VERSION ""

NS_ :

BS_:

BU_: HCM IPMA_ADAS PSCM GWM _delete SCCM PDM DDM GENERIC TSTR

BO_ 394 ACCDATA_3: 16 IPMA_ADAS
 SG_ AccTrgDist2_D_Dsply : 27|4@0+ (1,0) [0|15] "SED"  GWM
 SG_ AccStopRes_B_Dsply : 54|1@0+ (1,0) [0|1] "SED"  GWM
 SG_ TjaWarn_D_Rq : 50|3@0+ (1,0) [0|7] "SED"  GWM
 SG_ Tja_D_Stat : 44|3@0+ (1,0) [0|7] "SED"  GWM
 SG_ TjaMsgTxt_D_Dsply : 53|3@0+ (1,0) [0|7] "SED"  GWM
 SG_ IaccLamp_D_Rq : 46|2@0+ (1,0) [0|3] "SED"  GWM
 SG_ AccMsgTxt_D2_Rq : 31|4@0+ (1,0) [0|15] "SED"  GWM
 SG_ FcwDeny_B_Dsply : 10|1@0+ (1,0) [0|1] "SED"  GWM
 SG_ FcwMemStat_B_Actl : 13|1@0+ (1,0) [0|1] "SED"  GWM
 SG_ AccTGap_B_Dsply : 35|1@0+ (1,0) [0|1] "SED"  GWM
 SG_ CadsAlignIncplt_B_Actl : 11|1@0+ (1,0) [0|1] "SED"  GWM
 SG_ AccFllwMde_B_Dsply : 17|1@0+ (1,0) [0|1] "SED"  GWM
 SG_ CadsRadrBlck_B_Actl : 22|1@0+ (1,0) [0|1] "SED"  GWM
 SG_ CmbbPostEvnt_B_Dsply : 15|1@0+ (1,0) [0|1] "SED"  GWM
 SG_ AccStopMde_B_Dsply : 0|1@0+ (1,0) [0|1] "SED"  GWM
 SG_ FcwMemSens_D_Actl : 20|2@0+ (1,0) [0|3] "SED"  GWM
 SG_ FcwMsgTxt_D_Rq : 7|3@0+ (1,0) [0|7] "SED"  GWM
 SG_ AccWarn_D_Dsply : 39|2@0+ (1,0) [0|3] "SED"  GWM
 SG_ FcwVisblWarn_B_Rq : 47|1@0+ (1,0) [0|1] "SED"  GWM
 SG_ FcwAudioWarn_B_Rq : 8|1@0+ (1,0) [0|1] "SED"  GWM
 SG_ AccTGap_D_Dsply : 34|3@0+ (1,0) [0|7] "SED"  GWM
 SG_ AccMemEnbl_B_RqDrv : 36|1@0+ (1,0) [0|1] "SED"  GWM
 SG_ AccStopStat_D_Dsply : 41|2@0+ (1,0) [0|3] "SED"  GWM
 SG_ HaDsply_No_Cs : 63|8@0+ (1,0) [0|255] "unitless"  GWM
 SG_ HaDsply_No_Cnt : 4|4@0+ (1,0) [0|15] "unitless"  GWM

BO_ 391 ACCDATA_2: 16 IPMA_ADAS
 SG_ CmbbBrkDecel_No_Cnt : 47|4@0+ (1,0) [0|15] "unitless"  GWM
 SG_ HudDsplyIntns_No_Actl : 31|8@0+ (0.5,0) [0|100] "%"  GWM
 SG_ HudBlk3_B_Rq : 37|1@0+ (1,0) [0|1] "SED"  GWM
 SG_ HudBlk2_B_Rq : 51|1@0+ (1,0) [0|1] "SED"  GWM
 SG_ HudBlk1_B_Rq : 50|1@0+ (1,0) [0|1] "SED"  GWM
 SG_ HudFlashRate_D_Actl : 53|2@0+ (1,0) [0|3] "SED"  GWM
 SG_ CmbbBrkDecel_No_Cs : 7|8@0+ (1,0) [0|255] "unitless"  GWM
 SG_ CmbbBrkDecel_A_Rq : 12|13@0+ (0.0039,-20) [-20|11.9449] "m/s^2"  GWM
 SG_ CmbbBrkPrchg_D_Rq : 55|2@0+ (1,0) [0|3] "SED"  GWM
 SG_ CmbbBrkDecel_B_Rq : 15|1@0+ (1,0) [0|1] "SED"  GWM
 SG_ CmbbBaSens_D_Rq : 14|2@0+ (1,0) [0|3] "SED"  GWM

BO_ 390 ACCDATA: 16 IPMA_ADAS
 SG_ AccBrkTot_A_Rq : 4|13@0+ (0.0039,-20) [-20|11.9449] "m/s^2"  GWM
 SG_ AccPrpl_A_Pred : 17|10@0+ (0.01,-5) [-5|5.23] "m/s^2"  GWM
 SG_ AccVeh_V_Trg : 32|9@0+ (0.5,0) [0|255.5] "kph"  GWM
 SG_ AccBrkPrkEl_B_Rq : 38|1@0+ (1,0) [0|1] "SED"  GWM
 SG_ Cmbb_B_Enbl : 50|1@0+ (1,0) [0|1] "SED"  GWM
 SG_ CmbbOvrrd_B_RqDrv : 51|1@0+ (1,0) [0|1] "SED"  GWM
 SG_ CmbbDeny_B_Actl : 37|1@0+ (1,0) [0|1] "SED"  GWM
 SG_ CmbbEngTqMn_B_Rq : 52|1@0+ (1,0) [0|1] "SED"  GWM
 SG_ AccPrpl_A_Rq : 49|10@0+ (0.01,-5) [-5|5.23] "m/s^2"  GWM
 SG_ AccDeny_B_Rq : 53|1@0+ (1,0) [0|1] "SED"  GWM
 SG_ AccResumEnbl_B_Rq : 33|1@0+ (1,0) [0|1] "SED"  GWM
 SG_ AccCancl_B_Rq : 39|1@0+ (1,0) [0|1] "SED"  GWM
 SG_ AccBrkPrchg_B_Rq : 54|1@0+ (1,0) [0|1] "SED"  GWM
 SG_ AccBrkDecel_B_Rq : 55|1@0+ (1,0) [0|1] "SED"  GWM
 SG_ AccStopStat_B_Rq : 34|1@0+ (1,0) [0|1] "SED"  GWM
 SG_ AccAutoResum_D_Rq : 7|2@0+ (1,0) [0|3] "SED"  GWM
 SG_ AccBrkPulse_B_Rq : 36|1@0+ (1,0) [0|1] "SED"  GWM

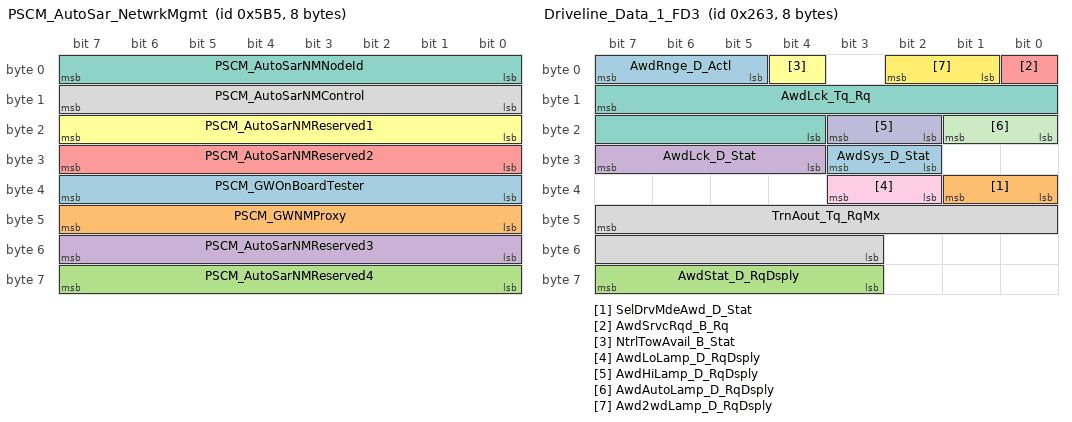
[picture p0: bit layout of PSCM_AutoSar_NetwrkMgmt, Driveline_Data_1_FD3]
BO_ 1461 PSCM_AutoSar_NetwrkMgmt: 8 PSCM
 SG_ PSCM_GWOnBoardTester : 39|8@0+ (1,0) [0|255] "unitless"  GENERIC,GWM
 SG_ PSCM_GWNMProxy : 47|8@0+ (1,0) [0|255] "unitless"  GENERIC,GWM
 SG_ PSCM_AutoSarNMReserved4 : 63|8@0+ (1,0) [0|255] "unitless"  GWM,GENERIC
 SG_ PSCM_AutoSarNMReserved3 : 55|8@0+ (1,0) [0|255] "unitless"  GENERIC,GWM
 SG_ PSCM_AutoSarNMReserved2 : 31|8@0+ (1,0) [0|255] "unitless"  GENERIC,GWM
 SG_ PSCM_AutoSarNMReserved1 : 23|8@0+ (1,0) [0|255] "unitless"  GENERIC,GWM
 SG_ PSCM_AutoSarNMNodeId : 7|8@0+ (1,0) [0|255] "unitless"  GENERIC,GWM
 SG_ PSCM_AutoSarNMControl : 15|8@0+ (1,0) [0|255] "unitless"  GWM,GENERIC

BO_ 130 EPAS_INFO: 16 PSCM
 SG_ TrlrHitchLamp_D_Rqst : 24|1@0+ (1,0) [0|1] "SED"  IPMA_ADAS,GWM
 SG_ VehVTrlrAid_B_Rq : 25|1@0+ (1,0) [0|1] "SED"  GWM
 SG_ SteEffort_D_Stat : 52|3@0+ (1,0) [0|7] "SED"  GWM
 SG_ Veh_V_RqMxTrlrAid : 63|8@0+ (0.1,0) [0|25.5] "km/h"  GWM
 SG_ SteMdule_D_Stat : 55|3@0+ (1,0) [0|7] "SED"  GWM
 SG_ SteMdule_U_Meas : 39|8@0+ (0.05,6) [6|18.7] "Volts"  GWM
 SG_ SteMdule_I_Est : 21|12@0+ (0.05,-64) [-64|140.7] "Amps"  GWM
 SG_ EPAS_Failure : 9|2@0+ (1,0) [0|3] "SED"  GWM,IPMA_ADAS
 SG_ SteeringColumnTorque : 7|8@0+ (0.0625,-8) [-8|7.8125] "Nm"  GWM,IPMA_ADAS
 SG_ SAPPAngleControlStat6 : 15|1@0+ (1,0) [0|1] "SED"  GWM,IPMA_ADAS
 SG_ SAPPAngleControlStat5 : 14|1@0+ (1,0) [0|1] "SED"  GWM,IPMA_ADAS
 SG_ SAPPAngleControlStat4 : 13|1@0+ (1,0) [0|1] "SED"  GWM,IPMA_ADAS
 SG_ SAPPAngleControlStat3 : 12|1@0+ (1,0) [0|1] "SED"  GWM,IPMA_ADAS
 SG_ SAPPAngleControlStat2 : 11|1@0+ (1,0) [0|1] "SED"  GWM,IPMA_ADAS
 SG_ SAPPAngleControlStat1 : 23|2@0+ (1,0) [0|3] "SED"  GWM,IPMA_ADAS

BO_ 1034 GGCC_Config_Mgmt_ID_1_FD3: 16 GWM
 SG_ VehicleGGCCData : 7|64@0+ (1,0) [0|1.84467E+019] "mixed"  SCCM,DDM,PDM,HCM,PSCM,IPMA_ADAS

BO_ 894 RemoteParkAssistStat_FD3: 16 GWM
 SG_ RmtCtlTrgtBody_D_Stat : 23|40@0+ (1,0) [0|1099511627775] "unitless" Vector__XXX
 SG_ RmtCtlTrgt_D_Rq : 11|2@0+ (1,0) [0|3] "SED" Vector__XXX
 SG_ RmtCtlRngSet_D_Stat : 13|2@0+ (1,0) [0|3] "SED" Vector__XXX
 SG_ RmtCtlKeySrch_D_Stat : 15|2@0+ (1,0) [0|3] "SED"  IPMA_ADAS
 SG_ RmtCtlBody_D_Stat : 4|4@0+ (1,0) [0|15] "SED"  IPMA_ADAS
 SG_ RmtCtl_D_RqBody : 7|3@0+ (1,0) [0|7] "SED" Vector__XXX

BO_ 611 Driveline_Data_1_FD3: 8 GWM
 SG_ AwdSys_D_Stat : 27|2@0+ (1,0) [0|3] "SED" Vector__XXX
 SG_ SelDrvMdeAwd_D_Stat : 33|2@0+ (1,0) [0|3] "SED" Vector__XXX
 SG_ AwdStat_D_RqDsply : 63|5@0+ (1,0) [0|31] "SED" Vector__XXX
 SG_ AwdLck_D_Stat : 31|4@0+ (1,0) [0|15] "SED" Vector__XXX
 SG_ AwdSrvcRqd_B_Rq : 0|1@0+ (1,0) [0|1] "SED" Vector__XXX
 SG_ NtrlTowAvail_B_Stat : 4|1@0+ (1,0) [0|1] "SED" Vector__XXX
 SG_ AwdLck_Tq_Rq : 15|12@0+ (1,0) [0|4093] "Nm" Vector__XXX
 SG_ TrnAout_Tq_RqMx : 47|13@0+ (1,-1250) [-1250|6941] "Nm" Vector__XXX
 SG_ AwdLoLamp_D_RqDsply : 35|2@0+ (1,0) [0|3] "SED" Vector__XXX
 SG_ AwdHiLamp_D_RqDsply : 19|2@0+ (1,0) [0|3] "SED" Vector__XXX
 SG_ AwdAutoLamp_D_RqDsply : 17|2@0+ (1,0) [0|3] "SED" Vector__XXX
 SG_ Awd2wdLamp_D_RqDsply : 2|2@0+ (1,0) [0|3] "SED" Vector__XXX
 SG_ AwdRnge_D_Actl : 7|3@0+ (1,0) [0|7] "SED"  IPMA_ADAS

BO_ 534 WheelData_FD3: 16 GWM
 SG_ WhlRotatRr_No_Cnt : 23|8@0+ (1,0) [0|255] "unitless"  IPMA_ADAS,PSCM
 SG_ WhlDirRr_D_Actl : 33|2@0+ (1,0) [0|3] "SED"  IPMA_ADAS,PSCM
 SG_ WhlDirRl_D_Actl : 39|2@0+ (1,0) [0|3] "SED"  IPMA_ADAS,PSCM
 SG_ WhlDirFr_D_Actl : 37|2@0+ (1,0) [0|3] "SED"  IPMA_ADAS,PSCM
 SG_ WhlDirFl_D_Actl : 35|2@0+ (1,0) [0|3] "SED"  IPMA_ADAS,PSCM
 SG_ WhlRotatRl_No_Cnt : 31|8@0+ (1,0) [0|255] "unitless"  IPMA_ADAS,PSCM
 SG_ WhlRotatFr_No_Cnt : 7|8@0+ (1,0) [0|255] "unitless"  IPMA_ADAS,PSCM
 SG_ WhlRotatFl_No_Cnt : 15|8@0+ (1,0) [0|255] "unitless"  IPMA_ADAS,PSCM

BO_ 533 APIM_Send_Signals_2_FD3: 8 GWM
 SG_ ExtLghtRvrseOn_B_Rq : 58|1@0+ (1,0) [0|1] "SED" Vector__XXX
 SG_ ClrExitAsstEnbl_D_RqMnu : 60|2@0+ (1,0) [0|3] "SED"  IPMA_ADAS
 SG_ TrlrAidMde_D_Rq : 5|2@0+ (1,0) [0|3] "SED"  PSCM
 SG_ TCU_Init_Actvtn_St : 1|2@0+ (1,0) [0|3] "SED" Vector__XXX
 SG_ TCU_Final_Actvtn_St : 3|2@0+ (1,0) [0|3] "SED" Vector__XXX
 SG_ OtaTrg_D_Stat : 41|2@0+ (1,0) [0|3] "SED" Vector__XXX
 SG_ OnbChrgGoTTouch_D_Rq : 43|2@0+ (1,0) [0|3] "SED" Vector__XXX
 SG_ OnbChrgGoTPrcond_D_Rq : 34|2@0+ (1,0) [0|3] "SED" Vector__XXX
 SG_ OnbChrgGoTOn_D_Rq : 25|2@0+ (1,0) [0|3] "SED" Vector__XXX
 SG_ OnbChrgGoTMnte_D_Rq : 47|4@0+ (1,0) [0|15] "minute" Vector__XXX
 SG_ OnbChrgGoTHr_T_Rq : 39|5@0+ (1,0) [0|29] "hour" Vector__XXX
 SG_ OnbChrgGoTExtHtr_D_Rq : 27|2@0+ (1,0) [0|3] "SED" Vector__XXX
 SG_ OnbChrgGoTElement_D_Rq : 31|4@0+ (1,0) [0|15] "unitless" Vector__XXX
 SG_ OnbChrgGoTDelete_B_Rq : 17|1@0+ (1,0) [0|1] "SED" Vector__XXX
 SG_ OnbChrgClearAll_B_Rq : 18|1@0+ (1,0) [0|1] "SED" Vector__XXX
 SG_ PaakMyKey_D_Rq : 7|2@0+ (1,0) [0|3] "SED" Vector__XXX
 SG_ DcacPw_D_Rq : 62|2@0+ (1,0) [0|3] "SED" Vector__XXX
 SG_ DcacPwReset_B_Rq : 63|1@0+ (1,0) [0|1] "SED" Vector__XXX
 SG_ AutoEpbZoomView_B_Stat : 32|1@0+ (1,0) [0|1] "SED" Vector__XXX
 SG_ AutoEpbButtn_B_Stat : 19|1@0+ (1,0) [0|1] "SED" Vector__XXX
 SG_ TrlrAlarmButtn_B_Stat : 50|1@0+ (1,0) [0|1] "SED" Vector__XXX
 SG_ LghtAmbDrvMde_D_Rq : 49|2@0+ (1,0) [0|3] "SED" Vector__XXX
 SG_ DcacPwLoButtn_B_Stat : 13|1@0+ (1,0) [0|1] "SED" Vector__XXX
 SG_ DcacPwOffButtn_B_Stat : 12|1@0+ (1,0) [0|1] "SED" Vector__XXX
 SG_ DcacPwHiButtn_B_Stat : 14|1@0+ (1,0) [0|1] "SED" Vector__XXX
 SG_ DcacPwResetButtn_B_Stat : 11|1@0+ (1,0) [0|1] "SED" Vector__XXX
 SG_ DcacPwButtn_B_Falt : 15|1@0+ (1,0) [0|1] "SED" Vector__XXX
 SG_ DcacMdeButtn_B_Stat : 8|1@0+ (1,0) [0|1] "SED" Vector__XXX
 SG_ DcacGfciTestBttn_B_Stat : 9|1@0+ (1,0) [0|1] "SED" Vector__XXX
 SG_ OnbChrgGoTUpdate_B_Rq : 16|1@0+ (1,0) [0|1] "SED" Vector__XXX
 SG_ DcacPwButtn_B_Stat : 10|1@0+ (1,0) [0|1] "SED" Vector__XXX
 SG_ TrlrHitch_D_RqMnu : 23|4@0+ (1,0) [0|15] "SED"  IPMA_ADAS
 SG_ TrlrBrkGain_No_Rq : 55|5@0+ (0.5,0) [0|15.5] "unitless" Vector__XXX

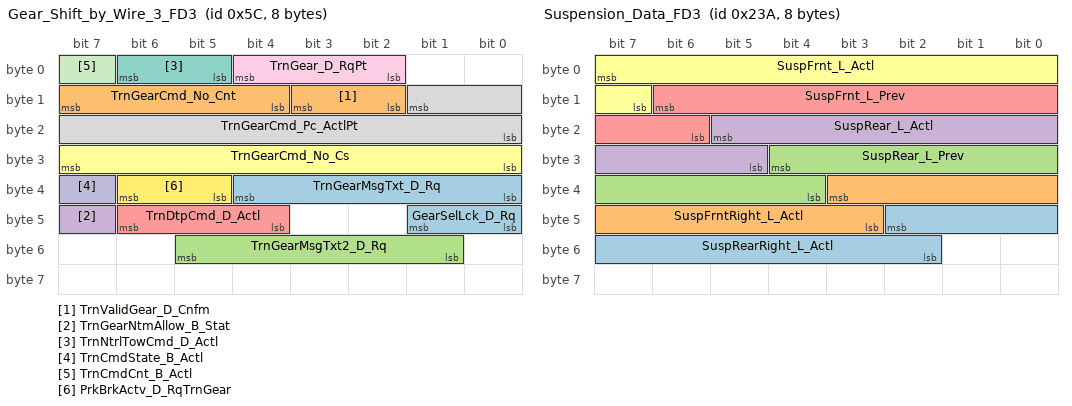
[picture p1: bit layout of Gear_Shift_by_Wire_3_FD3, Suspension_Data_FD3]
BO_ 92 Gear_Shift_by_Wire_3_FD3: 8 GWM
 SG_ GearSelLck_D_Rq : 41|2@0+ (1,0) [0|3] "SED"  _delete
 SG_ TrnValidGear_D_Cnfm : 11|2@0+ (1,0) [0|3] "SED"  _delete
 SG_ TrnGearMsgTxt2_D_Rq : 53|5@0+ (1,0) [0|31] "SED" Vector__XXX
 SG_ TrnGearNtmAllow_B_Stat : 47|1@0+ (1,0) [0|1] "SED" Vector__XXX
 SG_ TrnDtpCmd_D_Actl : 46|3@0+ (1,0) [0|7] "SED" Vector__XXX
 SG_ TrnGearCmd_No_Cs : 31|8@0+ (1,0) [0|255] "unitless" Vector__XXX
 SG_ TrnNtrlTowCmd_D_Actl : 6|2@0+ (1,0) [0|3] "SED"  IPMA_ADAS
 SG_ TrnGearCmd_Pc_ActlPt : 9|10@0+ (0.1,0) [0|102.2] "percent duty cycle" Vector__XXX
 SG_ TrnGear_D_RqPt : 4|3@0+ (1,0) [0|7] "SED" Vector__XXX
 SG_ TrnCmdState_B_Actl : 39|1@0+ (1,0) [0|1] "SED" Vector__XXX
 SG_ TrnCmdCnt_B_Actl : 7|1@0+ (1,0) [0|1] "unitless" Vector__XXX
 SG_ PrkBrkActv_D_RqTrnGear : 38|2@0+ (1,0) [0|3] "SED" Vector__XXX
 SG_ TrnGearMsgTxt_D_Rq : 36|5@0+ (1,0) [0|31] "SED" Vector__XXX
 SG_ TrnGearCmd_No_Cnt : 15|4@0+ (1,0) [0|15] "unitless" Vector__XXX

BO_ 1848 TesterPhysicalResPSCM: 64 PSCM
 SG_ TesterPhysicalResPSCM : 7|64@0+ (1,0) [0|1.84467E+019] "unitless"  TSTR

BO_ 1840 TesterPhysicalReqPSCM: 64 TSTR
 SG_ TesterPhysicalReqPSCM : 7|64@0+ (1,0) [0|1.84467E+019] "unitless"  PSCM

BO_ 570 Suspension_Data_FD3: 8 GWM
 SG_ SuspRearRight_L_Actl : 42|9@0+ (0.782779,-200) [-200|199.21729] "millimeter" Vector__XXX
 SG_ SuspFrntRight_L_Actl : 35|9@0+ (0.782779,-200) [-200|199.21729] "millimeter" Vector__XXX
 SG_ SuspRear_L_Prev : 28|9@0+ (0.782779,-200) [-200|199.21729] "millimeter"  HCM
 SG_ SuspRear_L_Actl : 21|9@0+ (0.782779,-200) [-200|199.21729] "millimeter"  HCM
 SG_ SuspFrnt_L_Prev : 14|9@0+ (0.782779,-200) [-200|199.21729] "millimeter"  HCM
 SG_ SuspFrnt_L_Actl : 7|9@0+ (0.782779,-200) [-200|199.21729] "millimeter"  HCM

BO_ 131 Steering_Data: 8 SCCM
 SG_ HeadLghtHiCtrl_D_RqAhb : 43|3@0+ (1,0) [0|7] "SED"  GWM,HCM,GENERIC
 SG_ AhbStat_B_Dsply : 33|1@0+ (1,0) [0|1] "SED"  GWM
 SG_ WiprFrontSwtch_D_Stat : 47|4@0+ (1,0) [0|15] "SED"  GWM
 SG_ HeadLghtHiOn_B_StatAhb : 34|1@0+ (1,0) [0|1] "SED"  GWM,IPMA_ADAS
 SG_ HeadLghtHiFlash_D_Actl : 36|2@0+ (1,0) [0|3] "SED"  GWM,IPMA_ADAS,HCM,GENERIC
 SG_ TjaButtnOnOffPress : 40|1@0+ (1,0) [0|1] "SED"  IPMA_ADAS,GWM
 SG_ AccButtnGapTogglePress : 32|1@0+ (1,0) [0|1] "SED"  GWM,IPMA_ADAS
 SG_ WiprFront_D_Stat : 3|4@0+ (1,0) [0|15] "SED"  HCM,GWM,IPMA_ADAS
 SG_ TurnLghtSwtch_D_Stat : 5|2@0+ (1,0) [0|3] "SED"  IPMA_ADAS,HCM,GWM,PSCM
 SG_ LghtAmb_D_Sns : 15|3@0+ (1,0) [0|7] "SED"  IPMA_ADAS,HCM,GWM
 SG_ AccButtnGapIncPress : 11|1@0+ (1,0) [0|1] "SED"  GWM,IPMA_ADAS
 SG_ AccButtnGapDecPress : 12|1@0+ (1,0) [0|1] "SED"  GWM,IPMA_ADAS
 SG_ AslButtnOnOffPress : 9|1@0+ (1,0) [0|1] "SED"  GWM
 SG_ AslButtnOnOffCnclPress : 10|1@0+ (1,0) [0|1] "SED"  GWM
 SG_ CcButtnOnPress : 37|1@0+ (1,0) [0|1] "SED"  GWM,IPMA_ADAS
 SG_ CcButtnOnOffPress : 38|1@0+ (1,0) [0|1] "SED"  GWM,IPMA_ADAS
 SG_ CcButtnOnOffCnclPress : 39|1@0+ (1,0) [0|1] "SED"  GWM,IPMA_ADAS
 SG_ CcButtnOffPress : 24|1@0+ (1,0) [0|1] "SED"  GWM,IPMA_ADAS
 SG_ CcAsllButtnResPress : 25|1@0+ (1,0) [0|1] "SED"  GWM,IPMA_ADAS
 SG_ CcAslButtnSetPress : 26|1@0+ (1,0) [0|1] "SED"  GWM
 SG_ CcAslButtnSetIncPress : 27|1@0+ (1,0) [0|1] "SED"  GWM,IPMA_ADAS
 SG_ CcAslButtnSetDecPress : 28|1@0+ (1,0) [0|1] "SED"  GWM,IPMA_ADAS
 SG_ CcAslButtnResIncPress : 29|1@0+ (1,0) [0|1] "SED"  GWM,IPMA_ADAS
 SG_ CcAslButtnResDecPress : 30|1@0+ (1,0) [0|1] "SED"  GWM
 SG_ CcAslButtnOnPress : 31|1@0+ (1,0) [0|1] "SED"  GWM,IPMA_ADAS
 SG_ CcAslButtnOnOffCncl : 16|1@0+ (1,0) [0|1] "SED"  GWM
 SG_ CcAslButtnOffCnclPress : 17|1@0+ (1,0) [0|1] "SED"  GWM
 SG_ CcAslButtnIndxIncPress : 18|1@0+ (1,0) [0|1] "SED"  GWM
 SG_ CcAslButtnIndxDecPress : 19|1@0+ (1,0) [0|1] "SED"  GWM
 SG_ CcAslButtnDeny_B_Actl : 20|1@0+ (1,0) [0|1] "SED"  GWM,IPMA_ADAS
 SG_ CcAslButtnCnclResPress : 21|1@0+ (1,0) [0|1] "SED"  GWM,IPMA_ADAS
 SG_ CcAslButtnCnclPress : 8|1@0+ (1,0) [0|1] "SED"  GWM,IPMA_ADAS
 SG_ LaSwtchPos_D_Stat : 23|2@0+ (1,0) [0|3] "SED"  GWM,IPMA_ADAS,GENERIC

BO_ 125 BrakeSnData_4_FD3: 16 GWM
 SG_ VehRolComp_W_Actl : 51|12@0+ (0.03663,-75) [-75|74.92659] "degrees/sec"  PSCM
 SG_ VehVertComp_A_Actl : 45|10@0+ (0.035,-17.9) [-17.9|17.835] "m/s^2"  PSCM
 SG_ BrkTotTqRqArb_No_Cs : 23|8@0+ (1,0) [0|255] "unitless" Vector__XXX
 SG_ BrkTotTqRqArb_No_Cnt : 31|4@0+ (1,0) [0|15] "unitless" Vector__XXX
 SG_ BrkTot_Tq_RqArb : 4|13@0+ (4,0) [0|32756] "Nm"  HCM,PSCM,IPMA_ADAS
 SG_ BrkTot_Tq_Actl : 27|13@0+ (4,0) [0|32756] "Nm"  PSCM
 SG_ HsaStat_D_Actl : 7|3@0+ (1,0) [0|7] "SED" Vector__XXX

BO_ 119 BrakeSnData_3_FD3: 16 GWM
 SG_ VehTrvlDir_D_Stat : 23|3@0+ (1,0) [0|7] "SED" Vector__XXX
 SG_ VehOverGnd_V_Est : 7|16@0+ (0.01,0) [0|655.33] "kph"  IPMA_ADAS,PSCM
 SG_ VehLongComp_A_Actl : 49|10@0+ (0.035,-17.9) [-17.9|17.835] "m/s^2"  HCM,PSCM
 SG_ VehLatComp_A_Actl : 43|10@0+ (0.035,-17.9) [-17.9|17.835] "m/s^2"  HCM,PSCM
 SG_ VehYawComp_W_Actl : 19|12@0+ (0.03663,-75) [-75|74.92659] "deg/s"  IPMA_ADAS,PSCM

BO_ 118 BrakeSnData_5_FD3: 16 GWM
 SG_ BrkCtrFnd_B_Stat : 39|1@0+ (1,0) [0|1] "SED"  GENERIC
 SG_ BrkTerrMdeChng_D_Rdy : 54|3@0+ (1,0) [0|7] "SED"  GENERIC
 SG_ BrkTerrMde_D_Actl : 38|3@0+ (1,0) [0|7] "SED"  GENERIC
 SG_ EmgcyBrkLamp_D_Rq : 21|2@0+ (1,0) [0|3] "SED"  GENERIC
 SG_ StopLamp_B_RqBrk : 7|1@0+ (1,0) [0|1] "SED"  GENERIC
 SG_ SteWhlCompAnEst_D_Qf : 23|2@0+ (1,0) [0|3] "SED" Vector__XXX
 SG_ SteWhlComp_An_Est : 6|15@0+ (0.1,-1600) [-1600|1676.7] "degrees" Vector__XXX

BO_ 1071 Engine_Clutch_Data_FD3: 16 GWM
 SG_ EngAout_N_Dsply : 52|13@0+ (2,0) [0|16382] "rpm"  _delete
 SG_ EngMnfld3_P_Actl : 47|8@0+ (10,0) [0|2530] "milibar"  _delete
 SG_ EngAoutIdl_N_Ntrl : 31|11@0+ (2,0) [0|4094] "rpm"  _delete
 SG_ CluPdl_PcRate_Actl : 7|8@0+ (0.04,-5) [-5|5.2] "%/ms" Vector__XXX
 SG_ CluPdlPosPcMeas_D_Qf : 11|2@0+ (1,0) [0|3] "SED"  HCM
 SG_ CluPdlPos_Pc_Meas : 9|10@0+ (0.1,0) [0|102.3] "%"  HCM

BO_ 942 ParkAid_Data2: 16 IPMA_ADAS
 SG_ ApaOffOptnSel_B_Avail : 51|1@0+ (1,0) [0|1] "SED"  GWM
 SG_ ApaSlotOption_B_Avail : 43|1@0+ (1,0) [0|1] "SED"  GWM
 SG_ ApaSlotAlrtSet_B_Stat : 44|1@0+ (1,0) [0|1] "SED"  GWM
 SG_ ApaSlotAlrt_B_Rq : 45|1@0+ (1,0) [0|1] "SED"  GWM
 SG_ ApaRmtFeatSel_B_Avail : 46|1@0+ (1,0) [0|1] "SED"  GWM
 SG_ ApaParkOutSel_B_Avail : 47|1@0+ (1,0) [0|1] "SED"  GWM
 SG_ ApaSys_D2_Stat : 35|4@0+ (1,0) [0|15] "SED"  GWM
 SG_ ApaSlotTrgt_D_Stat : 39|4@0+ (1,0) [0|15] "SED"  GWM
 SG_ ApaParkInSel_B_Avail : 24|1@0+ (1,0) [0|1] "SED"  GWM
 SG_ ApaMsgTxt_D2_Stat : 28|4@0+ (1,0) [0|15] "SED"  GWM
 SG_ ApaDynmcSlot_B_Stat : 29|1@0+ (1,0) [0|1] "SED"  GWM
 SG_ ApaDisplayMode_D_Stat : 31|2@0+ (1,0) [0|3] "SED"  GWM
 SG_ ApaControlMode_D_Stat : 16|1@0+ (1,0) [0|1] "SED"  GWM
 SG_ PrkBrkElRleas_B_RqApa : 50|1@0+ (1,0) [0|1] "SED"  GWM
 SG_ PrkAidAcsyRear_D_Stat : 18|2@0+ (1,0) [0|3] "SED"  GWM
 SG_ PrkAidAcsyFront_D_Stat : 20|2@0+ (1,0) [0|3] "SED"  GWM
 SG_ PrkAidRdiusRight_L_Dsply : 15|8@0+ (1,0) [0|255] "unitless"  GWM
 SG_ PrkAidRdiusLeft_L_Dsply : 7|8@0+ (1,0) [0|255] "unitless"  GWM
 SG_ PrkAidDrvDir_D_Stat : 23|3@0+ (1,0) [0|7] "SED"  GWM
 SG_ ApaDrvRq2MsgTxt_D_Rq : 55|4@0+ (1,0) [0|15] "SED"  GWM
 SG_ ApaDrvRq1MsgTxt_D_Rq : 42|3@0+ (1,0) [0|7] "SED"  GWM

BO_ 939 ParkAid_Aud_Warn_Stat2: 16 IPMA_ADAS
 SG_ DrTgateMde_D_Stat : 49|2@0+ (1,0) [0|3] "SED"  GWM
 SG_ SidePrkSnsR4_D_Stat : 55|4@0+ (1,0) [0|15] "SED"  GWM
 SG_ SidePrkSnsR3_D_Stat : 47|4@0+ (1,0) [0|15] "SED"  GWM
 SG_ SidePrkSnsL4_D_Stat : 43|4@0+ (1,0) [0|15] "SED"  GWM
 SG_ SidePrkSnsL3_D_Stat : 37|4@0+ (1,0) [0|15] "SED"  GWM
 SG_ PrkAidChime_D_Stat : 4|2@0+ (1,0) [0|3] "SED"  GWM
 SG_ PrkAidSnsRlCntr_D_Stat : 15|4@0+ (1,0) [0|15] "SED"  GWM
 SG_ PrkAidSnsRrCrnr_D_Stat : 31|4@0+ (1,0) [0|15] "SED"  GWM
 SG_ PrkAidSnsRrCntr_D_Stat : 19|4@0+ (1,0) [0|15] "SED"  GWM
 SG_ PrkAidSnsRlCrnr_D_Stat : 11|4@0+ (1,0) [0|15] "SED"  GWM
 SG_ PrkAidRear_D_Stat : 39|2@0+ (1,0) [0|3] "SED"  GWM
 SG_ PrkAidFront_D_Stat : 2|2@0+ (1,0) [0|3] "SED"  GWM
 SG_ PrkAid_D_Falt : 7|3@0+ (1,0) [0|7] "SED"  GWM
 SG_ ApaLongCtrlEnbl_D_Rq : 0|1@0+ (1,0) [0|1] "SED"  GWM
 SG_ ApaBrk_A_Rq : 63|8@0+ (0.05,-12.75) [-12.75|0] "m/sec^2"  GWM
 SG_ PrkAidLamp_D_Rq : 33|2@0+ (1,0) [0|3] "SED"  GWM
 SG_ ApaBrk_D_Rq : 51|2@0+ (1,0) [0|3] "SED"  GWM
 SG_ ResPrkAidSnsRrSide_D_Stat : 27|4@0+ (1,0) [0|15] "SED"  GWM
 SG_ ResPrkAidSnsRlSide_D_Stat : 23|4@0+ (1,0) [0|15] "SED"  GWM

BO_ 938 ParkAid_Aud_Warn_Stat: 16 IPMA_ADAS
 SG_ SidePrkSnsR2_D_Stat : 59|4@0+ (1,0) [0|15] "SED"  GWM
 SG_ SidePrkSnsR1_D_Stat : 63|4@0+ (1,0) [0|15] "SED"  GWM
 SG_ SidePrkSnsL2_D_Stat : 51|4@0+ (1,0) [0|15] "SED"  GWM
 SG_ ApaMde_D_Stat : 23|3@0+ (1,0) [0|7] "SED"  GWM
 SG_ ApaActvSd_D_Actl : 14|2@0+ (1,0) [0|3] "SED"  GWM
 SG_ PrkAidSwtch_B_Stat : 8|1@0+ (1,0) [0|1] "SED"  GWM
 SG_ ApaMde_D_Avail : 12|4@0+ (1,0) [0|15] "SED"  GWM
 SG_ PrkAidSnsFrCrnr_D_Stat : 47|4@0+ (1,0) [0|15] "SED"  GWM
 SG_ PrkAidSnsFrCntr_D_Stat : 35|4@0+ (1,0) [0|15] "SED"  GWM
 SG_ PrkAidSnsFlCrnr_D_Stat : 27|4@0+ (1,0) [0|15] "SED"  GWM
 SG_ PrkAidSnsFlCntr_D_Stat : 31|4@0+ (1,0) [0|15] "SED"  GWM
 SG_ PrkBrkEl_B_RqFap : 20|1@0+ (1,0) [0|1] "SED"  GWM
 SG_ RpaChime_D_Rq : 7|4@0+ (1,0) [0|15] "SED"  GWM
 SG_ FpaChime_D_Rq : 3|4@0+ (1,0) [0|15] "SED"  GWM
 SG_ PrkAidMsgTxt_D_Rq : 19|4@0+ (1,0) [0|15] "SED"  PSCM,GWM
 SG_ SidePrkSnsL1_D_Stat : 55|4@0+ (1,0) [0|15] "SED"  GWM
 SG_ PrkAidAudioMute_B_Rq : 15|1@0+ (1,0) [0|1] "SED"  GWM

BO_ 937 ParkAid_Data_2: 16 IPMA_ADAS
 SG_ Veh_V_RqFap : 31|8@0+ (0.1,0) [0|25.5] "km/h"  GWM
 SG_ TrnRngDRqFap_No_Cs : 23|8@0+ (1,0) [0|255] "unitless"  GWM
 SG_ TrnRngDRqFap_No_Cnt : 15|4@0+ (1,0) [0|15] "unitless"  GWM
 SG_ TrnRng_D_RqFap : 11|3@0+ (1,0) [0|7] "SED"  GWM
 SG_ FapLcDistToObj_L_Actl : 7|8@0+ (0.01,0) [0|2.53] "meter"  GWM

BO_ 936 ParkAid_Data: 16 IPMA_ADAS
 SG_ ApaSys_D_Stat : 61|3@0+ (1,0) [0|7] "SED"  PSCM,GWM
 SG_ ApaSteWhl_D_RqDrv : 63|2@0+ (1,0) [0|3] "SED"  GWM
 SG_ ApaSteScanMde_D_Stat : 49|2@0+ (1,0) [0|3] "SED"  GWM
 SG_ ApaSelSapp_D_Stat : 51|2@0+ (1,0) [0|3] "SED"  GWM
 SG_ ApaSelPpa_D_Stat : 53|2@0+ (1,0) [0|3] "SED"  GWM
 SG_ ApaSelPoa_D_Stat : 55|2@0+ (1,0) [0|3] "SED"  GWM
 SG_ ApaScan_D_Stat : 41|2@0+ (1,0) [0|3] "SED"  GWM
 SG_ ApaLongCtl_D_RqDrv : 44|3@0+ (1,0) [0|7] "SED"  GWM
 SG_ ApaGearShif_D_RqDrv : 47|3@0+ (1,0) [0|7] "SED"  GWM
 SG_ ApaActvSide2_D_Stat : 33|2@0+ (1,0) [0|3] "SED"  GWM
 SG_ ApaAcsy_D_RqDrv : 36|3@0+ (1,0) [0|7] "SED"  GWM
 SG_ ApaTrgtDist_D_Stat : 11|4@0+ (1,0) [0|15] "SED"  GWM
 SG_ ApaMsgTxt_D_Rq : 15|4@0+ (1,0) [0|15] "SED"  GWM
 SG_ ApaChime_D_Rq : 39|3@0+ (1,0) [0|7] "SED"  GWM
 SG_ SAPPStatusCoding : 7|8@0+ (1,0) [0|255] "unitless"  PSCM,GWM
 SG_ EPASExtAngleStatReq : 23|1@0+ (1,0) [0|1] "SED"  PSCM,GWM
 SG_ ExtSteeringAngleReq2 : 22|15@0+ (0.1,-1000) [-1000|2276.5] "degrees"  PSCM,GWM
 SG_ ApaButtnPrssd_B_Stat : 58|1@0+ (1,0) [0|1] "SED"  PSCM,GWM

BO_ 154 TripResetSyncMessage_FD3: 12 GWM
 SG_ TronTripCnt_No_Actl : 7|23@0+ (1,0) [0|8388605] "unitless"  DDM,PDM,HCM,IPMA_ADAS,PSCM
 SG_ TronResetCnt_No_Actl : 16|22@0+ (1,0) [0|4194301] "unitless"  DDM,PDM,HCM,IPMA_ADAS,PSCM

BO_ 2614099160 SymKeyFuncGWM_ECG_FD3: 64 GWM
 SG_ SymKeyFuncGWM_ECG : 7|29@0+ (1,0) [0|536870911] "unitless"  HCM,DDM,PDM,IPMA_ADAS,PSCM,SCCM

BO_ 2613272609 SymKeyPhysIPMAtoGWM_ECG: 64 IPMA_ADAS
 SG_ SymKeyPhysIPMAtoGWM_ECG : 7|29@0+ (1,0) [0|536870911] "unitless"  GWM

BO_ 2613085400 SymKeyPhysGWM_ECGtoIPMA: 64 GWM
 SG_ SymKeyPhysGWM_ECGtoIPMA : 7|29@0+ (1,0) [0|536870911] "unitless"  IPMA_ADAS

BO_ 2613272624 SymKeyPhysPSCMtoGWM_ECG: 64 PSCM
 SG_ SymKeyPhysPSCMtoGWM_ECG : 7|29@0+ (1,0) [0|536870911] "unitless"  GWM

BO_ 2613100760 SymKeyPhysGWM_ECGtoPSCM: 64 GWM
 SG_ SymKeyPhysGWM_ECGtoPSCM : 7|29@0+ (1,0) [0|536870911] "unitless"  PSCM

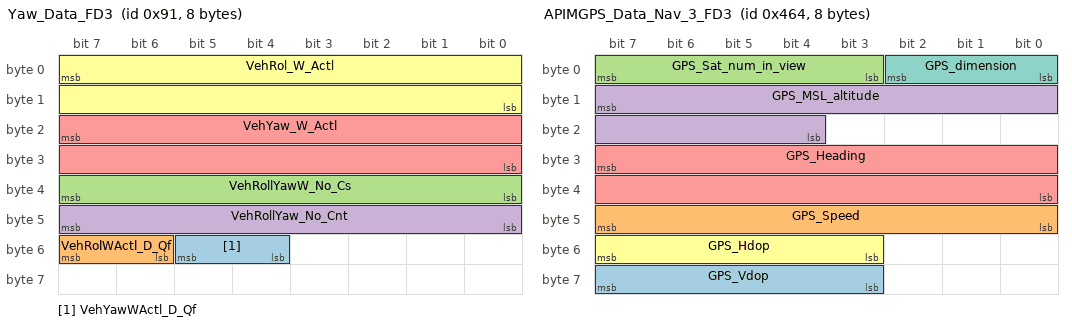
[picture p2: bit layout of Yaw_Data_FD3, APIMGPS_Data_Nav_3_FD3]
BO_ 145 Yaw_Data_FD3: 8 GWM
 SG_ VehYawWActl_D_Qf : 53|2@0+ (1,0) [0|3] "SED"  HCM,IPMA_ADAS
 SG_ VehRolWActl_D_Qf : 55|2@0+ (1,0) [0|3] "SED"  IPMA_ADAS
 SG_ VehRollYawW_No_Cs : 39|8@0+ (1,0) [0|255] "unitless"  IPMA_ADAS
 SG_ VehRollYaw_No_Cnt : 47|8@0+ (1,0) [0|255] "unitless"  IPMA_ADAS
 SG_ VehYaw_W_Actl : 23|16@0+ (0.0002,-6.5) [-6.5|6.6066] "rad/s"  HCM,IPMA_ADAS,PSCM
 SG_ VehRol_W_Actl : 7|16@0+ (0.0002,-6.5) [-6.5|6.6066] "rad/s"  IPMA_ADAS,PSCM

BO_ 2612224099 PARSEDPushSODRtoGWM_ECG: 8 IPMA_ADAS
 SG_ PARSEDPushSODRtoGWM_ECG : 7|29@0+ (1,0) [0|536870911] "unitless"  GWM

BO_ 2612224098 PARSEDPushSODLtoGWM_ECG: 8 IPMA_ADAS
 SG_ PARSEDPushSODLtoGWM_ECG : 7|29@0+ (1,0) [0|536870911] "unitless"  GWM

BO_ 2612224070 PARSEDPushSODCMDtoECG: 8 IPMA_ADAS
 SG_ PARSEDPushSODCMDtoECG : 7|29@0+ (1,0) [0|536870911] "unitless"  GWM

BO_ 535 WheelSpeed_FD3: 16 GWM
 SG_ WhlRr_W_Meas : 54|15@0+ (0.01,0) [0|327.65] "rad/s"  IPMA_ADAS,PSCM
 SG_ WhlRl_W_Meas : 38|15@0+ (0.01,0) [0|327.65] "rad/s"  IPMA_ADAS,PSCM
 SG_ WhlFr_W_Meas : 22|15@0+ (0.01,0) [0|327.65] "rad/s"  IPMA_ADAS,PSCM
 SG_ WhlFl_W_Meas : 6|15@0+ (0.01,0) [0|327.65] "rad/s"  IPMA_ADAS,PSCM

BO_ 2612224069 PARSEDPushSODCMCtoECG: 8 IPMA_ADAS
 SG_ PARSEDPushSODCMCtoECG : 7|29@0+ (1,0) [0|536870911] "unitless"  GWM

BO_ 2612224048 PARSEDPushPSCMtoGWM_ECG: 8 PSCM
 SG_ PARSEDPushPSCMtoGWM_ECG : 7|29@0+ (1,0) [0|536870911] "unitless"  GWM

BO_ 2612224033 PARSEDPushIPMAtoGWM_ECG: 8 IPMA_ADAS
 SG_ PARSEDPushIPMAtoGWM_ECG : 7|29@0+ (1,0) [0|536870911] "unitless"  GWM

BO_ 2612224113 PARSEDPushHCMtoGWM_ECG: 8 HCM
 SG_ PARSEDPushHCMtoGWM_ECG : 7|29@0+ (1,0) [0|536870911] "unitless"  GWM

BO_ 2612104408 PARSEDPushFcGWM_ECGtoSODR: 8 GWM
 SG_ PARSEDPushFcGWM_ECGtoSODR : 7|29@0+ (1,0) [0|536870911] "unitless"  IPMA_ADAS

BO_ 2612103384 PARSEDPushFcGWM_ECGtoSODL: 8 GWM
 SG_ PARSEDPushFcGWM_ECGtoSODL : 7|29@0+ (1,0) [0|536870911] "unitless"  IPMA_ADAS

BO_ 2612074712 PARSEDPushFcGWMtoSODCMD: 8 GWM
 SG_ PARSEDPushFcECGtoSODCMD : 7|29@0+ (1,0) [0|536870911] "unitless"  IPMA_ADAS

BO_ 2612118744 PARSEDPushFcGWM_ECGtoHCM: 8 GWM
 SG_ PARSEDPushFcGWM_ECGtoHCM : 7|29@0+ (1,0) [0|536870911] "unitless"  HCM

BO_ 2610982104 PARSEDPhysGWM_ECGtoGSM: 64 GWM
 SG_ PARSEDPhysGWM_ECGtoGSM : 7|29@0+ (1,0) [0|536870911] "unitless" Vector__XXX

BO_ 2612052184 PARSEDPushFcGWM_ECGtoPSCM: 8 GWM
 SG_ PARSEDPushFcGWM_ECGtoPSCM : 7|29@0+ (1,0) [0|536870911] "unitless"  PSCM

BO_ 2612036824 PARSEDPushFcGWM_ECGtoIPMA: 8 GWM
 SG_ PARSEDPushFcGWM_ECGtoIPMA : 7|29@0+ (1,0) [0|536870911] "unitless"  IPMA_ADAS

BO_ 1124 APIMGPS_Data_Nav_3_FD3: 8 GWM
 SG_ GPS_Vdop : 63|5@0+ (0.2,0) [0|5.8] "unitless" Vector__XXX
 SG_ GPS_Speed : 47|8@0+ (1,0) [0|253] "MPH" Vector__XXX
 SG_ GPS_Sat_num_in_view : 7|5@0+ (1,0) [0|29] "unitless" Vector__XXX
 SG_ GPS_MSL_altitude : 15|12@0+ (10,-20460) [-20460|20470] "feet" Vector__XXX
 SG_ GPS_Heading : 31|16@0+ (0.01,0) [0|655.33] "degrees" Vector__XXX
 SG_ GPS_Hdop : 55|5@0+ (0.2,0) [0|5.8] "unitless" Vector__XXX
 SG_ GPS_dimension : 2|3@0+ (1,0) [0|7] "SED" Vector__XXX

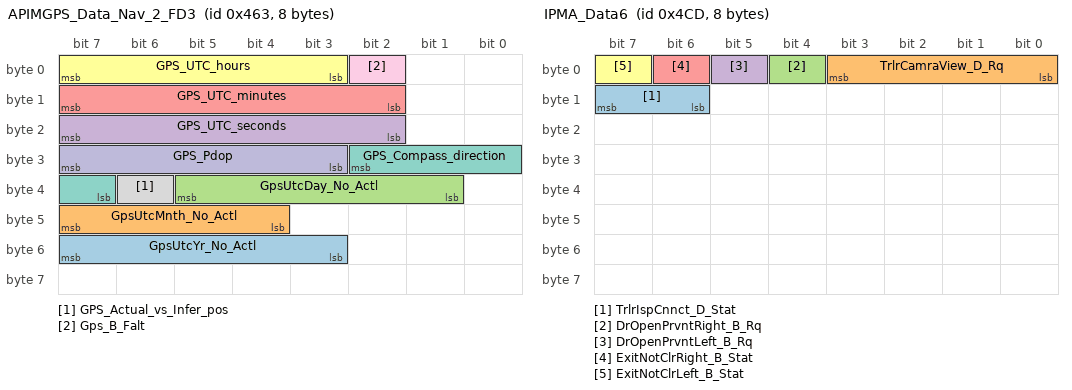
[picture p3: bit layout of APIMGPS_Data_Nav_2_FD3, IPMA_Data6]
BO_ 1123 APIMGPS_Data_Nav_2_FD3: 8 GWM
 SG_ GpsUtcYr_No_Actl : 55|5@0+ (1,2010) [2010|2040] "Year" Vector__XXX
 SG_ GpsUtcMnth_No_Actl : 47|4@0+ (1,1) [1|15] "Month" Vector__XXX
 SG_ GpsUtcDay_No_Actl : 37|5@0+ (1,1) [1|32] "day" Vector__XXX
 SG_ GPS_UTC_seconds : 23|6@0+ (1,0) [0|59] "seconds" Vector__XXX
 SG_ GPS_UTC_minutes : 15|6@0+ (1,0) [0|59] "minute" Vector__XXX
 SG_ GPS_UTC_hours : 7|5@0+ (1,0) [0|23] "Hours" Vector__XXX
 SG_ GPS_Compass_direction : 26|4@0+ (1,0) [0|15] "SED" Vector__XXX
 SG_ GPS_Actual_vs_Infer_pos : 38|1@0+ (1,0) [0|1] "SED" Vector__XXX
 SG_ Gps_B_Falt : 2|1@0+ (1,0) [0|1] "SED" Vector__XXX
 SG_ GPS_Pdop : 31|5@0+ (0.2,0) [0|5.8] "unitless" Vector__XXX

BO_ 2612030680 PARSEDPushFcGWM_ECGtoGSM: 8 GWM
 SG_ PARSEDPushFcGWM_ECGtoGSM : 7|29@0+ (1,0) [0|536870911] "unitless" Vector__XXX

BO_ 531 DesiredTorqBrk_FD3: 16 GWM
 SG_ VehStop_D_Stat : 28|2@0+ (1,0) [0|3] "SED"  IPMA_ADAS
 SG_ TracCtlPtActv_B_Actl : 31|1@0+ (1,0) [0|1] "SED"  IPMA_ADAS
 SG_ PrkBrkYwLamp_D_Rq : 38|2@0+ (1,0) [0|3] "SED" Vector__XXX
 SG_ PrkBrkRedLamp_D_Rq : 30|2@0+ (1,0) [0|3] "SED" Vector__XXX
 SG_ VehicleStationary : 39|1@0+ (1,0) [0|1] "SED" Vector__XXX
 SG_ AbsActv_B_Actl : 45|1@0+ (1,0) [0|1] "SED"  IPMA_ADAS,PSCM
 SG_ StabCtlBrkActv_B_Actl : 23|1@0+ (1,0) [0|1] "SED"  IPMA_ADAS,PSCM
 SG_ CmbbBrkPrchg_B_Actl : 59|1@0+ (1,0) [0|1] "SED"  IPMA_ADAS
 SG_ CmbbBrkDecel_B_Actl : 58|1@0+ (1,0) [0|1] "SED"  IPMA_ADAS
 SG_ CmbbBaSensInc_B_Actl : 57|1@0+ (1,0) [0|1] "SED"  IPMA_ADAS
 SG_ AccBrkWarm_B_Actl : 63|1@0+ (1,0) [0|1] "SED"  IPMA_ADAS
 SG_ AccBrkTotTqMn_B_Actl : 62|1@0+ (1,0) [0|1] "SED"  IPMA_ADAS
 SG_ AccBrkPrchgActv_B_Actl : 61|1@0+ (1,0) [0|1] "SED"  IPMA_ADAS
 SG_ AccBrkDis_B_Actl : 44|1@0+ (1,0) [0|1] "SED"  IPMA_ADAS
 SG_ AccBrkDeny_B_Actl : 42|1@0+ (1,0) [0|1] "SED"  IPMA_ADAS
 SG_ AccBrkActv_B_Actl : 43|1@0+ (1,0) [0|1] "SED"  IPMA_ADAS
 SG_ PrplDrgCtlActv_B_Actl : 46|1@0+ (1,0) [0|1] "SED" Vector__XXX
 SG_ PrplWhlTot_Tq_RqMx : 7|16@0+ (4,-131072) [-131072|131068] "Nm" Vector__XXX
 SG_ CmbbBrkDis_B_Actl : 56|1@0+ (1,0) [0|1] "SED"  PSCM,IPMA_ADAS
 SG_ CmbbDeny_B_ActlBrk : 60|1@0+ (1,0) [0|1] "SED"  PSCM,IPMA_ADAS
 SG_ CcDis_B_Cmd : 47|1@0+ (1,0) [0|1] "SED" Vector__XXX
 SG_ VehLongOvrGnd_A_Est : 41|10@0+ (0.035,-17.9) [-17.9|17.835] "m/s^2"  IPMA_ADAS
 SG_ AccStopActv_B_ActlBrk : 22|1@0+ (1,0) [0|1] "SED"  IPMA_ADAS
 SG_ AccDis_B_ActlEpb : 32|1@0+ (1,0) [0|1] "SED"  IPMA_ADAS
 SG_ PrkBrkMsgTxt_D_Rq : 36|4@0+ (1,0) [0|15] "SED" Vector__XXX
 SG_ PrkBrkStatus : 26|3@0+ (1,0) [0|7] "SED"  IPMA_ADAS

BO_ 517 PowertrainData_6_FD3: 16 GWM
 SG_ TrnAin_Pc_RqDrv : 9|10@0+ (0.1,0) [0|102.3] "percent"  _delete
 SG_ FapLc_B_Err : 10|1@0+ (1,0) [0|1] "SED"  IPMA_ADAS
 SG_ BrkTot_Tq_RqFapLc : 7|13@0+ (4,0) [0|32764] "Nm" Vector__XXX

BO_ 516 EngVehicleSpThrottle_FD3: 16 GWM
 SG_ ApedPosPcActl_No_Cs : 47|8@0+ (1,0) [0|255] "unitless"  _delete
 SG_ EngAoutNActl_D_QF : 31|2@0+ (1,0) [0|3] "SED"  _delete
 SG_ ApedPos_PcRate_ActlArb : 23|8@0+ (0.04,-5) [-5|5.12] "%/ms"  _delete
 SG_ ApedPosPcActl_No_Cnt : 5|4@0+ (1,0) [0|15] "unitless"  _delete
 SG_ ApedPos_Pc_ActlArb : 1|10@0+ (0.1,0) [0|102.3] "%"  HCM,IPMA_ADAS,PSCM
 SG_ ApedPosPcActl_D_Qf : 7|2@0+ (1,0) [0|3] "SED"  HCM,PSCM,IPMA_ADAS
 SG_ EngAout_N_Actl : 28|13@0+ (2,0) [0|16382] "rpm"  HCM,PSCM

BO_ 514 EngVehicleSpThrottle2_FD3: 16 GWM
 SG_ StrtrMtrDlyStrt_B_Stat : 39|1@0+ (1,0) [0|1] "SED"  _delete
 SG_ VehVActlEng_No_Cnt : 22|4@0+ (1,0) [0|15] "unitless"  _delete
 SG_ VehVActlEng_No_Cs : 15|8@0+ (1,0) [0|255] "unitless"  _delete
 SG_ StrtrMtrCtlMsgTxt_D2_Rq : 1|2@0+ (1,0) [0|3] "SED"  _delete
 SG_ StrtrMtrCtlMsgTxt_D_Rq : 7|3@0+ (1,0) [0|7] "SED"  _delete
 SG_ VehVTrlrAid_B_Avail : 23|1@0+ (1,0) [0|1] "SED"  PSCM
 SG_ Veh_V_RqCcSet : 32|9@0+ (0.5,0) [0|255.5] "kph"  IPMA_ADAS
 SG_ VehVActlEng_D_Qf : 38|2@0+ (1,0) [0|3] "SED"  SCCM,DDM,PDM,HCM,IPMA_ADAS
 SG_ Veh_V_ActlEng : 55|16@0+ (0.01,0) [0|655.35] "kph"  SCCM,DDM,PDM,HCM,IPMA_ADAS
 SG_ GearRvrse_D_Actl : 4|3@0+ (1,0) [0|7] "SED"  SCCM,PDM,DDM,HCM,IPMA_ADAS,PSCM

BO_ 512 TorqueDataEngFlags_FD3: 16 GWM
 SG_ PrplWhlTot_Tq_Rq : 39|16@0+ (4,-131072) [-131072|131068] "Nm"  _delete
 SG_ PrplWhlTot_Tq_LimMn : 23|16@0+ (4,-131072) [-131072|131068] "Nm"  _delete
 SG_ PtDrvMde_D_Stat : 55|4@0+ (1,0) [0|15] "SED"  IPMA_ADAS

BO_ 376 EngineClimateData_FD3: 16 GWM
 SG_ AirAmb_P_Actl : 55|6@0+ (10,500) [500|1110] "mbar"  _delete
 SG_ AslChime_B_Rq : 39|1@0+ (1,0) [0|1] "SED"  _delete
 SG_ EngAout_Aa_Actl : 17|10@0+ (0.05,-25.6) [-25.6|25.55] "rpm/ms"  _delete
 SG_ EcssLamp_D_RqDsply : 19|2@0+ (1,0) [0|3] "SED"  _delete
 SG_ AslIconDsply_D_Rq : 3|2@0+ (1,0) [0|3] "SED"  _delete
 SG_ DynoMde_B_Cmd : 4|1@0+ (1,0) [0|1] "SED"  _delete
 SG_ GasPrtc_D_RqDsply : 22|3@0+ (1,0) [0|7] "SED" Vector__XXX
 SG_ AirAmbTe_D_Qf : 35|2@0+ (1,0) [0|3] "SED"  SCCM,IPMA_ADAS
 SG_ AirAmb_Te_ActlFilt : 49|10@0+ (0.25,-128) [-128|127.75] "degC"  IPMA_ADAS
 SG_ AirAmb_Te_Actl : 33|10@0+ (0.25,-128) [-128|127.75] "degC"  SCCM

BO_ 1229 IPMA_Data6: 8 IPMA_ADAS
 SG_ TrlrIspCnnct_D_Stat : 15|2@0+ (1,0) [0|3] "SED" Vector__XXX
 SG_ TrlrCamraView_D_Rq : 3|4@0+ (1,0) [0|15] "SED" Vector__XXX
 SG_ DrOpenPrvntRight_B_Rq : 4|1@0+ (1,0) [0|1] "SED"  GWM
 SG_ DrOpenPrvntLeft_B_Rq : 5|1@0+ (1,0) [0|1] "SED"  GWM
 SG_ ExitNotClrRight_B_Stat : 6|1@0+ (1,0) [0|1] "SED"  GWM
 SG_ ExitNotClrLeft_B_Stat : 7|1@0+ (1,0) [0|1] "SED"  GWM

CM_ SG_ 394 HaDsply_No_Cs "Signal not transmitted on gas variants.";
CM_ SG_ 394 HaDsply_No_Cnt "Signal not transmitted on gas variants.";
CM_ SG_ 391 CmbbBrkDecel_A_Rq "ABSGenSigTimeoutTime=1000";
CM_ SG_ 391 CmbbBrkPrchg_D_Rq "ABSGenSigTimeoutTime=1000";
CM_ SG_ 391 CmbbBrkDecel_B_Rq "ABSGenSigTimeoutTime=1000";
CM_ SG_ 391 CmbbBaSens_D_Rq "ABSGenSigTimeoutTime=1000";
CM_ SG_ 390 AccBrkTot_A_Rq "ABSGenSigTimeoutTime=1000";
CM_ SG_ 390 AccBrkPrkEl_B_Rq "ABSGenSigTimeoutTime=1000";
CM_ SG_ 390 AccPrpl_A_Rq "PCMGenSigTimeoutTime=1000";
CM_ SG_ 390 AccBrkPrchg_B_Rq "ABSGenSigTimeoutTime=1000";
CM_ SG_ 390 AccBrkDecel_B_Rq "ABSGenSigTimeoutTime=1000";
CM_ SG_ 390 AccStopStat_B_Rq "ABSGenSigTimeoutTime=1000";
CM_ BO_ 130 "drecker 10/23/09 Need SAPP in sync w/Strg Torque for proper PAM interpretation, else fault msg's displayed FP@20ms IPC needs EPAS_Failure for msg to driver.  Not map w/Lane Assist FP@30s FP), save bandwidth if feature not on vehicle ";
CM_ SG_ 130 VehVTrlrAid_B_Rq "VR session start- req. limit blower speed no more than X volts.  CC restriction on time msg. will be honored.Double Event msg1st event to request limit, 2nd event to release limit, No msg. CC Grammar v7.xls";
CM_ SG_ 130 SteMdule_U_Meas "DCR 1745  to update Tx from GWM to EP100ms. SteMdule_I_Est & SteMdule_U_Meas are used by BMS system & filtered. The filter uses standard periodic rate & changing to EP would adversely affect the filter.(jweinfur)";
CM_ SG_ 130 SteMdule_I_Est "DCR 1745  to update Tx from GWM to EP100ms. SteMdule_I_Est & SteMdule_U_Meas are used by BMS system & filtered. The filter uses standard periodic rate & changing to EP would adversely affect the filter.(jweinfur)";
CM_ SG_ 1034 VehicleGGCCData "RCMGenSigTimeout=6000";
CM_ BO_ 611 "Used on Applications with 4x4 supplied by Motorola.";
CM_ SG_ 611 AwdStat_D_RqDsply "Signal not transmitted on programs that do not have AWD.";
CM_ SG_ 611 AwdSrvcRqd_B_Rq "Signal not transmitted on programs that do not have AWD.";
CM_ SG_ 611 AwdLck_Tq_Rq "Signal not transmitted on programs that do not have AWD.";
CM_ SG_ 534 WhlRotatRr_No_Cnt "DCR 1833 to update Tx from GWM to EP100ms. Wheel Count signals are used by complex algorithm to determine Tire Pressure by Location & can't change from 20msec. (jweinfur)";
CM_ SG_ 534 WhlRotatRl_No_Cnt "DCR 1833 to update Tx from GWM to EP100ms. Wheel Count signals are used by complex algorithm to determine Tire Pressure by Location & can't change from 20msec. (jweinfur)";
CM_ SG_ 534 WhlRotatFr_No_Cnt "DCR 1833 to update Tx from GWM to EP100ms. Wheel Count signals are used by complex algorithm to determine Tire Pressure by Location & can't change from 20msec. (jweinfur)";
CM_ SG_ 534 WhlRotatFl_No_Cnt "DCR 1833 to update Tx from GWM to EP100ms. Wheel Count signals are used by complex algorithm to determine Tire Pressure by Location & can't change from 20msec. (jweinfur)";
CM_ SG_ 92 TrnValidGear_D_Cnfm "Signal not transmitted on vehicles that do not have shift by wire.";
CM_ SG_ 92 TrnGearMsgTxt2_D_Rq "Signal not transmitted on vehicles that do not have shift by wire.";
CM_ SG_ 92 TrnGearNtmAllow_B_Stat "Signal not transmitted on vehicles that do not have shift by wire.";
CM_ SG_ 92 TrnDtpCmd_D_Actl "Signal not transmitted on vehicles that do not have shift by wire.";
CM_ SG_ 92 TrnGearCmd_No_Cs "Signal not transmitted on vehicles that do not have shift by wire.";
CM_ SG_ 92 TrnNtrlTowCmd_D_Actl "Signal not transmitted on vehicles that do not have shift by wire.";
CM_ SG_ 92 TrnGearCmd_Pc_ActlPt "Signal not transmitted on vehicles that do not have shift by wire.";
CM_ SG_ 92 TrnGear_D_RqPt "Signal not transmitted on vehicles that do not have shift by wire.";
CM_ SG_ 92 TrnCmdState_B_Actl "Signal not transmitted on vehicles that do not have shift by wire.";
CM_ SG_ 92 TrnCmdCnt_B_Actl "Signal not transmitted on vehicles that do not have shift by wire.";
CM_ SG_ 92 PrkBrkActv_D_RqTrnGear "Signal not transmitted on vehicles that do not have shift by wire.";
CM_ SG_ 92 TrnGearMsgTxt_D_Rq "Signal not transmitted on vehicles that do not have shift by wire.";
CM_ SG_ 92 TrnGearCmd_No_Cnt "Signal not transmitted on vehicles that do not have shift by wire.";
CM_ SG_ 118 SteWhlCompAnEst_D_Qf "Legacy signal not supported, reserving bit locations for commodity BCM, PAM, RCM, APIM dbc files.  GWM to Tx Init value, no valid data. ";
CM_ SG_ 118 SteWhlComp_An_Est "Legacy signal not supported, reserving bit locations for commodity BCM, PAM, RCM, APIM dbc files.  GWM to Tx Init value, no valid data. ";
CM_ SG_ 1071 EngAoutIdl_N_Ntrl "Signal not transmitted on HEV variants and diesel.";
CM_ SG_ 1071 CluPdl_PcRate_Actl "Signal not transmitted on HEV variants.";
CM_ SG_ 1071 CluPdlPosPcMeas_D_Qf "Signal not transmitted on HEV variants.";
CM_ SG_ 1071 CluPdlPos_Pc_Meas "Signal not transmitted on HEV variants.";
CM_ SG_ 942 PrkAidRdiusRight_L_Dsply "MSGDCR 679, set all signals to OnChange";
CM_ SG_ 942 PrkAidRdiusLeft_L_Dsply "MSGDCR 679, set all signals to OnChange";
CM_ SG_ 942 PrkAidDrvDir_D_Stat "MSGDCR 679, set all signals to OnChange";
CM_ SG_ 145 VehYaw_W_Actl "CCMGenSigTimeoutTime=1000";
CM_ BO_ 1124 "HS3 APIM Sync Gen3 Tx 0x464.  FrameGateway to 0x467 on HS1, HS2, HS3 and MS1.";
CM_ BO_ 1123 "HS3 APIM Sync Gen3 Tx 0x463.  FrameGateway to 0x466 on HS1, HS2, HS3 and MS1.";
CM_ BO_ 531 "When PBM is present use 0x41B for PrkMsgTxt_D_Rq, PrkBrkRedLamp_D_Rq, PrkBrkYwLamp_D_Rq source signals otherwise ABS will source from 0x213.";
CM_ SG_ 531 VehLongOvrGnd_A_Est "CCMGenSigTimeoutTime=1000";
CM_ SG_ 516 ApedPosPcActl_No_Cs "Signal not transmitted on gas and diesel variants.";
CM_ SG_ 516 ApedPosPcActl_No_Cnt "Signal not transmitted on gas and diesel variants.";
CM_ SG_ 516 ApedPos_Pc_ActlArb "ABSGenSigTimeoutTime=1000";
CM_ SG_ 514 GearRvrse_D_Actl "Do not implement GearRvrse_D_Actl  until eTracker 8804151 is approved, 11/24/09";
CM_ SG_ 376 EngAout_Aa_Actl "Signal not transmitted on HEV variants.";
BA_DEF_ BO_  "VFrameFormat" ENUM  "StandardCAN","ExtendedCAN","reserved","reserved","reserved","reserved","reserved","reserved","reserved","reserved","reserved","reserved","reserved","reserved","StandardCAN_FD","ExtendedCAN_FD";
BA_DEF_ BO_  "FrameRouting" STRING ;
BA_DEF_ BO_  "NetworkInitialization" ENUM  "No","Yes";
BA_DEF_ BO_  "GenMsgStartDelayTime" INT 0 10000;
BA_DEF_ BO_  "GenMsgNrOfRepetition" INT 0 100;
BA_DEF_ BO_  "GenMsgDelayTime" INT 0 1000;
BA_DEF_ BO_  "GenMsgCycleTime" INT 0 100000;
BA_DEF_ BO_  "GenMsgSendType" ENUM  "FixedPeriodic","Event","EnabledPeriodic","NotUsed","NotUsed","EventPeriodic","NotUsed","NotUsed","NoMsgSendType";
BA_DEF_ SG_  "U_P702_MY2024_Tx" ENUM  "No","Yes";
BA_DEF_ SG_  "U_V710_MY2023_Tx" ENUM  "No","Yes";
BA_DEF_ SG_  "U_CDX74X_MY2024_Tx" ENUM  "No","Yes";
BA_DEF_ SG_  "U_P708_MY2023_Tx" ENUM  "No","Yes";
BA_DEF_ SG_  "U_V713AV_MY2022_Tx" ENUM  "No","Yes";
BA_DEF_ SG_  "U_V713N_MY2022_Tx" ENUM  "No","Yes";
BA_DEF_ SG_  "ECGUsedTxSignal" ENUM  "No","Yes";
BA_DEF_ SG_  "U_P702_MY2024_Rx" ENUM  "No","Yes";
BA_DEF_ SG_  "U_V710_MY2023_Rx" ENUM  "No","Yes";
BA_DEF_ SG_  "U_CDX74X_MY2024_Rx" ENUM  "No","Yes";
BA_DEF_ SG_  "U_CDX707_MY2023_Rx" ENUM  "No","Yes";
BA_DEF_ SG_  "U_P708_MY2023_Rx" ENUM  "No","Yes";
BA_DEF_ SG_  "U_V713N_MY2022_Rx" ENUM  "No","Yes";
BA_DEF_ SG_  "ECGUsedRxSignal" ENUM  "No","Yes";
BA_DEF_ SG_  "UsedOnPgmDBC" ENUM  "No","Yes";
BA_DEF_ SG_  "ContentDependant" ENUM  "No","Yes";
BA_DEF_ SG_  "GenSigStartValue" HEX 0 268435455;
BA_DEF_ SG_  "MetaData" ENUM  "No","Yes";
BA_DEF_ SG_  "WakeupSignal" ENUM  "No","Yes";
BA_DEF_ SG_  "GenSigInactiveValue" INT 0 100000;
BA_DEF_ SG_  "GenSigSendType" ENUM  "Cyclic","OnWrite","vector_leerstring","OnChange","vector_leerstring","IfActive","vector_leerstring","NoSigSendType";
BA_DEF_ BO_  "TpTxIndex" INT 0 536870911;
BA_DEF_ BO_  "OvtpPushApplication" ENUM  "FALSE","TRUE";
BA_DEF_ BO_  "SCP_FreshnessValueLength" INT 0 512;
BA_DEF_ BO_  "SCP_DataId" INT 0 17663;
BA_DEF_ BO_  "SCP_FreshnessValueTxLength" INT 0 512;
BA_DEF_ BO_  "SCP_AuthInfoTxLength" INT 0 512;
BA_DEF_ BO_  "SC_Message" ENUM  "No","Yes";
BA_DEF_ BO_  "GenMsgRoutingTimeoutTime" INT 0 5000;
BA_DEF_ BO_  "MessageGateway" ENUM  "No","Yes";
BA_DEF_ BO_  "NmAsrMessage" ENUM  "No","Yes";
BA_DEF_ BO_  "DiagState" ENUM  "No","Yes";
BA_DEF_ BO_  "DiagRequest" ENUM  "No","Yes";
BA_DEF_ BO_  "DiagResponse" ENUM  "No","Yes";
BA_DEF_ BO_  "GenMsgILSupport" ENUM  "No","Yes";
BA_DEF_REL_ BU_SG_REL_  "SC_Verification" ENUM  "No","Yes";
BA_DEF_DEF_  "VFrameFormat" "ExtendedCAN_FD";
BA_DEF_DEF_  "FrameRouting" "";
BA_DEF_DEF_  "NetworkInitialization" "Yes";
BA_DEF_DEF_  "GenMsgStartDelayTime" 0;
BA_DEF_DEF_  "GenMsgNrOfRepetition" 1;
BA_DEF_DEF_  "GenMsgDelayTime" 20;
BA_DEF_DEF_  "GenMsgCycleTime" 0;
BA_DEF_DEF_  "GenMsgSendType" "NoMsgSendType";
BA_DEF_DEF_  "U_P702_MY2024_Tx" "No";
BA_DEF_DEF_  "U_V710_MY2023_Tx" "No";
BA_DEF_DEF_  "U_CDX74X_MY2024_Tx" "No";
BA_DEF_DEF_  "U_P708_MY2023_Tx" "No";
BA_DEF_DEF_  "U_V713AV_MY2022_Tx" "No";
BA_DEF_DEF_  "U_V713N_MY2022_Tx" "No";
BA_DEF_DEF_  "ECGUsedTxSignal" "No";
BA_DEF_DEF_  "U_P702_MY2024_Rx" "No";
BA_DEF_DEF_  "U_V710_MY2023_Rx" "No";
BA_DEF_DEF_  "U_CDX74X_MY2024_Rx" "No";
BA_DEF_DEF_  "U_CDX707_MY2023_Rx" "No";
BA_DEF_DEF_  "U_P708_MY2023_Rx" "No";
BA_DEF_DEF_  "U_V713N_MY2022_Rx" "No";
BA_DEF_DEF_  "ECGUsedRxSignal" "No";
BA_DEF_DEF_  "UsedOnPgmDBC" "Yes";
BA_DEF_DEF_  "ContentDependant" "No";
BA_DEF_DEF_  "GenSigStartValue" 0;
BA_DEF_DEF_  "MetaData" "No";
BA_DEF_DEF_  "WakeupSignal" "No";
BA_DEF_DEF_  "GenSigInactiveValue" 0;
BA_DEF_DEF_  "GenSigSendType" "NoSigSendType";
BA_DEF_DEF_  "TpTxIndex" 0;
BA_DEF_DEF_  "OvtpPushApplication" "FALSE";
BA_DEF_DEF_  "SCP_FreshnessValueLength" 64;
BA_DEF_DEF_  "SCP_DataId" 0;
BA_DEF_DEF_  "SCP_FreshnessValueTxLength" 11;
BA_DEF_DEF_  "SCP_AuthInfoTxLength" 53;
BA_DEF_DEF_  "SC_Message" "No";
BA_DEF_DEF_  "GenMsgRoutingTimeoutTime" 0;
BA_DEF_DEF_  "MessageGateway" "No";
BA_DEF_DEF_  "NmAsrMessage" "No";
BA_DEF_DEF_  "DiagState" "No";
BA_DEF_DEF_  "DiagRequest" "No";
BA_DEF_DEF_  "DiagResponse" "No";
BA_DEF_DEF_  "GenMsgILSupport" "Yes";
BA_DEF_DEF_REL_ "SC_Verification" "No";
BA_ "GenMsgSendType" BO_ 394 5;
BA_ "GenMsgCycleTime" BO_ 394 200;
BA_ "SCP_DataId" BO_ 394 4490;
BA_ "SC_Message" BO_ 394 1;
BA_ "VFrameFormat" BO_ 394 14;
BA_ "GenMsgSendType" BO_ 391 0;
BA_ "GenMsgCycleTime" BO_ 391 20;
BA_ "GenMsgDelayTime" BO_ 391 10;
BA_ "SCP_DataId" BO_ 391 4487;
BA_ "SC_Message" BO_ 391 1;
BA_ "VFrameFormat" BO_ 391 14;
BA_ "GenMsgSendType" BO_ 390 0;
BA_ "GenMsgCycleTime" BO_ 390 20;
BA_ "GenMsgDelayTime" BO_ 390 10;
BA_ "SCP_DataId" BO_ 390 4486;
BA_ "SC_Message" BO_ 390 1;
BA_ "VFrameFormat" BO_ 390 14;
BA_ "GenMsgILSupport" BO_ 1461 0;
BA_ "NmAsrMessage" BO_ 1461 1;
BA_ "GenMsgSendType" BO_ 1461 0;
BA_ "GenMsgCycleTime" BO_ 1461 1000;
BA_ "NetworkInitialization" BO_ 1461 0;
BA_ "VFrameFormat" BO_ 1461 14;
BA_ "GenMsgSendType" BO_ 130 0;
BA_ "GenMsgCycleTime" BO_ 130 20;
BA_ "GenMsgDelayTime" BO_ 130 10;
BA_ "SCP_DataId" BO_ 130 4226;
BA_ "SC_Message" BO_ 130 1;
BA_ "VFrameFormat" BO_ 130 14;
BA_ "FrameRouting" BO_ 1034 "FD1_CAN,0x40A;";
BA_ "SCP_DataId" BO_ 1034 5130;
BA_ "SC_Message" BO_ 1034 1;
BA_ "VFrameFormat" BO_ 1034 14;
BA_ "FrameRouting" BO_ 894 "FD1_CAN,0x37E;";
BA_ "SCP_DataId" BO_ 894 9086;
BA_ "SC_Message" BO_ 894 1;
BA_ "VFrameFormat" BO_ 894 14;
BA_ "FrameRouting" BO_ 611 "FD1_CAN,0x263;";
BA_ "VFrameFormat" BO_ 611 14;
BA_ "FrameRouting" BO_ 534 "FD1_CAN,0x216;";
BA_ "SCP_DataId" BO_ 534 4630;
BA_ "SC_Message" BO_ 534 1;
BA_ "VFrameFormat" BO_ 534 14;
BA_ "FrameRouting" BO_ 533 "HS3_CAN,0x215;";
BA_ "VFrameFormat" BO_ 533 14;
BA_ "FrameRouting" BO_ 92 "FD1_CAN,0x5C;";
BA_ "VFrameFormat" BO_ 92 14;
BA_ "GenMsgILSupport" BO_ 1848 0;
BA_ "DiagResponse" BO_ 1848 1;
BA_ "GenMsgSendType" BO_ 1848 1;
BA_ "GenMsgDelayTime" BO_ 1848 0;
BA_ "NetworkInitialization" BO_ 1848 0;
BA_ "VFrameFormat" BO_ 1848 14;
BA_ "GenMsgILSupport" BO_ 1840 0;
BA_ "DiagRequest" BO_ 1840 1;
BA_ "GenMsgSendType" BO_ 1840 1;
BA_ "GenMsgDelayTime" BO_ 1840 0;
BA_ "NetworkInitialization" BO_ 1840 0;
BA_ "VFrameFormat" BO_ 1840 14;
BA_ "FrameRouting" BO_ 570 "FD1_CAN,0x23A;";
BA_ "VFrameFormat" BO_ 570 14;
BA_ "GenMsgSendType" BO_ 131 5;
BA_ "GenMsgCycleTime" BO_ 131 100;
BA_ "VFrameFormat" BO_ 131 14;
BA_ "FrameRouting" BO_ 125 "FD1_CAN,0x7D;";
BA_ "SCP_DataId" BO_ 125 4221;
BA_ "SC_Message" BO_ 125 1;
BA_ "VFrameFormat" BO_ 125 14;
BA_ "FrameRouting" BO_ 119 "FD1_CAN,0x77;";
BA_ "SCP_DataId" BO_ 119 4215;
BA_ "SC_Message" BO_ 119 1;
BA_ "VFrameFormat" BO_ 119 14;
BA_ "FrameRouting" BO_ 118 "FD1_CAN,0x76;";
BA_ "SCP_DataId" BO_ 118 4214;
BA_ "SC_Message" BO_ 118 1;
BA_ "VFrameFormat" BO_ 118 14;
BA_ "FrameRouting" BO_ 1071 "FD1_CAN,0x42F;";
BA_ "SCP_DataId" BO_ 1071 5167;
BA_ "SC_Message" BO_ 1071 1;
BA_ "VFrameFormat" BO_ 1071 14;
BA_ "GenMsgSendType" BO_ 942 5;
BA_ "GenMsgCycleTime" BO_ 942 200;
BA_ "SCP_DataId" BO_ 942 5038;
BA_ "SC_Message" BO_ 942 1;
BA_ "VFrameFormat" BO_ 942 14;
BA_ "GenMsgSendType" BO_ 939 5;
BA_ "GenMsgCycleTime" BO_ 939 200;
BA_ "SCP_DataId" BO_ 939 5035;
BA_ "SC_Message" BO_ 939 1;
BA_ "VFrameFormat" BO_ 939 14;
BA_ "GenMsgSendType" BO_ 938 5;
BA_ "GenMsgCycleTime" BO_ 938 200;
BA_ "SCP_DataId" BO_ 938 5034;
BA_ "SC_Message" BO_ 938 1;
BA_ "VFrameFormat" BO_ 938 14;
BA_ "GenMsgSendType" BO_ 937 0;
BA_ "GenMsgCycleTime" BO_ 937 20;
BA_ "GenMsgDelayTime" BO_ 937 10;
BA_ "SCP_DataId" BO_ 937 5033;
BA_ "SC_Message" BO_ 937 1;
BA_ "VFrameFormat" BO_ 937 14;
BA_ "GenMsgSendType" BO_ 936 0;
BA_ "GenMsgCycleTime" BO_ 936 20;
BA_ "GenMsgDelayTime" BO_ 936 10;
BA_ "SCP_DataId" BO_ 936 5032;
BA_ "SC_Message" BO_ 936 1;
BA_ "VFrameFormat" BO_ 936 14;
BA_ "SC_Message" BO_ 154 1;
BA_ "SCP_AuthInfoTxLength" BO_ 154 51;
BA_ "SCP_FreshnessValueTxLength" BO_ 154 45;
BA_ "SCP_DataId" BO_ 154 16538;
BA_ "SCP_FreshnessValueLength" BO_ 154 48;
BA_ "GenMsgSendType" BO_ 154 0;
BA_ "GenMsgCycleTime" BO_ 154 50;
BA_ "VFrameFormat" BO_ 154 14;
BA_ "TpTxIndex" BO_ 2614099160 466615512;
BA_ "GenMsgSendType" BO_ 2614099160 1;
BA_ "GenMsgDelayTime" BO_ 2614099160 0;
BA_ "NetworkInitialization" BO_ 2614099160 0;
BA_ "TpTxIndex" BO_ 2613272609 465601752;
BA_ "GenMsgSendType" BO_ 2613272609 1;
BA_ "GenMsgDelayTime" BO_ 2613272609 0;
BA_ "NetworkInitialization" BO_ 2613272609 0;
BA_ "TpTxIndex" BO_ 2613085400 465601752;
BA_ "GenMsgSendType" BO_ 2613085400 1;
BA_ "GenMsgDelayTime" BO_ 2613085400 0;
BA_ "NetworkInitialization" BO_ 2613085400 0;
BA_ "TpTxIndex" BO_ 2613272624 465617112;
BA_ "GenMsgSendType" BO_ 2613272624 1;
BA_ "GenMsgDelayTime" BO_ 2613272624 0;
BA_ "NetworkInitialization" BO_ 2613272624 0;
BA_ "TpTxIndex" BO_ 2613100760 465617112;
BA_ "GenMsgSendType" BO_ 2613100760 1;
BA_ "GenMsgDelayTime" BO_ 2613100760 0;
BA_ "NetworkInitialization" BO_ 2613100760 0;
BA_ "FrameRouting" BO_ 145 "HS2_CAN,0x91;FD1_CAN,0x91";
BA_ "VFrameFormat" BO_ 145 14;
BA_ "OvtpPushApplication" BO_ 2612224099 1;
BA_ "TpTxIndex" BO_ 2612224099 464620760;
BA_ "GenMsgSendType" BO_ 2612224099 1;
BA_ "GenMsgDelayTime" BO_ 2612224099 0;
BA_ "NetworkInitialization" BO_ 2612224099 0;
BA_ "OvtpPushApplication" BO_ 2612224098 1;
BA_ "TpTxIndex" BO_ 2612224098 464619736;
BA_ "GenMsgSendType" BO_ 2612224098 1;
BA_ "GenMsgDelayTime" BO_ 2612224098 0;
BA_ "NetworkInitialization" BO_ 2612224098 0;
BA_ "OvtpPushApplication" BO_ 2612224070 1;
BA_ "TpTxIndex" BO_ 2612224070 464591064;
BA_ "GenMsgSendType" BO_ 2612224070 1;
BA_ "GenMsgDelayTime" BO_ 2612224070 0;
BA_ "NetworkInitialization" BO_ 2612224070 0;
BA_ "FrameRouting" BO_ 535 "FD1_CAN,0x217;";
BA_ "SCP_DataId" BO_ 535 4631;
BA_ "SC_Message" BO_ 535 1;
BA_ "VFrameFormat" BO_ 535 14;
BA_ "OvtpPushApplication" BO_ 2612224069 1;
BA_ "TpTxIndex" BO_ 2612224069 464590040;
BA_ "GenMsgSendType" BO_ 2612224069 1;
BA_ "GenMsgDelayTime" BO_ 2612224069 0;
BA_ "NetworkInitialization" BO_ 2612224069 0;
BA_ "OvtpPushApplication" BO_ 2612224048 1;
BA_ "TpTxIndex" BO_ 2612224048 464568536;
BA_ "GenMsgSendType" BO_ 2612224048 1;
BA_ "GenMsgDelayTime" BO_ 2612224048 0;
BA_ "NetworkInitialization" BO_ 2612224048 0;
BA_ "OvtpPushApplication" BO_ 2612224033 1;
BA_ "TpTxIndex" BO_ 2612224033 464553176;
BA_ "GenMsgSendType" BO_ 2612224033 1;
BA_ "GenMsgDelayTime" BO_ 2612224033 0;
BA_ "NetworkInitialization" BO_ 2612224033 0;
BA_ "OvtpPushApplication" BO_ 2612224113 1;
BA_ "TpTxIndex" BO_ 2612224113 464635096;
BA_ "GenMsgSendType" BO_ 2612224113 1;
BA_ "GenMsgDelayTime" BO_ 2612224113 0;
BA_ "NetworkInitialization" BO_ 2612224113 0;
BA_ "OvtpPushApplication" BO_ 2612104408 1;
BA_ "TpTxIndex" BO_ 2612104408 464620760;
BA_ "GenMsgSendType" BO_ 2612104408 1;
BA_ "GenMsgDelayTime" BO_ 2612104408 0;
BA_ "NetworkInitialization" BO_ 2612104408 0;
BA_ "OvtpPushApplication" BO_ 2612103384 1;
BA_ "TpTxIndex" BO_ 2612103384 464619736;
BA_ "GenMsgSendType" BO_ 2612103384 1;
BA_ "GenMsgDelayTime" BO_ 2612103384 0;
BA_ "NetworkInitialization" BO_ 2612103384 0;
BA_ "OvtpPushApplication" BO_ 2612074712 1;
BA_ "TpTxIndex" BO_ 2612074712 464591064;
BA_ "GenMsgSendType" BO_ 2612074712 1;
BA_ "GenMsgDelayTime" BO_ 2612074712 0;
BA_ "NetworkInitialization" BO_ 2612074712 0;
BA_ "OvtpPushApplication" BO_ 2612118744 1;
BA_ "TpTxIndex" BO_ 2612118744 464635096;
BA_ "GenMsgSendType" BO_ 2612118744 1;
BA_ "GenMsgDelayTime" BO_ 2612118744 0;
BA_ "NetworkInitialization" BO_ 2612118744 0;
BA_ "TpTxIndex" BO_ 2610982104 463498456;
BA_ "GenMsgSendType" BO_ 2610982104 1;
BA_ "GenMsgDelayTime" BO_ 2610982104 0;
BA_ "NetworkInitialization" BO_ 2610982104 0;
BA_ "OvtpPushApplication" BO_ 2612052184 1;
BA_ "TpTxIndex" BO_ 2612052184 464568536;
BA_ "GenMsgSendType" BO_ 2612052184 1;
BA_ "GenMsgDelayTime" BO_ 2612052184 0;
BA_ "NetworkInitialization" BO_ 2612052184 0;
BA_ "OvtpPushApplication" BO_ 2612036824 1;
BA_ "TpTxIndex" BO_ 2612036824 464553176;
BA_ "GenMsgSendType" BO_ 2612036824 1;
BA_ "GenMsgDelayTime" BO_ 2612036824 0;
BA_ "NetworkInitialization" BO_ 2612036824 0;
BA_ "FrameRouting" BO_ 1124 "HS3_CAN,0x464;";
BA_ "VFrameFormat" BO_ 1124 14;
BA_ "FrameRouting" BO_ 1123 "HS3_CAN,0x463;";
BA_ "VFrameFormat" BO_ 1123 14;
BA_ "OvtpPushApplication" BO_ 2612030680 1;
BA_ "TpTxIndex" BO_ 2612030680 464547032;
BA_ "GenMsgSendType" BO_ 2612030680 1;
BA_ "GenMsgDelayTime" BO_ 2612030680 0;
BA_ "NetworkInitialization" BO_ 2612030680 0;
BA_ "FrameRouting" BO_ 531 "FD1_CAN,0x213;";
BA_ "SCP_DataId" BO_ 531 4627;
BA_ "SC_Message" BO_ 531 1;
BA_ "VFrameFormat" BO_ 531 14;
BA_ "FrameRouting" BO_ 517 "FD1_CAN,0x205;";
BA_ "SCP_DataId" BO_ 517 4613;
BA_ "SC_Message" BO_ 517 1;
BA_ "VFrameFormat" BO_ 517 14;
BA_ "FrameRouting" BO_ 516 "FD1_CAN,0x204;";
BA_ "SCP_DataId" BO_ 516 4612;
BA_ "SC_Message" BO_ 516 1;
BA_ "VFrameFormat" BO_ 516 14;
BA_ "FrameRouting" BO_ 514 "FD1_CAN,0x202;";
BA_ "SCP_DataId" BO_ 514 4610;
BA_ "SC_Message" BO_ 514 1;
BA_ "VFrameFormat" BO_ 514 14;
BA_ "FrameRouting" BO_ 512 "FD1_CAN,0x200;";
BA_ "SCP_DataId" BO_ 512 4608;
BA_ "SC_Message" BO_ 512 1;
BA_ "VFrameFormat" BO_ 512 14;
BA_ "FrameRouting" BO_ 376 "FD1_CAN,0x178;";
BA_ "SCP_DataId" BO_ 376 4472;
BA_ "SC_Message" BO_ 376 1;
BA_ "VFrameFormat" BO_ 376 14;
BA_ "GenMsgSendType" BO_ 1229 5;
BA_ "GenMsgCycleTime" BO_ 1229 1000;
BA_ "VFrameFormat" BO_ 1229 14;
BA_ "GenSigSendType" SG_ 394 AccTrgDist2_D_Dsply 3;
BA_ "U_P708_MY2023_Tx" SG_ 394 AccTrgDist2_D_Dsply 1;
BA_ "U_V710_MY2023_Tx" SG_ 394 AccTrgDist2_D_Dsply 1;
BA_ "U_P702_MY2024_Tx" SG_ 394 AccTrgDist2_D_Dsply 1;
BA_ "GenSigSendType" SG_ 394 AccStopRes_B_Dsply 3;
BA_ "U_P708_MY2023_Tx" SG_ 394 AccStopRes_B_Dsply 1;
BA_ "U_V710_MY2023_Tx" SG_ 394 AccStopRes_B_Dsply 1;
BA_ "U_P702_MY2024_Tx" SG_ 394 AccStopRes_B_Dsply 1;
BA_ "GenSigSendType" SG_ 394 TjaWarn_D_Rq 3;
BA_ "U_P708_MY2023_Tx" SG_ 394 TjaWarn_D_Rq 1;
BA_ "U_V710_MY2023_Tx" SG_ 394 TjaWarn_D_Rq 1;
BA_ "U_P702_MY2024_Tx" SG_ 394 TjaWarn_D_Rq 1;
BA_ "GenSigSendType" SG_ 394 Tja_D_Stat 3;
BA_ "U_P708_MY2023_Tx" SG_ 394 Tja_D_Stat 1;
BA_ "U_V710_MY2023_Tx" SG_ 394 Tja_D_Stat 1;
BA_ "U_P702_MY2024_Tx" SG_ 394 Tja_D_Stat 1;
BA_ "GenSigSendType" SG_ 394 TjaMsgTxt_D_Dsply 3;
BA_ "U_P708_MY2023_Tx" SG_ 394 TjaMsgTxt_D_Dsply 1;
BA_ "U_V710_MY2023_Tx" SG_ 394 TjaMsgTxt_D_Dsply 1;
BA_ "U_P702_MY2024_Tx" SG_ 394 TjaMsgTxt_D_Dsply 1;
BA_ "GenSigSendType" SG_ 394 IaccLamp_D_Rq 3;
BA_ "U_P708_MY2023_Tx" SG_ 394 IaccLamp_D_Rq 1;
BA_ "U_V710_MY2023_Tx" SG_ 394 IaccLamp_D_Rq 1;
BA_ "U_P702_MY2024_Tx" SG_ 394 IaccLamp_D_Rq 1;
BA_ "GenSigSendType" SG_ 394 AccMsgTxt_D2_Rq 3;
BA_ "U_P708_MY2023_Tx" SG_ 394 AccMsgTxt_D2_Rq 1;
BA_ "U_V710_MY2023_Tx" SG_ 394 AccMsgTxt_D2_Rq 1;
BA_ "U_P702_MY2024_Tx" SG_ 394 AccMsgTxt_D2_Rq 1;
BA_ "GenSigSendType" SG_ 394 FcwDeny_B_Dsply 3;
BA_ "U_P708_MY2023_Tx" SG_ 394 FcwDeny_B_Dsply 1;
BA_ "U_V710_MY2023_Tx" SG_ 394 FcwDeny_B_Dsply 1;
BA_ "U_P702_MY2024_Tx" SG_ 394 FcwDeny_B_Dsply 1;
BA_ "GenSigSendType" SG_ 394 FcwMemStat_B_Actl 3;
BA_ "ECGUsedRxSignal" SG_ 394 FcwMemStat_B_Actl 1;
BA_ "U_P708_MY2023_Rx" SG_ 394 FcwMemStat_B_Actl 1;
BA_ "U_CDX74X_MY2024_Rx" SG_ 394 FcwMemStat_B_Actl 1;
BA_ "U_P702_MY2024_Rx" SG_ 394 FcwMemStat_B_Actl 1;
BA_ "U_P708_MY2023_Tx" SG_ 394 FcwMemStat_B_Actl 1;
BA_ "U_V710_MY2023_Tx" SG_ 394 FcwMemStat_B_Actl 1;
BA_ "U_P702_MY2024_Tx" SG_ 394 FcwMemStat_B_Actl 1;
BA_ "GenSigSendType" SG_ 394 AccTGap_B_Dsply 3;
BA_ "U_P708_MY2023_Tx" SG_ 394 AccTGap_B_Dsply 1;
BA_ "U_V710_MY2023_Tx" SG_ 394 AccTGap_B_Dsply 1;
BA_ "U_P702_MY2024_Tx" SG_ 394 AccTGap_B_Dsply 1;
BA_ "GenSigSendType" SG_ 394 CadsAlignIncplt_B_Actl 3;
BA_ "U_P708_MY2023_Tx" SG_ 394 CadsAlignIncplt_B_Actl 1;
BA_ "U_V710_MY2023_Tx" SG_ 394 CadsAlignIncplt_B_Actl 1;
BA_ "U_P702_MY2024_Tx" SG_ 394 CadsAlignIncplt_B_Actl 1;
BA_ "GenSigSendType" SG_ 394 AccFllwMde_B_Dsply 3;
BA_ "U_P708_MY2023_Tx" SG_ 394 AccFllwMde_B_Dsply 1;
BA_ "U_V710_MY2023_Tx" SG_ 394 AccFllwMde_B_Dsply 1;
BA_ "U_P702_MY2024_Tx" SG_ 394 AccFllwMde_B_Dsply 1;
BA_ "GenSigSendType" SG_ 394 CadsRadrBlck_B_Actl 3;
BA_ "U_P708_MY2023_Tx" SG_ 394 CadsRadrBlck_B_Actl 1;
BA_ "U_V710_MY2023_Tx" SG_ 394 CadsRadrBlck_B_Actl 1;
BA_ "U_P702_MY2024_Tx" SG_ 394 CadsRadrBlck_B_Actl 1;
BA_ "GenSigSendType" SG_ 394 CmbbPostEvnt_B_Dsply 3;
BA_ "U_P708_MY2023_Tx" SG_ 394 CmbbPostEvnt_B_Dsply 1;
BA_ "U_V710_MY2023_Tx" SG_ 394 CmbbPostEvnt_B_Dsply 1;
BA_ "U_P702_MY2024_Tx" SG_ 394 CmbbPostEvnt_B_Dsply 1;
BA_ "GenSigSendType" SG_ 394 AccStopMde_B_Dsply 3;
BA_ "U_P708_MY2023_Tx" SG_ 394 AccStopMde_B_Dsply 1;
BA_ "U_V710_MY2023_Tx" SG_ 394 AccStopMde_B_Dsply 1;
BA_ "U_P702_MY2024_Tx" SG_ 394 AccStopMde_B_Dsply 1;
BA_ "GenSigSendType" SG_ 394 FcwMemSens_D_Actl 3;
BA_ "ECGUsedRxSignal" SG_ 394 FcwMemSens_D_Actl 1;
BA_ "U_P708_MY2023_Rx" SG_ 394 FcwMemSens_D_Actl 1;
BA_ "U_CDX74X_MY2024_Rx" SG_ 394 FcwMemSens_D_Actl 1;
BA_ "U_P702_MY2024_Rx" SG_ 394 FcwMemSens_D_Actl 1;
BA_ "U_P708_MY2023_Tx" SG_ 394 FcwMemSens_D_Actl 1;
BA_ "U_V710_MY2023_Tx" SG_ 394 FcwMemSens_D_Actl 1;
BA_ "U_P702_MY2024_Tx" SG_ 394 FcwMemSens_D_Actl 1;
BA_ "GenSigSendType" SG_ 394 FcwMsgTxt_D_Rq 3;
BA_ "U_P708_MY2023_Tx" SG_ 394 FcwMsgTxt_D_Rq 1;
BA_ "U_V710_MY2023_Tx" SG_ 394 FcwMsgTxt_D_Rq 1;
BA_ "U_P702_MY2024_Tx" SG_ 394 FcwMsgTxt_D_Rq 1;
BA_ "GenSigSendType" SG_ 394 AccWarn_D_Dsply 3;
BA_ "U_P708_MY2023_Tx" SG_ 394 AccWarn_D_Dsply 1;
BA_ "U_V710_MY2023_Tx" SG_ 394 AccWarn_D_Dsply 1;
BA_ "U_P702_MY2024_Tx" SG_ 394 AccWarn_D_Dsply 1;
BA_ "GenSigSendType" SG_ 394 FcwVisblWarn_B_Rq 3;
BA_ "U_P708_MY2023_Tx" SG_ 394 FcwVisblWarn_B_Rq 1;
BA_ "U_V710_MY2023_Tx" SG_ 394 FcwVisblWarn_B_Rq 1;
BA_ "U_P702_MY2024_Tx" SG_ 394 FcwVisblWarn_B_Rq 1;
BA_ "GenSigSendType" SG_ 394 FcwAudioWarn_B_Rq 3;
BA_ "ECGUsedRxSignal" SG_ 394 FcwAudioWarn_B_Rq 1;
BA_ "U_P708_MY2023_Rx" SG_ 394 FcwAudioWarn_B_Rq 1;
BA_ "U_CDX74X_MY2024_Rx" SG_ 394 FcwAudioWarn_B_Rq 1;
BA_ "U_P702_MY2024_Rx" SG_ 394 FcwAudioWarn_B_Rq 1;
BA_ "U_P708_MY2023_Tx" SG_ 394 FcwAudioWarn_B_Rq 1;
BA_ "U_V710_MY2023_Tx" SG_ 394 FcwAudioWarn_B_Rq 1;
BA_ "U_P702_MY2024_Tx" SG_ 394 FcwAudioWarn_B_Rq 1;
BA_ "GenSigStartValue" SG_ 394 AccTGap_D_Dsply 3;
BA_ "GenSigSendType" SG_ 394 AccTGap_D_Dsply 3;
BA_ "U_P708_MY2023_Tx" SG_ 394 AccTGap_D_Dsply 1;
BA_ "U_V710_MY2023_Tx" SG_ 394 AccTGap_D_Dsply 1;
BA_ "U_P702_MY2024_Tx" SG_ 394 AccTGap_D_Dsply 1;
BA_ "GenSigStartValue" SG_ 394 AccMemEnbl_B_RqDrv 1;
BA_ "GenSigSendType" SG_ 394 AccMemEnbl_B_RqDrv 3;
BA_ "U_P708_MY2023_Tx" SG_ 394 AccMemEnbl_B_RqDrv 1;
BA_ "U_V710_MY2023_Tx" SG_ 394 AccMemEnbl_B_RqDrv 1;
BA_ "U_P702_MY2024_Tx" SG_ 394 AccMemEnbl_B_RqDrv 1;
BA_ "GenSigSendType" SG_ 394 AccStopStat_D_Dsply 3;
BA_ "U_P708_MY2023_Tx" SG_ 394 AccStopStat_D_Dsply 1;
BA_ "U_V710_MY2023_Tx" SG_ 394 AccStopStat_D_Dsply 1;
BA_ "U_P702_MY2024_Tx" SG_ 394 AccStopStat_D_Dsply 1;
BA_ "MetaData" SG_ 394 HaDsply_No_Cs 1;
BA_ "GenSigSendType" SG_ 394 HaDsply_No_Cs 3;
BA_ "U_P708_MY2023_Tx" SG_ 394 HaDsply_No_Cs 1;
BA_ "U_V710_MY2023_Tx" SG_ 394 HaDsply_No_Cs 1;
BA_ "U_P702_MY2024_Tx" SG_ 394 HaDsply_No_Cs 1;
BA_ "MetaData" SG_ 394 HaDsply_No_Cnt 1;
BA_ "GenSigSendType" SG_ 394 HaDsply_No_Cnt 3;
BA_ "U_P708_MY2023_Tx" SG_ 394 HaDsply_No_Cnt 1;
BA_ "U_V710_MY2023_Tx" SG_ 394 HaDsply_No_Cnt 1;
BA_ "U_P702_MY2024_Tx" SG_ 394 HaDsply_No_Cnt 1;
BA_ "MetaData" SG_ 391 CmbbBrkDecel_No_Cnt 1;
BA_ "U_P708_MY2023_Tx" SG_ 391 CmbbBrkDecel_No_Cnt 1;
BA_ "U_V710_MY2023_Tx" SG_ 391 CmbbBrkDecel_No_Cnt 1;
BA_ "U_P702_MY2024_Tx" SG_ 391 CmbbBrkDecel_No_Cnt 1;
BA_ "U_P708_MY2023_Tx" SG_ 391 HudDsplyIntns_No_Actl 1;
BA_ "U_V710_MY2023_Tx" SG_ 391 HudDsplyIntns_No_Actl 1;
BA_ "U_P702_MY2024_Tx" SG_ 391 HudDsplyIntns_No_Actl 1;
BA_ "U_P708_MY2023_Tx" SG_ 391 HudBlk3_B_Rq 1;
BA_ "U_V710_MY2023_Tx" SG_ 391 HudBlk3_B_Rq 1;
BA_ "U_P702_MY2024_Tx" SG_ 391 HudBlk3_B_Rq 1;
BA_ "U_P708_MY2023_Tx" SG_ 391 HudBlk2_B_Rq 1;
BA_ "U_V710_MY2023_Tx" SG_ 391 HudBlk2_B_Rq 1;
BA_ "U_P702_MY2024_Tx" SG_ 391 HudBlk2_B_Rq 1;
BA_ "U_P708_MY2023_Tx" SG_ 391 HudBlk1_B_Rq 1;
BA_ "U_V710_MY2023_Tx" SG_ 391 HudBlk1_B_Rq 1;
BA_ "U_P702_MY2024_Tx" SG_ 391 HudBlk1_B_Rq 1;
BA_ "U_P708_MY2023_Tx" SG_ 391 HudFlashRate_D_Actl 1;
BA_ "U_V710_MY2023_Tx" SG_ 391 HudFlashRate_D_Actl 1;
BA_ "U_P702_MY2024_Tx" SG_ 391 HudFlashRate_D_Actl 1;
BA_ "MetaData" SG_ 391 CmbbBrkDecel_No_Cs 1;
BA_ "U_P708_MY2023_Tx" SG_ 391 CmbbBrkDecel_No_Cs 1;
BA_ "U_V710_MY2023_Tx" SG_ 391 CmbbBrkDecel_No_Cs 1;
BA_ "U_P702_MY2024_Tx" SG_ 391 CmbbBrkDecel_No_Cs 1;
BA_ "U_P708_MY2023_Tx" SG_ 391 CmbbBrkDecel_A_Rq 1;
BA_ "U_V710_MY2023_Tx" SG_ 391 CmbbBrkDecel_A_Rq 1;
BA_ "U_P702_MY2024_Tx" SG_ 391 CmbbBrkDecel_A_Rq 1;
BA_ "ECGUsedRxSignal" SG_ 391 CmbbBrkPrchg_D_Rq 1;
BA_ "U_P708_MY2023_Rx" SG_ 391 CmbbBrkPrchg_D_Rq 1;
BA_ "U_CDX74X_MY2024_Rx" SG_ 391 CmbbBrkPrchg_D_Rq 1;
BA_ "U_P702_MY2024_Rx" SG_ 391 CmbbBrkPrchg_D_Rq 1;
BA_ "U_P708_MY2023_Tx" SG_ 391 CmbbBrkPrchg_D_Rq 1;
BA_ "U_V710_MY2023_Tx" SG_ 391 CmbbBrkPrchg_D_Rq 1;
BA_ "U_P702_MY2024_Tx" SG_ 391 CmbbBrkPrchg_D_Rq 1;
BA_ "U_P708_MY2023_Tx" SG_ 391 CmbbBrkDecel_B_Rq 1;
BA_ "U_V710_MY2023_Tx" SG_ 391 CmbbBrkDecel_B_Rq 1;
BA_ "U_P702_MY2024_Tx" SG_ 391 CmbbBrkDecel_B_Rq 1;
BA_ "U_P708_MY2023_Tx" SG_ 391 CmbbBaSens_D_Rq 1;
BA_ "U_V710_MY2023_Tx" SG_ 391 CmbbBaSens_D_Rq 1;
BA_ "U_P702_MY2024_Tx" SG_ 391 CmbbBaSens_D_Rq 1;
BA_ "U_P708_MY2023_Tx" SG_ 390 AccBrkTot_A_Rq 1;
BA_ "U_V710_MY2023_Tx" SG_ 390 AccBrkTot_A_Rq 1;
BA_ "U_P702_MY2024_Tx" SG_ 390 AccBrkTot_A_Rq 1;
BA_ "U_P708_MY2023_Tx" SG_ 390 AccPrpl_A_Pred 1;
BA_ "U_V710_MY2023_Tx" SG_ 390 AccPrpl_A_Pred 1;
BA_ "U_P702_MY2024_Tx" SG_ 390 AccPrpl_A_Pred 1;
BA_ "U_P708_MY2023_Tx" SG_ 390 AccVeh_V_Trg 1;
BA_ "U_V710_MY2023_Tx" SG_ 390 AccVeh_V_Trg 1;
BA_ "U_P702_MY2024_Tx" SG_ 390 AccVeh_V_Trg 1;
BA_ "U_P708_MY2023_Tx" SG_ 390 AccBrkPrkEl_B_Rq 1;
BA_ "U_V710_MY2023_Tx" SG_ 390 AccBrkPrkEl_B_Rq 1;
BA_ "U_P702_MY2024_Tx" SG_ 390 AccBrkPrkEl_B_Rq 1;
BA_ "U_P708_MY2023_Tx" SG_ 390 Cmbb_B_Enbl 1;
BA_ "U_V710_MY2023_Tx" SG_ 390 Cmbb_B_Enbl 1;
BA_ "U_P702_MY2024_Tx" SG_ 390 Cmbb_B_Enbl 1;
BA_ "U_P708_MY2023_Tx" SG_ 390 CmbbOvrrd_B_RqDrv 1;
BA_ "U_V710_MY2023_Tx" SG_ 390 CmbbOvrrd_B_RqDrv 1;
BA_ "U_P702_MY2024_Tx" SG_ 390 CmbbOvrrd_B_RqDrv 1;
BA_ "U_P708_MY2023_Tx" SG_ 390 CmbbDeny_B_Actl 1;
BA_ "U_V710_MY2023_Tx" SG_ 390 CmbbDeny_B_Actl 1;
BA_ "U_P702_MY2024_Tx" SG_ 390 CmbbDeny_B_Actl 1;
BA_ "U_P708_MY2023_Tx" SG_ 390 CmbbEngTqMn_B_Rq 1;
BA_ "U_V710_MY2023_Tx" SG_ 390 CmbbEngTqMn_B_Rq 1;
BA_ "U_P702_MY2024_Tx" SG_ 390 CmbbEngTqMn_B_Rq 1;
BA_ "U_P708_MY2023_Tx" SG_ 390 AccPrpl_A_Rq 1;
BA_ "U_V710_MY2023_Tx" SG_ 390 AccPrpl_A_Rq 1;
BA_ "U_P702_MY2024_Tx" SG_ 390 AccPrpl_A_Rq 1;
BA_ "U_P708_MY2023_Tx" SG_ 390 AccDeny_B_Rq 1;
BA_ "U_V710_MY2023_Tx" SG_ 390 AccDeny_B_Rq 1;
BA_ "U_P702_MY2024_Tx" SG_ 390 AccDeny_B_Rq 1;
BA_ "WakeupSignal" SG_ 390 AccResumEnbl_B_Rq 1;
BA_ "U_P708_MY2023_Tx" SG_ 390 AccResumEnbl_B_Rq 1;
BA_ "U_V710_MY2023_Tx" SG_ 390 AccResumEnbl_B_Rq 1;
BA_ "U_P702_MY2024_Tx" SG_ 390 AccResumEnbl_B_Rq 1;
BA_ "U_P708_MY2023_Tx" SG_ 390 AccCancl_B_Rq 1;
BA_ "U_V710_MY2023_Tx" SG_ 390 AccCancl_B_Rq 1;
BA_ "U_P702_MY2024_Tx" SG_ 390 AccCancl_B_Rq 1;
BA_ "U_P708_MY2023_Tx" SG_ 390 AccBrkPrchg_B_Rq 1;
BA_ "U_V710_MY2023_Tx" SG_ 390 AccBrkPrchg_B_Rq 1;
BA_ "U_P702_MY2024_Tx" SG_ 390 AccBrkPrchg_B_Rq 1;
BA_ "U_P708_MY2023_Tx" SG_ 390 AccBrkDecel_B_Rq 1;
BA_ "U_V710_MY2023_Tx" SG_ 390 AccBrkDecel_B_Rq 1;
BA_ "U_P702_MY2024_Tx" SG_ 390 AccBrkDecel_B_Rq 1;
BA_ "U_P708_MY2023_Tx" SG_ 390 AccStopStat_B_Rq 1;
BA_ "U_V710_MY2023_Tx" SG_ 390 AccStopStat_B_Rq 1;
BA_ "U_P702_MY2024_Tx" SG_ 390 AccStopStat_B_Rq 1;
BA_ "U_P708_MY2023_Tx" SG_ 390 AccAutoResum_D_Rq 1;
BA_ "U_V710_MY2023_Tx" SG_ 390 AccAutoResum_D_Rq 1;
BA_ "U_P702_MY2024_Tx" SG_ 390 AccAutoResum_D_Rq 1;
BA_ "U_P708_MY2023_Tx" SG_ 390 AccBrkPulse_B_Rq 1;
BA_ "U_V710_MY2023_Tx" SG_ 390 AccBrkPulse_B_Rq 1;
BA_ "U_P702_MY2024_Tx" SG_ 390 AccBrkPulse_B_Rq 1;
BA_ "GenSigStartValue" SG_ 1461 PSCM_GWOnBoardTester 255;
BA_ "U_V713N_MY2022_Tx" SG_ 1461 PSCM_GWOnBoardTester 1;
BA_ "U_P708_MY2023_Tx" SG_ 1461 PSCM_GWOnBoardTester 1;
BA_ "U_CDX74X_MY2024_Tx" SG_ 1461 PSCM_GWOnBoardTester 1;
BA_ "U_V710_MY2023_Tx" SG_ 1461 PSCM_GWOnBoardTester 1;
BA_ "U_P702_MY2024_Tx" SG_ 1461 PSCM_GWOnBoardTester 1;
BA_ "GenSigStartValue" SG_ 1461 PSCM_GWNMProxy 255;
BA_ "U_V713N_MY2022_Tx" SG_ 1461 PSCM_GWNMProxy 1;
BA_ "U_P708_MY2023_Tx" SG_ 1461 PSCM_GWNMProxy 1;
BA_ "U_CDX74X_MY2024_Tx" SG_ 1461 PSCM_GWNMProxy 1;
BA_ "U_V710_MY2023_Tx" SG_ 1461 PSCM_GWNMProxy 1;
BA_ "U_P702_MY2024_Tx" SG_ 1461 PSCM_GWNMProxy 1;
BA_ "GenSigStartValue" SG_ 1461 PSCM_AutoSarNMReserved4 255;
BA_ "U_V713N_MY2022_Tx" SG_ 1461 PSCM_AutoSarNMReserved4 1;
BA_ "U_P708_MY2023_Tx" SG_ 1461 PSCM_AutoSarNMReserved4 1;
BA_ "U_CDX74X_MY2024_Tx" SG_ 1461 PSCM_AutoSarNMReserved4 1;
BA_ "U_V710_MY2023_Tx" SG_ 1461 PSCM_AutoSarNMReserved4 1;
BA_ "U_P702_MY2024_Tx" SG_ 1461 PSCM_AutoSarNMReserved4 1;
BA_ "GenSigStartValue" SG_ 1461 PSCM_AutoSarNMReserved3 255;
BA_ "U_V713N_MY2022_Tx" SG_ 1461 PSCM_AutoSarNMReserved3 1;
BA_ "U_P708_MY2023_Tx" SG_ 1461 PSCM_AutoSarNMReserved3 1;
BA_ "U_CDX74X_MY2024_Tx" SG_ 1461 PSCM_AutoSarNMReserved3 1;
BA_ "U_V710_MY2023_Tx" SG_ 1461 PSCM_AutoSarNMReserved3 1;
BA_ "U_P702_MY2024_Tx" SG_ 1461 PSCM_AutoSarNMReserved3 1;
BA_ "GenSigStartValue" SG_ 1461 PSCM_AutoSarNMReserved2 255;
BA_ "U_V713N_MY2022_Tx" SG_ 1461 PSCM_AutoSarNMReserved2 1;
BA_ "U_P708_MY2023_Tx" SG_ 1461 PSCM_AutoSarNMReserved2 1;
BA_ "U_CDX74X_MY2024_Tx" SG_ 1461 PSCM_AutoSarNMReserved2 1;
BA_ "U_V710_MY2023_Tx" SG_ 1461 PSCM_AutoSarNMReserved2 1;
BA_ "U_P702_MY2024_Tx" SG_ 1461 PSCM_AutoSarNMReserved2 1;
BA_ "GenSigStartValue" SG_ 1461 PSCM_AutoSarNMReserved1 255;
BA_ "U_V713N_MY2022_Tx" SG_ 1461 PSCM_AutoSarNMReserved1 1;
BA_ "U_P708_MY2023_Tx" SG_ 1461 PSCM_AutoSarNMReserved1 1;
BA_ "U_CDX74X_MY2024_Tx" SG_ 1461 PSCM_AutoSarNMReserved1 1;
BA_ "U_V710_MY2023_Tx" SG_ 1461 PSCM_AutoSarNMReserved1 1;
BA_ "U_P702_MY2024_Tx" SG_ 1461 PSCM_AutoSarNMReserved1 1;
BA_ "GenSigStartValue" SG_ 1461 PSCM_AutoSarNMNodeId 181;
BA_ "U_V713N_MY2022_Tx" SG_ 1461 PSCM_AutoSarNMNodeId 1;
BA_ "U_P708_MY2023_Tx" SG_ 1461 PSCM_AutoSarNMNodeId 1;
BA_ "U_CDX74X_MY2024_Tx" SG_ 1461 PSCM_AutoSarNMNodeId 1;
BA_ "U_V710_MY2023_Tx" SG_ 1461 PSCM_AutoSarNMNodeId 1;
BA_ "U_P702_MY2024_Tx" SG_ 1461 PSCM_AutoSarNMNodeId 1;
BA_ "U_V713N_MY2022_Tx" SG_ 1461 PSCM_AutoSarNMControl 1;
BA_ "U_P708_MY2023_Tx" SG_ 1461 PSCM_AutoSarNMControl 1;
BA_ "U_CDX74X_MY2024_Tx" SG_ 1461 PSCM_AutoSarNMControl 1;
BA_ "U_V710_MY2023_Tx" SG_ 1461 PSCM_AutoSarNMControl 1;
BA_ "U_P702_MY2024_Tx" SG_ 1461 PSCM_AutoSarNMControl 1;
BA_ "U_P708_MY2023_Rx" SG_ 130 TrlrHitchLamp_D_Rqst 1;
BA_ "U_V710_MY2023_Rx" SG_ 130 TrlrHitchLamp_D_Rqst 1;
BA_ "U_P702_MY2024_Rx" SG_ 130 TrlrHitchLamp_D_Rqst 1;
BA_ "U_V713N_MY2022_Tx" SG_ 130 TrlrHitchLamp_D_Rqst 1;
BA_ "U_P708_MY2023_Tx" SG_ 130 TrlrHitchLamp_D_Rqst 1;
BA_ "U_P702_MY2024_Tx" SG_ 130 TrlrHitchLamp_D_Rqst 1;
BA_ "U_V713N_MY2022_Tx" SG_ 130 VehVTrlrAid_B_Rq 1;
BA_ "U_P708_MY2023_Tx" SG_ 130 VehVTrlrAid_B_Rq 1;
BA_ "U_P702_MY2024_Tx" SG_ 130 VehVTrlrAid_B_Rq 1;
BA_ "U_V713N_MY2022_Tx" SG_ 130 SteEffort_D_Stat 1;
BA_ "U_P708_MY2023_Tx" SG_ 130 SteEffort_D_Stat 1;
BA_ "GenSigStartValue" SG_ 130 Veh_V_RqMxTrlrAid 255;
BA_ "U_V713N_MY2022_Tx" SG_ 130 Veh_V_RqMxTrlrAid 1;
BA_ "U_P708_MY2023_Tx" SG_ 130 Veh_V_RqMxTrlrAid 1;
BA_ "U_P702_MY2024_Tx" SG_ 130 Veh_V_RqMxTrlrAid 1;
BA_ "U_V713N_MY2022_Tx" SG_ 130 SteMdule_D_Stat 1;
BA_ "U_P708_MY2023_Tx" SG_ 130 SteMdule_D_Stat 1;
BA_ "U_CDX74X_MY2024_Tx" SG_ 130 SteMdule_D_Stat 1;
BA_ "U_V710_MY2023_Tx" SG_ 130 SteMdule_D_Stat 1;
BA_ "U_P702_MY2024_Tx" SG_ 130 SteMdule_D_Stat 1;
BA_ "GenSigStartValue" SG_ 130 SteMdule_U_Meas 255;
BA_ "U_V713N_MY2022_Tx" SG_ 130 SteMdule_U_Meas 1;
BA_ "U_P708_MY2023_Tx" SG_ 130 SteMdule_U_Meas 1;
BA_ "U_CDX74X_MY2024_Tx" SG_ 130 SteMdule_U_Meas 1;
BA_ "U_V710_MY2023_Tx" SG_ 130 SteMdule_U_Meas 1;
BA_ "U_P702_MY2024_Tx" SG_ 130 SteMdule_U_Meas 1;
BA_ "GenSigStartValue" SG_ 130 SteMdule_I_Est 4095;
BA_ "U_V713N_MY2022_Tx" SG_ 130 SteMdule_I_Est 1;
BA_ "U_P708_MY2023_Tx" SG_ 130 SteMdule_I_Est 1;
BA_ "U_CDX74X_MY2024_Tx" SG_ 130 SteMdule_I_Est 1;
BA_ "U_V710_MY2023_Tx" SG_ 130 SteMdule_I_Est 1;
BA_ "U_P702_MY2024_Tx" SG_ 130 SteMdule_I_Est 1;
BA_ "U_P708_MY2023_Rx" SG_ 130 EPAS_Failure 1;
BA_ "U_V710_MY2023_Rx" SG_ 130 EPAS_Failure 1;
BA_ "U_P702_MY2024_Rx" SG_ 130 EPAS_Failure 1;
BA_ "U_V713N_MY2022_Tx" SG_ 130 EPAS_Failure 1;
BA_ "U_P708_MY2023_Tx" SG_ 130 EPAS_Failure 1;
BA_ "U_CDX74X_MY2024_Tx" SG_ 130 EPAS_Failure 1;
BA_ "U_V710_MY2023_Tx" SG_ 130 EPAS_Failure 1;
BA_ "U_P702_MY2024_Tx" SG_ 130 EPAS_Failure 1;
BA_ "GenSigStartValue" SG_ 130 SteeringColumnTorque 254;
BA_ "U_P708_MY2023_Rx" SG_ 130 SteeringColumnTorque 1;
BA_ "U_V710_MY2023_Rx" SG_ 130 SteeringColumnTorque 1;
BA_ "U_P702_MY2024_Rx" SG_ 130 SteeringColumnTorque 1;
BA_ "U_V713N_MY2022_Tx" SG_ 130 SteeringColumnTorque 1;
BA_ "U_P708_MY2023_Tx" SG_ 130 SteeringColumnTorque 1;
BA_ "U_CDX74X_MY2024_Tx" SG_ 130 SteeringColumnTorque 1;
BA_ "U_V710_MY2023_Tx" SG_ 130 SteeringColumnTorque 1;
BA_ "U_P702_MY2024_Tx" SG_ 130 SteeringColumnTorque 1;
BA_ "U_P708_MY2023_Rx" SG_ 130 SAPPAngleControlStat6 1;
BA_ "U_V710_MY2023_Rx" SG_ 130 SAPPAngleControlStat6 1;
BA_ "U_P702_MY2024_Rx" SG_ 130 SAPPAngleControlStat6 1;
BA_ "U_V713N_MY2022_Tx" SG_ 130 SAPPAngleControlStat6 1;
BA_ "U_P708_MY2023_Tx" SG_ 130 SAPPAngleControlStat6 1;
BA_ "U_CDX74X_MY2024_Tx" SG_ 130 SAPPAngleControlStat6 1;
BA_ "U_V710_MY2023_Tx" SG_ 130 SAPPAngleControlStat6 1;
BA_ "U_P702_MY2024_Tx" SG_ 130 SAPPAngleControlStat6 1;
BA_ "U_P708_MY2023_Rx" SG_ 130 SAPPAngleControlStat5 1;
BA_ "U_V710_MY2023_Rx" SG_ 130 SAPPAngleControlStat5 1;
BA_ "U_P702_MY2024_Rx" SG_ 130 SAPPAngleControlStat5 1;
BA_ "U_V713N_MY2022_Tx" SG_ 130 SAPPAngleControlStat5 1;
BA_ "U_P708_MY2023_Tx" SG_ 130 SAPPAngleControlStat5 1;
BA_ "U_CDX74X_MY2024_Tx" SG_ 130 SAPPAngleControlStat5 1;
BA_ "U_V710_MY2023_Tx" SG_ 130 SAPPAngleControlStat5 1;
BA_ "U_P702_MY2024_Tx" SG_ 130 SAPPAngleControlStat5 1;
BA_ "U_P708_MY2023_Rx" SG_ 130 SAPPAngleControlStat4 1;
BA_ "U_V710_MY2023_Rx" SG_ 130 SAPPAngleControlStat4 1;
BA_ "U_P702_MY2024_Rx" SG_ 130 SAPPAngleControlStat4 1;
BA_ "U_V713N_MY2022_Tx" SG_ 130 SAPPAngleControlStat4 1;
BA_ "U_P708_MY2023_Tx" SG_ 130 SAPPAngleControlStat4 1;
BA_ "U_CDX74X_MY2024_Tx" SG_ 130 SAPPAngleControlStat4 1;
BA_ "U_V710_MY2023_Tx" SG_ 130 SAPPAngleControlStat4 1;
BA_ "U_P702_MY2024_Tx" SG_ 130 SAPPAngleControlStat4 1;
BA_ "U_P708_MY2023_Rx" SG_ 130 SAPPAngleControlStat3 1;
BA_ "U_V710_MY2023_Rx" SG_ 130 SAPPAngleControlStat3 1;
BA_ "U_P702_MY2024_Rx" SG_ 130 SAPPAngleControlStat3 1;
BA_ "U_V713N_MY2022_Tx" SG_ 130 SAPPAngleControlStat3 1;
BA_ "U_P708_MY2023_Tx" SG_ 130 SAPPAngleControlStat3 1;
BA_ "U_CDX74X_MY2024_Tx" SG_ 130 SAPPAngleControlStat3 1;
BA_ "U_V710_MY2023_Tx" SG_ 130 SAPPAngleControlStat3 1;
BA_ "U_P702_MY2024_Tx" SG_ 130 SAPPAngleControlStat3 1;
BA_ "U_P708_MY2023_Rx" SG_ 130 SAPPAngleControlStat2 1;
BA_ "U_V710_MY2023_Rx" SG_ 130 SAPPAngleControlStat2 1;
BA_ "U_P702_MY2024_Rx" SG_ 130 SAPPAngleControlStat2 1;
BA_ "U_V713N_MY2022_Tx" SG_ 130 SAPPAngleControlStat2 1;
BA_ "U_P708_MY2023_Tx" SG_ 130 SAPPAngleControlStat2 1;
BA_ "U_CDX74X_MY2024_Tx" SG_ 130 SAPPAngleControlStat2 1;
BA_ "U_V710_MY2023_Tx" SG_ 130 SAPPAngleControlStat2 1;
BA_ "U_P702_MY2024_Tx" SG_ 130 SAPPAngleControlStat2 1;
BA_ "U_P708_MY2023_Rx" SG_ 130 SAPPAngleControlStat1 1;
BA_ "U_V710_MY2023_Rx" SG_ 130 SAPPAngleControlStat1 1;
BA_ "U_P702_MY2024_Rx" SG_ 130 SAPPAngleControlStat1 1;
BA_ "U_V713N_MY2022_Tx" SG_ 130 SAPPAngleControlStat1 1;
BA_ "U_P708_MY2023_Tx" SG_ 130 SAPPAngleControlStat1 1;
BA_ "U_CDX74X_MY2024_Tx" SG_ 130 SAPPAngleControlStat1 1;
BA_ "U_V710_MY2023_Tx" SG_ 130 SAPPAngleControlStat1 1;
BA_ "U_P702_MY2024_Tx" SG_ 130 SAPPAngleControlStat1 1;
BA_ "U_P708_MY2023_Rx" SG_ 1034 VehicleGGCCData 1;
BA_ "U_V710_MY2023_Rx" SG_ 1034 VehicleGGCCData 1;
BA_ "U_P702_MY2024_Rx" SG_ 1034 VehicleGGCCData 1;
BA_ "U_CDX74X_MY2024_Rx" SG_ 1034 VehicleGGCCData 1;
BA_ "U_V713N_MY2022_Rx" SG_ 1034 VehicleGGCCData 1;
BA_ "U_P708_MY2023_Rx" SG_ 894 RmtCtlKeySrch_D_Stat 1;
BA_ "U_P702_MY2024_Rx" SG_ 894 RmtCtlKeySrch_D_Stat 1;
BA_ "U_P708_MY2023_Rx" SG_ 894 RmtCtlBody_D_Stat 1;
BA_ "U_P702_MY2024_Rx" SG_ 894 RmtCtlBody_D_Stat 1;
BA_ "GenSigStartValue" SG_ 611 TrnAout_Tq_RqMx 8191;
BA_ "GenSigStartValue" SG_ 611 AwdRnge_D_Actl 7;
BA_ "U_P708_MY2023_Rx" SG_ 611 AwdRnge_D_Actl 1;
BA_ "U_V710_MY2023_Rx" SG_ 611 AwdRnge_D_Actl 1;
BA_ "U_P702_MY2024_Rx" SG_ 611 AwdRnge_D_Actl 1;
BA_ "MetaData" SG_ 534 WhlRotatRr_No_Cnt 1;
BA_ "U_P708_MY2023_Rx" SG_ 534 WhlRotatRr_No_Cnt 1;
BA_ "U_V710_MY2023_Rx" SG_ 534 WhlRotatRr_No_Cnt 1;
BA_ "U_P702_MY2024_Rx" SG_ 534 WhlRotatRr_No_Cnt 1;
BA_ "U_P708_MY2023_Rx" SG_ 534 WhlDirRr_D_Actl 1;
BA_ "U_CDX74X_MY2024_Rx" SG_ 534 WhlDirRr_D_Actl 1;
BA_ "U_V710_MY2023_Rx" SG_ 534 WhlDirRr_D_Actl 1;
BA_ "U_P702_MY2024_Rx" SG_ 534 WhlDirRr_D_Actl 1;
BA_ "U_P708_MY2023_Rx" SG_ 534 WhlDirRl_D_Actl 1;
BA_ "U_CDX74X_MY2024_Rx" SG_ 534 WhlDirRl_D_Actl 1;
BA_ "U_V710_MY2023_Rx" SG_ 534 WhlDirRl_D_Actl 1;
BA_ "U_P702_MY2024_Rx" SG_ 534 WhlDirRl_D_Actl 1;
BA_ "U_P708_MY2023_Rx" SG_ 534 WhlDirFr_D_Actl 1;
BA_ "U_CDX74X_MY2024_Rx" SG_ 534 WhlDirFr_D_Actl 1;
BA_ "U_V710_MY2023_Rx" SG_ 534 WhlDirFr_D_Actl 1;
BA_ "U_P702_MY2024_Rx" SG_ 534 WhlDirFr_D_Actl 1;
BA_ "U_P708_MY2023_Rx" SG_ 534 WhlDirFl_D_Actl 1;
BA_ "U_CDX74X_MY2024_Rx" SG_ 534 WhlDirFl_D_Actl 1;
BA_ "U_V710_MY2023_Rx" SG_ 534 WhlDirFl_D_Actl 1;
BA_ "U_P702_MY2024_Rx" SG_ 534 WhlDirFl_D_Actl 1;
BA_ "MetaData" SG_ 534 WhlRotatRl_No_Cnt 1;
BA_ "U_P708_MY2023_Rx" SG_ 534 WhlRotatRl_No_Cnt 1;
BA_ "U_V710_MY2023_Rx" SG_ 534 WhlRotatRl_No_Cnt 1;
BA_ "U_P702_MY2024_Rx" SG_ 534 WhlRotatRl_No_Cnt 1;
BA_ "MetaData" SG_ 534 WhlRotatFr_No_Cnt 1;
BA_ "U_P708_MY2023_Rx" SG_ 534 WhlRotatFr_No_Cnt 1;
BA_ "U_V710_MY2023_Rx" SG_ 534 WhlRotatFr_No_Cnt 1;
BA_ "U_P702_MY2024_Rx" SG_ 534 WhlRotatFr_No_Cnt 1;
BA_ "MetaData" SG_ 534 WhlRotatFl_No_Cnt 1;
BA_ "U_P708_MY2023_Rx" SG_ 534 WhlRotatFl_No_Cnt 1;
BA_ "U_V710_MY2023_Rx" SG_ 534 WhlRotatFl_No_Cnt 1;
BA_ "U_P702_MY2024_Rx" SG_ 534 WhlRotatFl_No_Cnt 1;
BA_ "GenSigStartValue" SG_ 533 ExtLghtRvrseOn_B_Rq 1;
BA_ "U_P708_MY2023_Rx" SG_ 533 ClrExitAsstEnbl_D_RqMnu 1;
BA_ "U_V710_MY2023_Rx" SG_ 533 ClrExitAsstEnbl_D_RqMnu 1;
BA_ "U_P702_MY2024_Rx" SG_ 533 ClrExitAsstEnbl_D_RqMnu 1;
BA_ "U_P708_MY2023_Rx" SG_ 533 TrlrAidMde_D_Rq 1;
BA_ "GenSigStartValue" SG_ 533 OnbChrgGoTOn_D_Rq 2;
BA_ "MetaData" SG_ 533 OnbChrgGoTMnte_D_Rq 1;
BA_ "GenSigStartValue" SG_ 533 OnbChrgGoTHr_T_Rq 30;
BA_ "MetaData" SG_ 533 OnbChrgGoTElement_D_Rq 1;
BA_ "WakeupSignal" SG_ 533 LghtAmbDrvMde_D_Rq 1;
BA_ "U_P708_MY2023_Rx" SG_ 533 TrlrHitch_D_RqMnu 1;
BA_ "U_V710_MY2023_Rx" SG_ 533 TrlrHitch_D_RqMnu 1;
BA_ "U_P702_MY2024_Rx" SG_ 533 TrlrHitch_D_RqMnu 1;
BA_ "U_P702_MY2024_Rx" SG_ 92 GearSelLck_D_Rq 1;
BA_ "U_V710_MY2023_Rx" SG_ 92 GearSelLck_D_Rq 1;
BA_ "U_CDX74X_MY2024_Rx" SG_ 92 GearSelLck_D_Rq 1;
BA_ "U_CDX707_MY2023_Rx" SG_ 92 GearSelLck_D_Rq 1;
BA_ "U_P702_MY2024_Rx" SG_ 92 TrnValidGear_D_Cnfm 1;
BA_ "U_V710_MY2023_Rx" SG_ 92 TrnValidGear_D_Cnfm 1;
BA_ "U_CDX74X_MY2024_Rx" SG_ 92 TrnValidGear_D_Cnfm 1;
BA_ "U_CDX707_MY2023_Rx" SG_ 92 TrnValidGear_D_Cnfm 1;
BA_ "ContentDependant" SG_ 92 TrnGearMsgTxt2_D_Rq 1;
BA_ "WakeupSignal" SG_ 92 TrnDtpCmd_D_Actl 1;
BA_ "GenSigStartValue" SG_ 92 TrnDtpCmd_D_Actl 1;
BA_ "MetaData" SG_ 92 TrnGearCmd_No_Cs 1;
BA_ "U_P708_MY2023_Rx" SG_ 92 TrnNtrlTowCmd_D_Actl 1;
BA_ "U_V710_MY2023_Rx" SG_ 92 TrnNtrlTowCmd_D_Actl 1;
BA_ "U_P702_MY2024_Rx" SG_ 92 TrnNtrlTowCmd_D_Actl 1;
BA_ "GenSigStartValue" SG_ 92 PrkBrkActv_D_RqTrnGear 1;
BA_ "MetaData" SG_ 92 TrnGearCmd_No_Cnt 1;
BA_ "GenSigSendType" SG_ 1848 TesterPhysicalResPSCM 3;
BA_ "U_V713N_MY2022_Tx" SG_ 1848 TesterPhysicalResPSCM 1;
BA_ "U_P708_MY2023_Tx" SG_ 1848 TesterPhysicalResPSCM 1;
BA_ "U_CDX74X_MY2024_Tx" SG_ 1848 TesterPhysicalResPSCM 1;
BA_ "U_V710_MY2023_Tx" SG_ 1848 TesterPhysicalResPSCM 1;
BA_ "U_P702_MY2024_Tx" SG_ 1848 TesterPhysicalResPSCM 1;
BA_ "GenSigSendType" SG_ 1840 TesterPhysicalReqPSCM 3;
BA_ "U_V713N_MY2022_Rx" SG_ 1840 TesterPhysicalReqPSCM 1;
BA_ "U_P708_MY2023_Rx" SG_ 1840 TesterPhysicalReqPSCM 1;
BA_ "U_CDX74X_MY2024_Rx" SG_ 1840 TesterPhysicalReqPSCM 1;
BA_ "U_V710_MY2023_Rx" SG_ 1840 TesterPhysicalReqPSCM 1;
BA_ "U_P702_MY2024_Rx" SG_ 1840 TesterPhysicalReqPSCM 1;
BA_ "GenSigStartValue" SG_ 570 SuspRearRight_L_Actl 511;
BA_ "GenSigStartValue" SG_ 570 SuspFrntRight_L_Actl 511;
BA_ "GenSigStartValue" SG_ 570 SuspRear_L_Prev 511;
BA_ "U_P708_MY2023_Rx" SG_ 570 SuspRear_L_Prev 1;
BA_ "U_CDX74X_MY2024_Rx" SG_ 570 SuspRear_L_Prev 1;
BA_ "U_V710_MY2023_Rx" SG_ 570 SuspRear_L_Prev 1;
BA_ "GenSigStartValue" SG_ 570 SuspRear_L_Actl 511;
BA_ "U_P708_MY2023_Rx" SG_ 570 SuspRear_L_Actl 1;
BA_ "U_CDX74X_MY2024_Rx" SG_ 570 SuspRear_L_Actl 1;
BA_ "U_V710_MY2023_Rx" SG_ 570 SuspRear_L_Actl 1;
BA_ "U_P702_MY2024_Rx" SG_ 570 SuspRear_L_Actl 1;
BA_ "GenSigStartValue" SG_ 570 SuspFrnt_L_Prev 511;
BA_ "U_P708_MY2023_Rx" SG_ 570 SuspFrnt_L_Prev 1;
BA_ "U_CDX74X_MY2024_Rx" SG_ 570 SuspFrnt_L_Prev 1;
BA_ "U_V710_MY2023_Rx" SG_ 570 SuspFrnt_L_Prev 1;
BA_ "GenSigStartValue" SG_ 570 SuspFrnt_L_Actl 511;
BA_ "U_P708_MY2023_Rx" SG_ 570 SuspFrnt_L_Actl 1;
BA_ "U_CDX74X_MY2024_Rx" SG_ 570 SuspFrnt_L_Actl 1;
BA_ "U_V710_MY2023_Rx" SG_ 570 SuspFrnt_L_Actl 1;
BA_ "U_P702_MY2024_Rx" SG_ 570 SuspFrnt_L_Actl 1;
BA_ "WakeupSignal" SG_ 131 HeadLghtHiCtrl_D_RqAhb 1;
BA_ "GenSigSendType" SG_ 131 HeadLghtHiCtrl_D_RqAhb 3;
BA_ "U_P708_MY2023_Rx" SG_ 131 HeadLghtHiCtrl_D_RqAhb 1;
BA_ "U_CDX74X_MY2024_Rx" SG_ 131 HeadLghtHiCtrl_D_RqAhb 1;
BA_ "U_V710_MY2023_Rx" SG_ 131 HeadLghtHiCtrl_D_RqAhb 1;
BA_ "U_P702_MY2024_Rx" SG_ 131 HeadLghtHiCtrl_D_RqAhb 1;
BA_ "U_P708_MY2023_Tx" SG_ 131 HeadLghtHiCtrl_D_RqAhb 1;
BA_ "U_V710_MY2023_Tx" SG_ 131 HeadLghtHiCtrl_D_RqAhb 1;
BA_ "U_P702_MY2024_Tx" SG_ 131 HeadLghtHiCtrl_D_RqAhb 1;
BA_ "GenSigSendType" SG_ 131 AhbStat_B_Dsply 3;
BA_ "U_P708_MY2023_Tx" SG_ 131 AhbStat_B_Dsply 1;
BA_ "U_V710_MY2023_Tx" SG_ 131 AhbStat_B_Dsply 1;
BA_ "U_P702_MY2024_Tx" SG_ 131 AhbStat_B_Dsply 1;
BA_ "GenSigStartValue" SG_ 131 WiprFrontSwtch_D_Stat 9;
BA_ "GenSigSendType" SG_ 131 WiprFrontSwtch_D_Stat 3;
BA_ "U_P708_MY2023_Tx" SG_ 131 WiprFrontSwtch_D_Stat 1;
BA_ "U_V710_MY2023_Tx" SG_ 131 WiprFrontSwtch_D_Stat 1;
BA_ "U_P702_MY2024_Tx" SG_ 131 WiprFrontSwtch_D_Stat 1;
BA_ "WakeupSignal" SG_ 131 HeadLghtHiOn_B_StatAhb 1;
BA_ "GenSigSendType" SG_ 131 HeadLghtHiOn_B_StatAhb 3;
BA_ "U_P708_MY2023_Rx" SG_ 131 HeadLghtHiOn_B_StatAhb 1;
BA_ "U_V710_MY2023_Rx" SG_ 131 HeadLghtHiOn_B_StatAhb 1;
BA_ "U_P702_MY2024_Rx" SG_ 131 HeadLghtHiOn_B_StatAhb 1;
BA_ "U_P708_MY2023_Tx" SG_ 131 HeadLghtHiOn_B_StatAhb 1;
BA_ "U_V710_MY2023_Tx" SG_ 131 HeadLghtHiOn_B_StatAhb 1;
BA_ "U_P702_MY2024_Tx" SG_ 131 HeadLghtHiOn_B_StatAhb 1;
BA_ "GenSigSendType" SG_ 131 HeadLghtHiFlash_D_Actl 3;
BA_ "U_P708_MY2023_Rx" SG_ 131 HeadLghtHiFlash_D_Actl 1;
BA_ "U_V710_MY2023_Rx" SG_ 131 HeadLghtHiFlash_D_Actl 1;
BA_ "U_P702_MY2024_Rx" SG_ 131 HeadLghtHiFlash_D_Actl 1;
BA_ "U_P708_MY2023_Tx" SG_ 131 HeadLghtHiFlash_D_Actl 1;
BA_ "U_V710_MY2023_Tx" SG_ 131 HeadLghtHiFlash_D_Actl 1;
BA_ "U_P702_MY2024_Tx" SG_ 131 HeadLghtHiFlash_D_Actl 1;
BA_ "GenSigSendType" SG_ 131 TjaButtnOnOffPress 3;
BA_ "U_P708_MY2023_Rx" SG_ 131 TjaButtnOnOffPress 1;
BA_ "U_V710_MY2023_Rx" SG_ 131 TjaButtnOnOffPress 1;
BA_ "U_P702_MY2024_Rx" SG_ 131 TjaButtnOnOffPress 1;
BA_ "U_P708_MY2023_Tx" SG_ 131 TjaButtnOnOffPress 1;
BA_ "U_V710_MY2023_Tx" SG_ 131 TjaButtnOnOffPress 1;
BA_ "U_P702_MY2024_Tx" SG_ 131 TjaButtnOnOffPress 1;
BA_ "GenSigSendType" SG_ 131 AccButtnGapTogglePress 3;
BA_ "U_P708_MY2023_Rx" SG_ 131 AccButtnGapTogglePress 1;
BA_ "U_V710_MY2023_Rx" SG_ 131 AccButtnGapTogglePress 1;
BA_ "U_P702_MY2024_Rx" SG_ 131 AccButtnGapTogglePress 1;
BA_ "U_P708_MY2023_Tx" SG_ 131 AccButtnGapTogglePress 1;
BA_ "U_V710_MY2023_Tx" SG_ 131 AccButtnGapTogglePress 1;
BA_ "U_P702_MY2024_Tx" SG_ 131 AccButtnGapTogglePress 1;
BA_ "GenSigStartValue" SG_ 131 WiprFront_D_Stat 15;
BA_ "GenSigSendType" SG_ 131 WiprFront_D_Stat 3;
BA_ "U_P708_MY2023_Rx" SG_ 131 WiprFront_D_Stat 1;
BA_ "U_CDX74X_MY2024_Rx" SG_ 131 WiprFront_D_Stat 1;
BA_ "U_V710_MY2023_Rx" SG_ 131 WiprFront_D_Stat 1;
BA_ "U_P702_MY2024_Rx" SG_ 131 WiprFront_D_Stat 1;
BA_ "ECGUsedRxSignal" SG_ 131 WiprFront_D_Stat 1;
BA_ "U_P708_MY2023_Tx" SG_ 131 WiprFront_D_Stat 1;
BA_ "U_V710_MY2023_Tx" SG_ 131 WiprFront_D_Stat 1;
BA_ "U_P702_MY2024_Tx" SG_ 131 WiprFront_D_Stat 1;
BA_ "WakeupSignal" SG_ 131 TurnLghtSwtch_D_Stat 1;
BA_ "GenSigSendType" SG_ 131 TurnLghtSwtch_D_Stat 3;
BA_ "U_P708_MY2023_Rx" SG_ 131 TurnLghtSwtch_D_Stat 1;
BA_ "U_CDX74X_MY2024_Rx" SG_ 131 TurnLghtSwtch_D_Stat 1;
BA_ "U_V710_MY2023_Rx" SG_ 131 TurnLghtSwtch_D_Stat 1;
BA_ "U_P702_MY2024_Rx" SG_ 131 TurnLghtSwtch_D_Stat 1;
BA_ "U_P708_MY2023_Tx" SG_ 131 TurnLghtSwtch_D_Stat 1;
BA_ "U_V710_MY2023_Tx" SG_ 131 TurnLghtSwtch_D_Stat 1;
BA_ "U_P702_MY2024_Tx" SG_ 131 TurnLghtSwtch_D_Stat 1;
BA_ "GenSigStartValue" SG_ 131 LghtAmb_D_Sns 7;
BA_ "GenSigSendType" SG_ 131 LghtAmb_D_Sns 3;
BA_ "U_P708_MY2023_Rx" SG_ 131 LghtAmb_D_Sns 1;
BA_ "U_CDX74X_MY2024_Rx" SG_ 131 LghtAmb_D_Sns 1;
BA_ "U_V710_MY2023_Rx" SG_ 131 LghtAmb_D_Sns 1;
BA_ "U_P702_MY2024_Rx" SG_ 131 LghtAmb_D_Sns 1;
BA_ "U_P708_MY2023_Tx" SG_ 131 LghtAmb_D_Sns 1;
BA_ "U_V710_MY2023_Tx" SG_ 131 LghtAmb_D_Sns 1;
BA_ "U_P702_MY2024_Tx" SG_ 131 LghtAmb_D_Sns 1;
BA_ "GenSigSendType" SG_ 131 AccButtnGapIncPress 3;
BA_ "U_P708_MY2023_Rx" SG_ 131 AccButtnGapIncPress 1;
BA_ "U_V710_MY2023_Rx" SG_ 131 AccButtnGapIncPress 1;
BA_ "U_P702_MY2024_Rx" SG_ 131 AccButtnGapIncPress 1;
BA_ "U_P708_MY2023_Tx" SG_ 131 AccButtnGapIncPress 1;
BA_ "U_V710_MY2023_Tx" SG_ 131 AccButtnGapIncPress 1;
BA_ "U_P702_MY2024_Tx" SG_ 131 AccButtnGapIncPress 1;
BA_ "GenSigSendType" SG_ 131 AccButtnGapDecPress 3;
BA_ "U_P708_MY2023_Rx" SG_ 131 AccButtnGapDecPress 1;
BA_ "U_V710_MY2023_Rx" SG_ 131 AccButtnGapDecPress 1;
BA_ "U_P702_MY2024_Rx" SG_ 131 AccButtnGapDecPress 1;
BA_ "U_P708_MY2023_Tx" SG_ 131 AccButtnGapDecPress 1;
BA_ "U_V710_MY2023_Tx" SG_ 131 AccButtnGapDecPress 1;
BA_ "U_P702_MY2024_Tx" SG_ 131 AccButtnGapDecPress 1;
BA_ "GenSigSendType" SG_ 131 AslButtnOnOffPress 3;
BA_ "U_P708_MY2023_Tx" SG_ 131 AslButtnOnOffPress 1;
BA_ "U_V710_MY2023_Tx" SG_ 131 AslButtnOnOffPress 1;
BA_ "U_P702_MY2024_Tx" SG_ 131 AslButtnOnOffPress 1;
BA_ "GenSigSendType" SG_ 131 AslButtnOnOffCnclPress 3;
BA_ "U_P708_MY2023_Tx" SG_ 131 AslButtnOnOffCnclPress 1;
BA_ "U_V710_MY2023_Tx" SG_ 131 AslButtnOnOffCnclPress 1;
BA_ "U_P702_MY2024_Tx" SG_ 131 AslButtnOnOffCnclPress 1;
BA_ "GenSigSendType" SG_ 131 CcButtnOnPress 3;
BA_ "U_P708_MY2023_Rx" SG_ 131 CcButtnOnPress 1;
BA_ "U_V710_MY2023_Rx" SG_ 131 CcButtnOnPress 1;
BA_ "U_P702_MY2024_Rx" SG_ 131 CcButtnOnPress 1;
BA_ "U_P708_MY2023_Tx" SG_ 131 CcButtnOnPress 1;
BA_ "U_V710_MY2023_Tx" SG_ 131 CcButtnOnPress 1;
BA_ "U_P702_MY2024_Tx" SG_ 131 CcButtnOnPress 1;
BA_ "GenSigSendType" SG_ 131 CcButtnOnOffPress 3;
BA_ "U_P708_MY2023_Rx" SG_ 131 CcButtnOnOffPress 1;
BA_ "U_V710_MY2023_Rx" SG_ 131 CcButtnOnOffPress 1;
BA_ "U_P702_MY2024_Rx" SG_ 131 CcButtnOnOffPress 1;
BA_ "U_P708_MY2023_Tx" SG_ 131 CcButtnOnOffPress 1;
BA_ "U_V710_MY2023_Tx" SG_ 131 CcButtnOnOffPress 1;
BA_ "U_P702_MY2024_Tx" SG_ 131 CcButtnOnOffPress 1;
BA_ "GenSigSendType" SG_ 131 CcButtnOnOffCnclPress 3;
BA_ "U_P708_MY2023_Rx" SG_ 131 CcButtnOnOffCnclPress 1;
BA_ "U_V710_MY2023_Rx" SG_ 131 CcButtnOnOffCnclPress 1;
BA_ "U_P702_MY2024_Rx" SG_ 131 CcButtnOnOffCnclPress 1;
BA_ "U_P708_MY2023_Tx" SG_ 131 CcButtnOnOffCnclPress 1;
BA_ "U_V710_MY2023_Tx" SG_ 131 CcButtnOnOffCnclPress 1;
BA_ "U_P702_MY2024_Tx" SG_ 131 CcButtnOnOffCnclPress 1;
BA_ "GenSigSendType" SG_ 131 CcButtnOffPress 3;
BA_ "U_P708_MY2023_Rx" SG_ 131 CcButtnOffPress 1;
BA_ "U_V710_MY2023_Rx" SG_ 131 CcButtnOffPress 1;
BA_ "U_P702_MY2024_Rx" SG_ 131 CcButtnOffPress 1;
BA_ "U_P708_MY2023_Tx" SG_ 131 CcButtnOffPress 1;
BA_ "U_V710_MY2023_Tx" SG_ 131 CcButtnOffPress 1;
BA_ "U_P702_MY2024_Tx" SG_ 131 CcButtnOffPress 1;
BA_ "GenSigSendType" SG_ 131 CcAsllButtnResPress 3;
BA_ "U_P708_MY2023_Rx" SG_ 131 CcAsllButtnResPress 1;
BA_ "U_V710_MY2023_Rx" SG_ 131 CcAsllButtnResPress 1;
BA_ "U_P702_MY2024_Rx" SG_ 131 CcAsllButtnResPress 1;
BA_ "U_P708_MY2023_Tx" SG_ 131 CcAsllButtnResPress 1;
BA_ "U_V710_MY2023_Tx" SG_ 131 CcAsllButtnResPress 1;
BA_ "U_P702_MY2024_Tx" SG_ 131 CcAsllButtnResPress 1;
BA_ "GenSigSendType" SG_ 131 CcAslButtnSetPress 3;
BA_ "U_P708_MY2023_Tx" SG_ 131 CcAslButtnSetPress 1;
BA_ "U_V710_MY2023_Tx" SG_ 131 CcAslButtnSetPress 1;
BA_ "U_P702_MY2024_Tx" SG_ 131 CcAslButtnSetPress 1;
BA_ "GenSigSendType" SG_ 131 CcAslButtnSetIncPress 3;
BA_ "U_P708_MY2023_Rx" SG_ 131 CcAslButtnSetIncPress 1;
BA_ "U_V710_MY2023_Rx" SG_ 131 CcAslButtnSetIncPress 1;
BA_ "U_P702_MY2024_Rx" SG_ 131 CcAslButtnSetIncPress 1;
BA_ "U_P708_MY2023_Tx" SG_ 131 CcAslButtnSetIncPress 1;
BA_ "U_V710_MY2023_Tx" SG_ 131 CcAslButtnSetIncPress 1;
BA_ "U_P702_MY2024_Tx" SG_ 131 CcAslButtnSetIncPress 1;
BA_ "GenSigSendType" SG_ 131 CcAslButtnSetDecPress 3;
BA_ "U_P708_MY2023_Rx" SG_ 131 CcAslButtnSetDecPress 1;
BA_ "U_V710_MY2023_Rx" SG_ 131 CcAslButtnSetDecPress 1;
BA_ "U_P702_MY2024_Rx" SG_ 131 CcAslButtnSetDecPress 1;
BA_ "U_P708_MY2023_Tx" SG_ 131 CcAslButtnSetDecPress 1;
BA_ "U_V710_MY2023_Tx" SG_ 131 CcAslButtnSetDecPress 1;
BA_ "U_P702_MY2024_Tx" SG_ 131 CcAslButtnSetDecPress 1;
BA_ "GenSigSendType" SG_ 131 CcAslButtnResIncPress 3;
BA_ "U_P708_MY2023_Rx" SG_ 131 CcAslButtnResIncPress 1;
BA_ "U_V710_MY2023_Rx" SG_ 131 CcAslButtnResIncPress 1;
BA_ "U_P702_MY2024_Rx" SG_ 131 CcAslButtnResIncPress 1;
BA_ "U_P708_MY2023_Tx" SG_ 131 CcAslButtnResIncPress 1;
BA_ "U_V710_MY2023_Tx" SG_ 131 CcAslButtnResIncPress 1;
BA_ "U_P702_MY2024_Tx" SG_ 131 CcAslButtnResIncPress 1;
BA_ "GenSigSendType" SG_ 131 CcAslButtnResDecPress 3;
BA_ "U_P708_MY2023_Tx" SG_ 131 CcAslButtnResDecPress 1;
BA_ "U_V710_MY2023_Tx" SG_ 131 CcAslButtnResDecPress 1;
BA_ "U_P702_MY2024_Tx" SG_ 131 CcAslButtnResDecPress 1;
BA_ "GenSigSendType" SG_ 131 CcAslButtnOnPress 3;
BA_ "U_P708_MY2023_Rx" SG_ 131 CcAslButtnOnPress 1;
BA_ "U_V710_MY2023_Rx" SG_ 131 CcAslButtnOnPress 1;
BA_ "U_P702_MY2024_Rx" SG_ 131 CcAslButtnOnPress 1;
BA_ "U_P708_MY2023_Tx" SG_ 131 CcAslButtnOnPress 1;
BA_ "U_V710_MY2023_Tx" SG_ 131 CcAslButtnOnPress 1;
BA_ "U_P702_MY2024_Tx" SG_ 131 CcAslButtnOnPress 1;
BA_ "GenSigSendType" SG_ 131 CcAslButtnOnOffCncl 3;
BA_ "U_P708_MY2023_Tx" SG_ 131 CcAslButtnOnOffCncl 1;
BA_ "U_V710_MY2023_Tx" SG_ 131 CcAslButtnOnOffCncl 1;
BA_ "U_P702_MY2024_Tx" SG_ 131 CcAslButtnOnOffCncl 1;
BA_ "GenSigSendType" SG_ 131 CcAslButtnOffCnclPress 3;
BA_ "U_P708_MY2023_Tx" SG_ 131 CcAslButtnOffCnclPress 1;
BA_ "U_V710_MY2023_Tx" SG_ 131 CcAslButtnOffCnclPress 1;
BA_ "U_P702_MY2024_Tx" SG_ 131 CcAslButtnOffCnclPress 1;
BA_ "GenSigSendType" SG_ 131 CcAslButtnIndxIncPress 3;
BA_ "U_P708_MY2023_Tx" SG_ 131 CcAslButtnIndxIncPress 1;
BA_ "U_V710_MY2023_Tx" SG_ 131 CcAslButtnIndxIncPress 1;
BA_ "U_P702_MY2024_Tx" SG_ 131 CcAslButtnIndxIncPress 1;
BA_ "GenSigSendType" SG_ 131 CcAslButtnIndxDecPress 3;
BA_ "U_P708_MY2023_Tx" SG_ 131 CcAslButtnIndxDecPress 1;
BA_ "U_V710_MY2023_Tx" SG_ 131 CcAslButtnIndxDecPress 1;
BA_ "U_P702_MY2024_Tx" SG_ 131 CcAslButtnIndxDecPress 1;
BA_ "GenSigSendType" SG_ 131 CcAslButtnDeny_B_Actl 3;
BA_ "U_P708_MY2023_Rx" SG_ 131 CcAslButtnDeny_B_Actl 1;
BA_ "U_V710_MY2023_Rx" SG_ 131 CcAslButtnDeny_B_Actl 1;
BA_ "U_P702_MY2024_Rx" SG_ 131 CcAslButtnDeny_B_Actl 1;
BA_ "U_P708_MY2023_Tx" SG_ 131 CcAslButtnDeny_B_Actl 1;
BA_ "U_V710_MY2023_Tx" SG_ 131 CcAslButtnDeny_B_Actl 1;
BA_ "U_P702_MY2024_Tx" SG_ 131 CcAslButtnDeny_B_Actl 1;
BA_ "GenSigSendType" SG_ 131 CcAslButtnCnclResPress 3;
BA_ "U_P708_MY2023_Rx" SG_ 131 CcAslButtnCnclResPress 1;
BA_ "U_V710_MY2023_Rx" SG_ 131 CcAslButtnCnclResPress 1;
BA_ "U_P702_MY2024_Rx" SG_ 131 CcAslButtnCnclResPress 1;
BA_ "U_P708_MY2023_Tx" SG_ 131 CcAslButtnCnclResPress 1;
BA_ "U_V710_MY2023_Tx" SG_ 131 CcAslButtnCnclResPress 1;
BA_ "U_P702_MY2024_Tx" SG_ 131 CcAslButtnCnclResPress 1;
BA_ "GenSigSendType" SG_ 131 CcAslButtnCnclPress 3;
BA_ "U_P708_MY2023_Rx" SG_ 131 CcAslButtnCnclPress 1;
BA_ "U_V710_MY2023_Rx" SG_ 131 CcAslButtnCnclPress 1;
BA_ "U_P702_MY2024_Rx" SG_ 131 CcAslButtnCnclPress 1;
BA_ "U_P708_MY2023_Tx" SG_ 131 CcAslButtnCnclPress 1;
BA_ "U_V710_MY2023_Tx" SG_ 131 CcAslButtnCnclPress 1;
BA_ "U_P702_MY2024_Tx" SG_ 131 CcAslButtnCnclPress 1;
BA_ "GenSigSendType" SG_ 131 LaSwtchPos_D_Stat 3;
BA_ "U_P708_MY2023_Rx" SG_ 131 LaSwtchPos_D_Stat 1;
BA_ "U_V710_MY2023_Rx" SG_ 131 LaSwtchPos_D_Stat 1;
BA_ "U_P702_MY2024_Rx" SG_ 131 LaSwtchPos_D_Stat 1;
BA_ "U_P708_MY2023_Tx" SG_ 131 LaSwtchPos_D_Stat 1;
BA_ "U_V710_MY2023_Tx" SG_ 131 LaSwtchPos_D_Stat 1;
BA_ "U_P702_MY2024_Tx" SG_ 131 LaSwtchPos_D_Stat 1;
BA_ "GenSigStartValue" SG_ 125 VehRolComp_W_Actl 4094;
BA_ "U_P708_MY2023_Rx" SG_ 125 VehRolComp_W_Actl 1;
BA_ "GenSigStartValue" SG_ 125 VehVertComp_A_Actl 1022;
BA_ "U_P708_MY2023_Rx" SG_ 125 VehVertComp_A_Actl 1;
BA_ "U_P702_MY2024_Rx" SG_ 125 VehVertComp_A_Actl 1;
BA_ "MetaData" SG_ 125 BrkTotTqRqArb_No_Cs 1;
BA_ "MetaData" SG_ 125 BrkTotTqRqArb_No_Cnt 1;
BA_ "U_P708_MY2023_Rx" SG_ 125 BrkTot_Tq_RqArb 1;
BA_ "U_CDX74X_MY2024_Rx" SG_ 125 BrkTot_Tq_RqArb 1;
BA_ "U_V710_MY2023_Rx" SG_ 125 BrkTot_Tq_RqArb 1;
BA_ "U_P702_MY2024_Rx" SG_ 125 BrkTot_Tq_RqArb 1;
BA_ "U_V713N_MY2022_Rx" SG_ 125 BrkTot_Tq_Actl 1;
BA_ "U_P708_MY2023_Rx" SG_ 125 BrkTot_Tq_Actl 1;
BA_ "U_CDX74X_MY2024_Rx" SG_ 125 BrkTot_Tq_Actl 1;
BA_ "U_V710_MY2023_Rx" SG_ 125 BrkTot_Tq_Actl 1;
BA_ "U_P702_MY2024_Rx" SG_ 125 BrkTot_Tq_Actl 1;
BA_ "GenSigStartValue" SG_ 119 VehTrvlDir_D_Stat 6;
BA_ "U_V713N_MY2022_Rx" SG_ 119 VehOverGnd_V_Est 1;
BA_ "U_P708_MY2023_Rx" SG_ 119 VehOverGnd_V_Est 1;
BA_ "U_CDX74X_MY2024_Rx" SG_ 119 VehOverGnd_V_Est 1;
BA_ "U_V710_MY2023_Rx" SG_ 119 VehOverGnd_V_Est 1;
BA_ "U_P702_MY2024_Rx" SG_ 119 VehOverGnd_V_Est 1;
BA_ "GenSigStartValue" SG_ 119 VehLongComp_A_Actl 1022;
BA_ "U_P708_MY2023_Rx" SG_ 119 VehLongComp_A_Actl 1;
BA_ "U_CDX74X_MY2024_Rx" SG_ 119 VehLongComp_A_Actl 1;
BA_ "U_V710_MY2023_Rx" SG_ 119 VehLongComp_A_Actl 1;
BA_ "U_P702_MY2024_Rx" SG_ 119 VehLongComp_A_Actl 1;
BA_ "GenSigStartValue" SG_ 119 VehLatComp_A_Actl 1022;
BA_ "U_P708_MY2023_Rx" SG_ 119 VehLatComp_A_Actl 1;
BA_ "U_CDX74X_MY2024_Rx" SG_ 119 VehLatComp_A_Actl 1;
BA_ "U_V710_MY2023_Rx" SG_ 119 VehLatComp_A_Actl 1;
BA_ "U_P702_MY2024_Rx" SG_ 119 VehLatComp_A_Actl 1;
BA_ "U_V713N_MY2022_Rx" SG_ 119 VehLatComp_A_Actl 1;
BA_ "GenSigStartValue" SG_ 119 VehYawComp_W_Actl 4094;
BA_ "U_V713N_MY2022_Rx" SG_ 119 VehYawComp_W_Actl 1;
BA_ "U_P708_MY2023_Rx" SG_ 119 VehYawComp_W_Actl 1;
BA_ "U_CDX74X_MY2024_Rx" SG_ 119 VehYawComp_W_Actl 1;
BA_ "U_V710_MY2023_Rx" SG_ 119 VehYawComp_W_Actl 1;
BA_ "U_P702_MY2024_Rx" SG_ 119 VehYawComp_W_Actl 1;
BA_ "MetaData" SG_ 118 SteWhlCompAnEst_D_Qf 1;
BA_ "GenSigStartValue" SG_ 1071 EngMnfld3_P_Actl 254;
BA_ "MetaData" SG_ 1071 CluPdlPosPcMeas_D_Qf 1;
BA_ "GenSigStartValue" SG_ 1071 CluPdlPosPcMeas_D_Qf 1;
BA_ "U_P708_MY2023_Rx" SG_ 1071 CluPdlPosPcMeas_D_Qf 1;
BA_ "U_CDX74X_MY2024_Rx" SG_ 1071 CluPdlPosPcMeas_D_Qf 1;
BA_ "U_V710_MY2023_Rx" SG_ 1071 CluPdlPosPcMeas_D_Qf 1;
BA_ "U_P702_MY2024_Rx" SG_ 1071 CluPdlPosPcMeas_D_Qf 1;
BA_ "U_P708_MY2023_Rx" SG_ 1071 CluPdlPos_Pc_Meas 1;
BA_ "U_CDX74X_MY2024_Rx" SG_ 1071 CluPdlPos_Pc_Meas 1;
BA_ "U_V710_MY2023_Rx" SG_ 1071 CluPdlPos_Pc_Meas 1;
BA_ "U_P702_MY2024_Rx" SG_ 1071 CluPdlPos_Pc_Meas 1;
BA_ "GenSigStartValue" SG_ 942 ApaOffOptnSel_B_Avail 1;
BA_ "GenSigSendType" SG_ 942 ApaOffOptnSel_B_Avail 3;
BA_ "U_P708_MY2023_Tx" SG_ 942 ApaOffOptnSel_B_Avail 1;
BA_ "U_V710_MY2023_Tx" SG_ 942 ApaOffOptnSel_B_Avail 1;
BA_ "U_P702_MY2024_Tx" SG_ 942 ApaOffOptnSel_B_Avail 1;
BA_ "GenSigSendType" SG_ 942 ApaSlotOption_B_Avail 3;
BA_ "U_P708_MY2023_Tx" SG_ 942 ApaSlotOption_B_Avail 1;
BA_ "U_V710_MY2023_Tx" SG_ 942 ApaSlotOption_B_Avail 1;
BA_ "U_P702_MY2024_Tx" SG_ 942 ApaSlotOption_B_Avail 1;
BA_ "GenSigSendType" SG_ 942 ApaSlotAlrtSet_B_Stat 3;
BA_ "U_P708_MY2023_Tx" SG_ 942 ApaSlotAlrtSet_B_Stat 1;
BA_ "U_V710_MY2023_Tx" SG_ 942 ApaSlotAlrtSet_B_Stat 1;
BA_ "U_P702_MY2024_Tx" SG_ 942 ApaSlotAlrtSet_B_Stat 1;
BA_ "GenSigSendType" SG_ 942 ApaSlotAlrt_B_Rq 3;
BA_ "U_P708_MY2023_Tx" SG_ 942 ApaSlotAlrt_B_Rq 1;
BA_ "U_V710_MY2023_Tx" SG_ 942 ApaSlotAlrt_B_Rq 1;
BA_ "U_P702_MY2024_Tx" SG_ 942 ApaSlotAlrt_B_Rq 1;
BA_ "GenSigSendType" SG_ 942 ApaRmtFeatSel_B_Avail 3;
BA_ "U_P708_MY2023_Tx" SG_ 942 ApaRmtFeatSel_B_Avail 1;
BA_ "U_V710_MY2023_Tx" SG_ 942 ApaRmtFeatSel_B_Avail 1;
BA_ "U_P702_MY2024_Tx" SG_ 942 ApaRmtFeatSel_B_Avail 1;
BA_ "GenSigSendType" SG_ 942 ApaParkOutSel_B_Avail 3;
BA_ "U_P708_MY2023_Tx" SG_ 942 ApaParkOutSel_B_Avail 1;
BA_ "U_V710_MY2023_Tx" SG_ 942 ApaParkOutSel_B_Avail 1;
BA_ "U_P702_MY2024_Tx" SG_ 942 ApaParkOutSel_B_Avail 1;
BA_ "GenSigSendType" SG_ 942 ApaSys_D2_Stat 3;
BA_ "U_P708_MY2023_Tx" SG_ 942 ApaSys_D2_Stat 1;
BA_ "U_V710_MY2023_Tx" SG_ 942 ApaSys_D2_Stat 1;
BA_ "U_P702_MY2024_Tx" SG_ 942 ApaSys_D2_Stat 1;
BA_ "GenSigSendType" SG_ 942 ApaSlotTrgt_D_Stat 3;
BA_ "U_P708_MY2023_Tx" SG_ 942 ApaSlotTrgt_D_Stat 1;
BA_ "U_V710_MY2023_Tx" SG_ 942 ApaSlotTrgt_D_Stat 1;
BA_ "U_P702_MY2024_Tx" SG_ 942 ApaSlotTrgt_D_Stat 1;
BA_ "GenSigSendType" SG_ 942 ApaParkInSel_B_Avail 3;
BA_ "U_P708_MY2023_Tx" SG_ 942 ApaParkInSel_B_Avail 1;
BA_ "U_V710_MY2023_Tx" SG_ 942 ApaParkInSel_B_Avail 1;
BA_ "U_P702_MY2024_Tx" SG_ 942 ApaParkInSel_B_Avail 1;
BA_ "GenSigSendType" SG_ 942 ApaMsgTxt_D2_Stat 3;
BA_ "U_P708_MY2023_Tx" SG_ 942 ApaMsgTxt_D2_Stat 1;
BA_ "U_V710_MY2023_Tx" SG_ 942 ApaMsgTxt_D2_Stat 1;
BA_ "U_P702_MY2024_Tx" SG_ 942 ApaMsgTxt_D2_Stat 1;
BA_ "GenSigSendType" SG_ 942 ApaDynmcSlot_B_Stat 3;
BA_ "U_P708_MY2023_Tx" SG_ 942 ApaDynmcSlot_B_Stat 1;
BA_ "U_V710_MY2023_Tx" SG_ 942 ApaDynmcSlot_B_Stat 1;
BA_ "U_P702_MY2024_Tx" SG_ 942 ApaDynmcSlot_B_Stat 1;
BA_ "GenSigSendType" SG_ 942 ApaDisplayMode_D_Stat 3;
BA_ "U_P708_MY2023_Tx" SG_ 942 ApaDisplayMode_D_Stat 1;
BA_ "U_V710_MY2023_Tx" SG_ 942 ApaDisplayMode_D_Stat 1;
BA_ "U_P702_MY2024_Tx" SG_ 942 ApaDisplayMode_D_Stat 1;
BA_ "GenSigSendType" SG_ 942 ApaControlMode_D_Stat 3;
BA_ "U_P708_MY2023_Tx" SG_ 942 ApaControlMode_D_Stat 1;
BA_ "U_V710_MY2023_Tx" SG_ 942 ApaControlMode_D_Stat 1;
BA_ "U_P702_MY2024_Tx" SG_ 942 ApaControlMode_D_Stat 1;
BA_ "GenSigSendType" SG_ 942 PrkBrkElRleas_B_RqApa 3;
BA_ "U_P708_MY2023_Tx" SG_ 942 PrkBrkElRleas_B_RqApa 1;
BA_ "U_V710_MY2023_Tx" SG_ 942 PrkBrkElRleas_B_RqApa 1;
BA_ "U_P702_MY2024_Tx" SG_ 942 PrkBrkElRleas_B_RqApa 1;
BA_ "GenSigSendType" SG_ 942 PrkAidAcsyRear_D_Stat 3;
BA_ "U_P708_MY2023_Tx" SG_ 942 PrkAidAcsyRear_D_Stat 1;
BA_ "U_V710_MY2023_Tx" SG_ 942 PrkAidAcsyRear_D_Stat 1;
BA_ "U_P702_MY2024_Tx" SG_ 942 PrkAidAcsyRear_D_Stat 1;
BA_ "GenSigSendType" SG_ 942 PrkAidAcsyFront_D_Stat 3;
BA_ "U_P708_MY2023_Tx" SG_ 942 PrkAidAcsyFront_D_Stat 1;
BA_ "U_V710_MY2023_Tx" SG_ 942 PrkAidAcsyFront_D_Stat 1;
BA_ "U_P702_MY2024_Tx" SG_ 942 PrkAidAcsyFront_D_Stat 1;
BA_ "GenSigSendType" SG_ 942 PrkAidRdiusRight_L_Dsply 3;
BA_ "U_P708_MY2023_Tx" SG_ 942 PrkAidRdiusRight_L_Dsply 1;
BA_ "U_V710_MY2023_Tx" SG_ 942 PrkAidRdiusRight_L_Dsply 1;
BA_ "U_P702_MY2024_Tx" SG_ 942 PrkAidRdiusRight_L_Dsply 1;
BA_ "GenSigSendType" SG_ 942 PrkAidRdiusLeft_L_Dsply 3;
BA_ "U_P708_MY2023_Tx" SG_ 942 PrkAidRdiusLeft_L_Dsply 1;
BA_ "U_V710_MY2023_Tx" SG_ 942 PrkAidRdiusLeft_L_Dsply 1;
BA_ "U_P702_MY2024_Tx" SG_ 942 PrkAidRdiusLeft_L_Dsply 1;
BA_ "GenSigSendType" SG_ 942 PrkAidDrvDir_D_Stat 3;
BA_ "U_P708_MY2023_Tx" SG_ 942 PrkAidDrvDir_D_Stat 1;
BA_ "U_V710_MY2023_Tx" SG_ 942 PrkAidDrvDir_D_Stat 1;
BA_ "U_P702_MY2024_Tx" SG_ 942 PrkAidDrvDir_D_Stat 1;
BA_ "GenSigSendType" SG_ 942 ApaDrvRq2MsgTxt_D_Rq 3;
BA_ "U_P708_MY2023_Tx" SG_ 942 ApaDrvRq2MsgTxt_D_Rq 1;
BA_ "U_V710_MY2023_Tx" SG_ 942 ApaDrvRq2MsgTxt_D_Rq 1;
BA_ "U_P702_MY2024_Tx" SG_ 942 ApaDrvRq2MsgTxt_D_Rq 1;
BA_ "GenSigSendType" SG_ 942 ApaDrvRq1MsgTxt_D_Rq 3;
BA_ "U_P708_MY2023_Tx" SG_ 942 ApaDrvRq1MsgTxt_D_Rq 1;
BA_ "U_V710_MY2023_Tx" SG_ 942 ApaDrvRq1MsgTxt_D_Rq 1;
BA_ "U_P702_MY2024_Tx" SG_ 942 ApaDrvRq1MsgTxt_D_Rq 1;
BA_ "GenSigSendType" SG_ 939 DrTgateMde_D_Stat 3;
BA_ "U_P708_MY2023_Tx" SG_ 939 DrTgateMde_D_Stat 1;
BA_ "U_P702_MY2024_Tx" SG_ 939 DrTgateMde_D_Stat 1;
BA_ "GenSigSendType" SG_ 939 SidePrkSnsR4_D_Stat 3;
BA_ "U_P708_MY2023_Tx" SG_ 939 SidePrkSnsR4_D_Stat 1;
BA_ "U_V710_MY2023_Tx" SG_ 939 SidePrkSnsR4_D_Stat 1;
BA_ "U_P702_MY2024_Tx" SG_ 939 SidePrkSnsR4_D_Stat 1;
BA_ "GenSigSendType" SG_ 939 SidePrkSnsR3_D_Stat 3;
BA_ "U_P708_MY2023_Tx" SG_ 939 SidePrkSnsR3_D_Stat 1;
BA_ "U_V710_MY2023_Tx" SG_ 939 SidePrkSnsR3_D_Stat 1;
BA_ "U_P702_MY2024_Tx" SG_ 939 SidePrkSnsR3_D_Stat 1;
BA_ "GenSigSendType" SG_ 939 SidePrkSnsL4_D_Stat 3;
BA_ "U_P708_MY2023_Tx" SG_ 939 SidePrkSnsL4_D_Stat 1;
BA_ "U_V710_MY2023_Tx" SG_ 939 SidePrkSnsL4_D_Stat 1;
BA_ "U_P702_MY2024_Tx" SG_ 939 SidePrkSnsL4_D_Stat 1;
BA_ "GenSigSendType" SG_ 939 SidePrkSnsL3_D_Stat 3;
BA_ "U_P708_MY2023_Tx" SG_ 939 SidePrkSnsL3_D_Stat 1;
BA_ "U_V710_MY2023_Tx" SG_ 939 SidePrkSnsL3_D_Stat 1;
BA_ "U_P702_MY2024_Tx" SG_ 939 SidePrkSnsL3_D_Stat 1;
BA_ "GenSigSendType" SG_ 939 PrkAidChime_D_Stat 3;
BA_ "U_P708_MY2023_Tx" SG_ 939 PrkAidChime_D_Stat 1;
BA_ "U_V710_MY2023_Tx" SG_ 939 PrkAidChime_D_Stat 1;
BA_ "U_P702_MY2024_Tx" SG_ 939 PrkAidChime_D_Stat 1;
BA_ "GenSigSendType" SG_ 939 PrkAidSnsRlCntr_D_Stat 3;
BA_ "U_P708_MY2023_Tx" SG_ 939 PrkAidSnsRlCntr_D_Stat 1;
BA_ "U_V710_MY2023_Tx" SG_ 939 PrkAidSnsRlCntr_D_Stat 1;
BA_ "U_P702_MY2024_Tx" SG_ 939 PrkAidSnsRlCntr_D_Stat 1;
BA_ "GenSigSendType" SG_ 939 PrkAidSnsRrCrnr_D_Stat 3;
BA_ "U_P708_MY2023_Tx" SG_ 939 PrkAidSnsRrCrnr_D_Stat 1;
BA_ "U_V710_MY2023_Tx" SG_ 939 PrkAidSnsRrCrnr_D_Stat 1;
BA_ "U_P702_MY2024_Tx" SG_ 939 PrkAidSnsRrCrnr_D_Stat 1;
BA_ "GenSigSendType" SG_ 939 PrkAidSnsRrCntr_D_Stat 3;
BA_ "U_P708_MY2023_Tx" SG_ 939 PrkAidSnsRrCntr_D_Stat 1;
BA_ "U_V710_MY2023_Tx" SG_ 939 PrkAidSnsRrCntr_D_Stat 1;
BA_ "U_P702_MY2024_Tx" SG_ 939 PrkAidSnsRrCntr_D_Stat 1;
BA_ "GenSigSendType" SG_ 939 PrkAidSnsRlCrnr_D_Stat 3;
BA_ "U_P708_MY2023_Tx" SG_ 939 PrkAidSnsRlCrnr_D_Stat 1;
BA_ "U_V710_MY2023_Tx" SG_ 939 PrkAidSnsRlCrnr_D_Stat 1;
BA_ "U_P702_MY2024_Tx" SG_ 939 PrkAidSnsRlCrnr_D_Stat 1;
BA_ "GenSigSendType" SG_ 939 PrkAidRear_D_Stat 3;
BA_ "U_P708_MY2023_Tx" SG_ 939 PrkAidRear_D_Stat 1;
BA_ "U_V710_MY2023_Tx" SG_ 939 PrkAidRear_D_Stat 1;
BA_ "U_P702_MY2024_Tx" SG_ 939 PrkAidRear_D_Stat 1;
BA_ "GenSigSendType" SG_ 939 PrkAidFront_D_Stat 3;
BA_ "U_P708_MY2023_Tx" SG_ 939 PrkAidFront_D_Stat 1;
BA_ "U_V710_MY2023_Tx" SG_ 939 PrkAidFront_D_Stat 1;
BA_ "U_P702_MY2024_Tx" SG_ 939 PrkAidFront_D_Stat 1;
BA_ "GenSigSendType" SG_ 939 PrkAid_D_Falt 3;
BA_ "U_P708_MY2023_Tx" SG_ 939 PrkAid_D_Falt 1;
BA_ "U_V710_MY2023_Tx" SG_ 939 PrkAid_D_Falt 1;
BA_ "U_P702_MY2024_Tx" SG_ 939 PrkAid_D_Falt 1;
BA_ "GenSigSendType" SG_ 939 ApaLongCtrlEnbl_D_Rq 3;
BA_ "U_P708_MY2023_Tx" SG_ 939 ApaLongCtrlEnbl_D_Rq 1;
BA_ "U_V710_MY2023_Tx" SG_ 939 ApaLongCtrlEnbl_D_Rq 1;
BA_ "U_P702_MY2024_Tx" SG_ 939 ApaLongCtrlEnbl_D_Rq 1;
BA_ "GenSigStartValue" SG_ 939 ApaBrk_A_Rq 255;
BA_ "U_P708_MY2023_Tx" SG_ 939 ApaBrk_A_Rq 1;
BA_ "U_V710_MY2023_Tx" SG_ 939 ApaBrk_A_Rq 1;
BA_ "U_P702_MY2024_Tx" SG_ 939 ApaBrk_A_Rq 1;
BA_ "GenSigSendType" SG_ 939 PrkAidLamp_D_Rq 3;
BA_ "U_P708_MY2023_Tx" SG_ 939 PrkAidLamp_D_Rq 1;
BA_ "U_V710_MY2023_Tx" SG_ 939 PrkAidLamp_D_Rq 1;
BA_ "U_P702_MY2024_Tx" SG_ 939 PrkAidLamp_D_Rq 1;
BA_ "GenSigSendType" SG_ 939 ApaBrk_D_Rq 3;
BA_ "U_P708_MY2023_Tx" SG_ 939 ApaBrk_D_Rq 1;
BA_ "U_V710_MY2023_Tx" SG_ 939 ApaBrk_D_Rq 1;
BA_ "U_P702_MY2024_Tx" SG_ 939 ApaBrk_D_Rq 1;
BA_ "U_P708_MY2023_Tx" SG_ 939 ResPrkAidSnsRrSide_D_Stat 1;
BA_ "U_V710_MY2023_Tx" SG_ 939 ResPrkAidSnsRrSide_D_Stat 1;
BA_ "U_P702_MY2024_Tx" SG_ 939 ResPrkAidSnsRrSide_D_Stat 1;
BA_ "U_P708_MY2023_Tx" SG_ 939 ResPrkAidSnsRlSide_D_Stat 1;
BA_ "U_V710_MY2023_Tx" SG_ 939 ResPrkAidSnsRlSide_D_Stat 1;
BA_ "U_P702_MY2024_Tx" SG_ 939 ResPrkAidSnsRlSide_D_Stat 1;
BA_ "GenSigSendType" SG_ 938 SidePrkSnsR2_D_Stat 3;
BA_ "U_P708_MY2023_Tx" SG_ 938 SidePrkSnsR2_D_Stat 1;
BA_ "U_V710_MY2023_Tx" SG_ 938 SidePrkSnsR2_D_Stat 1;
BA_ "U_P702_MY2024_Tx" SG_ 938 SidePrkSnsR2_D_Stat 1;
BA_ "GenSigSendType" SG_ 938 SidePrkSnsR1_D_Stat 3;
BA_ "U_P708_MY2023_Tx" SG_ 938 SidePrkSnsR1_D_Stat 1;
BA_ "U_V710_MY2023_Tx" SG_ 938 SidePrkSnsR1_D_Stat 1;
BA_ "U_P702_MY2024_Tx" SG_ 938 SidePrkSnsR1_D_Stat 1;
BA_ "GenSigSendType" SG_ 938 SidePrkSnsL2_D_Stat 3;
BA_ "U_P708_MY2023_Tx" SG_ 938 SidePrkSnsL2_D_Stat 1;
BA_ "U_V710_MY2023_Tx" SG_ 938 SidePrkSnsL2_D_Stat 1;
BA_ "U_P702_MY2024_Tx" SG_ 938 SidePrkSnsL2_D_Stat 1;
BA_ "GenSigSendType" SG_ 938 ApaMde_D_Stat 3;
BA_ "U_P708_MY2023_Tx" SG_ 938 ApaMde_D_Stat 1;
BA_ "U_V710_MY2023_Tx" SG_ 938 ApaMde_D_Stat 1;
BA_ "U_P702_MY2024_Tx" SG_ 938 ApaMde_D_Stat 1;
BA_ "GenSigStartValue" SG_ 938 ApaActvSd_D_Actl 1;
BA_ "GenSigSendType" SG_ 938 ApaActvSd_D_Actl 3;
BA_ "U_P708_MY2023_Tx" SG_ 938 ApaActvSd_D_Actl 1;
BA_ "U_V710_MY2023_Tx" SG_ 938 ApaActvSd_D_Actl 1;
BA_ "U_P702_MY2024_Tx" SG_ 938 ApaActvSd_D_Actl 1;
BA_ "GenSigSendType" SG_ 938 PrkAidSwtch_B_Stat 3;
BA_ "U_P708_MY2023_Tx" SG_ 938 PrkAidSwtch_B_Stat 1;
BA_ "U_V710_MY2023_Tx" SG_ 938 PrkAidSwtch_B_Stat 1;
BA_ "U_P702_MY2024_Tx" SG_ 938 PrkAidSwtch_B_Stat 1;
BA_ "GenSigSendType" SG_ 938 ApaMde_D_Avail 3;
BA_ "U_P708_MY2023_Tx" SG_ 938 ApaMde_D_Avail 1;
BA_ "U_V710_MY2023_Tx" SG_ 938 ApaMde_D_Avail 1;
BA_ "U_P702_MY2024_Tx" SG_ 938 ApaMde_D_Avail 1;
BA_ "GenSigSendType" SG_ 938 PrkAidSnsFrCrnr_D_Stat 3;
BA_ "U_P708_MY2023_Tx" SG_ 938 PrkAidSnsFrCrnr_D_Stat 1;
BA_ "U_V710_MY2023_Tx" SG_ 938 PrkAidSnsFrCrnr_D_Stat 1;
BA_ "U_P702_MY2024_Tx" SG_ 938 PrkAidSnsFrCrnr_D_Stat 1;
BA_ "GenSigSendType" SG_ 938 PrkAidSnsFrCntr_D_Stat 3;
BA_ "U_P708_MY2023_Tx" SG_ 938 PrkAidSnsFrCntr_D_Stat 1;
BA_ "U_V710_MY2023_Tx" SG_ 938 PrkAidSnsFrCntr_D_Stat 1;
BA_ "U_P702_MY2024_Tx" SG_ 938 PrkAidSnsFrCntr_D_Stat 1;
BA_ "GenSigSendType" SG_ 938 PrkAidSnsFlCrnr_D_Stat 3;
BA_ "U_P708_MY2023_Tx" SG_ 938 PrkAidSnsFlCrnr_D_Stat 1;
BA_ "U_V710_MY2023_Tx" SG_ 938 PrkAidSnsFlCrnr_D_Stat 1;
BA_ "U_P702_MY2024_Tx" SG_ 938 PrkAidSnsFlCrnr_D_Stat 1;
BA_ "GenSigSendType" SG_ 938 PrkAidSnsFlCntr_D_Stat 3;
BA_ "U_P708_MY2023_Tx" SG_ 938 PrkAidSnsFlCntr_D_Stat 1;
BA_ "U_V710_MY2023_Tx" SG_ 938 PrkAidSnsFlCntr_D_Stat 1;
BA_ "U_P702_MY2024_Tx" SG_ 938 PrkAidSnsFlCntr_D_Stat 1;
BA_ "GenSigSendType" SG_ 938 PrkBrkEl_B_RqFap 3;
BA_ "U_P708_MY2023_Tx" SG_ 938 PrkBrkEl_B_RqFap 1;
BA_ "U_V710_MY2023_Tx" SG_ 938 PrkBrkEl_B_RqFap 1;
BA_ "U_P702_MY2024_Tx" SG_ 938 PrkBrkEl_B_RqFap 1;
BA_ "GenSigSendType" SG_ 938 RpaChime_D_Rq 3;
BA_ "U_P708_MY2023_Tx" SG_ 938 RpaChime_D_Rq 1;
BA_ "U_V710_MY2023_Tx" SG_ 938 RpaChime_D_Rq 1;
BA_ "U_P702_MY2024_Tx" SG_ 938 RpaChime_D_Rq 1;
BA_ "GenSigSendType" SG_ 938 FpaChime_D_Rq 3;
BA_ "U_P708_MY2023_Tx" SG_ 938 FpaChime_D_Rq 1;
BA_ "U_V710_MY2023_Tx" SG_ 938 FpaChime_D_Rq 1;
BA_ "U_P702_MY2024_Tx" SG_ 938 FpaChime_D_Rq 1;
BA_ "GenSigSendType" SG_ 938 PrkAidMsgTxt_D_Rq 3;
BA_ "U_P708_MY2023_Rx" SG_ 938 PrkAidMsgTxt_D_Rq 1;
BA_ "U_P702_MY2024_Rx" SG_ 938 PrkAidMsgTxt_D_Rq 1;
BA_ "U_P708_MY2023_Tx" SG_ 938 PrkAidMsgTxt_D_Rq 1;
BA_ "U_V710_MY2023_Tx" SG_ 938 PrkAidMsgTxt_D_Rq 1;
BA_ "U_P702_MY2024_Tx" SG_ 938 PrkAidMsgTxt_D_Rq 1;
BA_ "GenSigSendType" SG_ 938 SidePrkSnsL1_D_Stat 3;
BA_ "U_P708_MY2023_Tx" SG_ 938 SidePrkSnsL1_D_Stat 1;
BA_ "U_V710_MY2023_Tx" SG_ 938 SidePrkSnsL1_D_Stat 1;
BA_ "U_P702_MY2024_Tx" SG_ 938 SidePrkSnsL1_D_Stat 1;
BA_ "GenSigSendType" SG_ 938 PrkAidAudioMute_B_Rq 3;
BA_ "U_P708_MY2023_Tx" SG_ 938 PrkAidAudioMute_B_Rq 1;
BA_ "U_V710_MY2023_Tx" SG_ 938 PrkAidAudioMute_B_Rq 1;
BA_ "U_P702_MY2024_Tx" SG_ 938 PrkAidAudioMute_B_Rq 1;
BA_ "U_P708_MY2023_Tx" SG_ 937 Veh_V_RqFap 1;
BA_ "U_V710_MY2023_Tx" SG_ 937 Veh_V_RqFap 1;
BA_ "U_P702_MY2024_Tx" SG_ 937 Veh_V_RqFap 1;
BA_ "MetaData" SG_ 937 TrnRngDRqFap_No_Cs 1;
BA_ "U_P708_MY2023_Tx" SG_ 937 TrnRngDRqFap_No_Cs 1;
BA_ "U_V710_MY2023_Tx" SG_ 937 TrnRngDRqFap_No_Cs 1;
BA_ "U_P702_MY2024_Tx" SG_ 937 TrnRngDRqFap_No_Cs 1;
BA_ "MetaData" SG_ 937 TrnRngDRqFap_No_Cnt 1;
BA_ "U_P708_MY2023_Tx" SG_ 937 TrnRngDRqFap_No_Cnt 1;
BA_ "U_V710_MY2023_Tx" SG_ 937 TrnRngDRqFap_No_Cnt 1;
BA_ "U_P702_MY2024_Tx" SG_ 937 TrnRngDRqFap_No_Cnt 1;
BA_ "U_P708_MY2023_Tx" SG_ 937 TrnRng_D_RqFap 1;
BA_ "U_V710_MY2023_Tx" SG_ 937 TrnRng_D_RqFap 1;
BA_ "U_P702_MY2024_Tx" SG_ 937 TrnRng_D_RqFap 1;
BA_ "GenSigStartValue" SG_ 937 FapLcDistToObj_L_Actl 254;
BA_ "U_P708_MY2023_Tx" SG_ 937 FapLcDistToObj_L_Actl 1;
BA_ "U_V710_MY2023_Tx" SG_ 937 FapLcDistToObj_L_Actl 1;
BA_ "U_P702_MY2024_Tx" SG_ 937 FapLcDistToObj_L_Actl 1;
BA_ "U_P708_MY2023_Rx" SG_ 936 ApaSys_D_Stat 1;
BA_ "U_CDX74X_MY2024_Rx" SG_ 936 ApaSys_D_Stat 1;
BA_ "U_V710_MY2023_Rx" SG_ 936 ApaSys_D_Stat 1;
BA_ "U_P702_MY2024_Rx" SG_ 936 ApaSys_D_Stat 1;
BA_ "U_P708_MY2023_Tx" SG_ 936 ApaSys_D_Stat 1;
BA_ "U_V710_MY2023_Tx" SG_ 936 ApaSys_D_Stat 1;
BA_ "U_P702_MY2024_Tx" SG_ 936 ApaSys_D_Stat 1;
BA_ "U_P708_MY2023_Tx" SG_ 936 ApaSteWhl_D_RqDrv 1;
BA_ "U_V710_MY2023_Tx" SG_ 936 ApaSteWhl_D_RqDrv 1;
BA_ "U_P702_MY2024_Tx" SG_ 936 ApaSteWhl_D_RqDrv 1;
BA_ "U_P708_MY2023_Tx" SG_ 936 ApaSteScanMde_D_Stat 1;
BA_ "U_V710_MY2023_Tx" SG_ 936 ApaSteScanMde_D_Stat 1;
BA_ "U_P702_MY2024_Tx" SG_ 936 ApaSteScanMde_D_Stat 1;
BA_ "U_P708_MY2023_Tx" SG_ 936 ApaSelSapp_D_Stat 1;
BA_ "U_V710_MY2023_Tx" SG_ 936 ApaSelSapp_D_Stat 1;
BA_ "U_P702_MY2024_Tx" SG_ 936 ApaSelSapp_D_Stat 1;
BA_ "U_P708_MY2023_Tx" SG_ 936 ApaSelPpa_D_Stat 1;
BA_ "U_V710_MY2023_Tx" SG_ 936 ApaSelPpa_D_Stat 1;
BA_ "U_P702_MY2024_Tx" SG_ 936 ApaSelPpa_D_Stat 1;
BA_ "U_P708_MY2023_Tx" SG_ 936 ApaSelPoa_D_Stat 1;
BA_ "U_V710_MY2023_Tx" SG_ 936 ApaSelPoa_D_Stat 1;
BA_ "U_P702_MY2024_Tx" SG_ 936 ApaSelPoa_D_Stat 1;
BA_ "U_P708_MY2023_Tx" SG_ 936 ApaScan_D_Stat 1;
BA_ "U_V710_MY2023_Tx" SG_ 936 ApaScan_D_Stat 1;
BA_ "U_P702_MY2024_Tx" SG_ 936 ApaScan_D_Stat 1;
BA_ "U_P708_MY2023_Tx" SG_ 936 ApaLongCtl_D_RqDrv 1;
BA_ "U_V710_MY2023_Tx" SG_ 936 ApaLongCtl_D_RqDrv 1;
BA_ "U_P702_MY2024_Tx" SG_ 936 ApaLongCtl_D_RqDrv 1;
BA_ "U_P708_MY2023_Tx" SG_ 936 ApaGearShif_D_RqDrv 1;
BA_ "U_V710_MY2023_Tx" SG_ 936 ApaGearShif_D_RqDrv 1;
BA_ "U_P702_MY2024_Tx" SG_ 936 ApaGearShif_D_RqDrv 1;
BA_ "U_P708_MY2023_Tx" SG_ 936 ApaActvSide2_D_Stat 1;
BA_ "U_V710_MY2023_Tx" SG_ 936 ApaActvSide2_D_Stat 1;
BA_ "U_P702_MY2024_Tx" SG_ 936 ApaActvSide2_D_Stat 1;
BA_ "U_P708_MY2023_Tx" SG_ 936 ApaAcsy_D_RqDrv 1;
BA_ "U_V710_MY2023_Tx" SG_ 936 ApaAcsy_D_RqDrv 1;
BA_ "U_P702_MY2024_Tx" SG_ 936 ApaAcsy_D_RqDrv 1;
BA_ "U_P708_MY2023_Tx" SG_ 936 ApaTrgtDist_D_Stat 1;
BA_ "U_V710_MY2023_Tx" SG_ 936 ApaTrgtDist_D_Stat 1;
BA_ "U_P702_MY2024_Tx" SG_ 936 ApaTrgtDist_D_Stat 1;
BA_ "U_P708_MY2023_Tx" SG_ 936 ApaMsgTxt_D_Rq 1;
BA_ "U_V710_MY2023_Tx" SG_ 936 ApaMsgTxt_D_Rq 1;
BA_ "U_P702_MY2024_Tx" SG_ 936 ApaMsgTxt_D_Rq 1;
BA_ "U_P708_MY2023_Tx" SG_ 936 ApaChime_D_Rq 1;
BA_ "U_V710_MY2023_Tx" SG_ 936 ApaChime_D_Rq 1;
BA_ "U_P702_MY2024_Tx" SG_ 936 ApaChime_D_Rq 1;
BA_ "U_P708_MY2023_Rx" SG_ 936 SAPPStatusCoding 1;
BA_ "U_P708_MY2023_Tx" SG_ 936 SAPPStatusCoding 1;
BA_ "U_V710_MY2023_Tx" SG_ 936 SAPPStatusCoding 1;
BA_ "U_P702_MY2024_Tx" SG_ 936 SAPPStatusCoding 1;
BA_ "U_P708_MY2023_Rx" SG_ 936 EPASExtAngleStatReq 1;
BA_ "U_CDX74X_MY2024_Rx" SG_ 936 EPASExtAngleStatReq 1;
BA_ "U_V710_MY2023_Rx" SG_ 936 EPASExtAngleStatReq 1;
BA_ "U_P702_MY2024_Rx" SG_ 936 EPASExtAngleStatReq 1;
BA_ "U_P708_MY2023_Tx" SG_ 936 EPASExtAngleStatReq 1;
BA_ "U_V710_MY2023_Tx" SG_ 936 EPASExtAngleStatReq 1;
BA_ "U_P702_MY2024_Tx" SG_ 936 EPASExtAngleStatReq 1;
BA_ "U_P708_MY2023_Rx" SG_ 936 ExtSteeringAngleReq2 1;
BA_ "U_CDX74X_MY2024_Rx" SG_ 936 ExtSteeringAngleReq2 1;
BA_ "U_V710_MY2023_Rx" SG_ 936 ExtSteeringAngleReq2 1;
BA_ "U_P702_MY2024_Rx" SG_ 936 ExtSteeringAngleReq2 1;
BA_ "U_P708_MY2023_Tx" SG_ 936 ExtSteeringAngleReq2 1;
BA_ "U_V710_MY2023_Tx" SG_ 936 ExtSteeringAngleReq2 1;
BA_ "U_P702_MY2024_Tx" SG_ 936 ExtSteeringAngleReq2 1;
BA_ "U_P708_MY2023_Rx" SG_ 936 ApaButtnPrssd_B_Stat 1;
BA_ "U_P702_MY2024_Rx" SG_ 936 ApaButtnPrssd_B_Stat 1;
BA_ "U_P708_MY2023_Tx" SG_ 936 ApaButtnPrssd_B_Stat 1;
BA_ "U_V710_MY2023_Tx" SG_ 936 ApaButtnPrssd_B_Stat 1;
BA_ "U_P702_MY2024_Tx" SG_ 936 ApaButtnPrssd_B_Stat 1;
BA_ "U_P708_MY2023_Rx" SG_ 154 TronTripCnt_No_Actl 1;
BA_ "U_CDX74X_MY2024_Rx" SG_ 154 TronTripCnt_No_Actl 1;
BA_ "U_V710_MY2023_Rx" SG_ 154 TronTripCnt_No_Actl 1;
BA_ "U_P702_MY2024_Rx" SG_ 154 TronTripCnt_No_Actl 1;
BA_ "ECGUsedTxSignal" SG_ 154 TronTripCnt_No_Actl 1;
BA_ "U_P708_MY2023_Tx" SG_ 154 TronTripCnt_No_Actl 1;
BA_ "U_CDX74X_MY2024_Tx" SG_ 154 TronTripCnt_No_Actl 1;
BA_ "U_V710_MY2023_Tx" SG_ 154 TronTripCnt_No_Actl 1;
BA_ "U_P702_MY2024_Tx" SG_ 154 TronTripCnt_No_Actl 1;
BA_ "U_P708_MY2023_Rx" SG_ 154 TronResetCnt_No_Actl 1;
BA_ "U_CDX74X_MY2024_Rx" SG_ 154 TronResetCnt_No_Actl 1;
BA_ "U_V710_MY2023_Rx" SG_ 154 TronResetCnt_No_Actl 1;
BA_ "U_P702_MY2024_Rx" SG_ 154 TronResetCnt_No_Actl 1;
BA_ "ECGUsedTxSignal" SG_ 154 TronResetCnt_No_Actl 1;
BA_ "U_P708_MY2023_Tx" SG_ 154 TronResetCnt_No_Actl 1;
BA_ "U_CDX74X_MY2024_Tx" SG_ 154 TronResetCnt_No_Actl 1;
BA_ "U_V710_MY2023_Tx" SG_ 154 TronResetCnt_No_Actl 1;
BA_ "U_P702_MY2024_Tx" SG_ 154 TronResetCnt_No_Actl 1;
BA_ "GenSigSendType" SG_ 2614099160 SymKeyFuncGWM_ECG 3;
BA_ "U_P708_MY2023_Rx" SG_ 2614099160 SymKeyFuncGWM_ECG 1;
BA_ "U_CDX74X_MY2024_Rx" SG_ 2614099160 SymKeyFuncGWM_ECG 1;
BA_ "U_V710_MY2023_Rx" SG_ 2614099160 SymKeyFuncGWM_ECG 1;
BA_ "U_P702_MY2024_Rx" SG_ 2614099160 SymKeyFuncGWM_ECG 1;
BA_ "ECGUsedTxSignal" SG_ 2614099160 SymKeyFuncGWM_ECG 1;
BA_ "U_P708_MY2023_Tx" SG_ 2614099160 SymKeyFuncGWM_ECG 1;
BA_ "U_CDX74X_MY2024_Tx" SG_ 2614099160 SymKeyFuncGWM_ECG 1;
BA_ "U_V710_MY2023_Tx" SG_ 2614099160 SymKeyFuncGWM_ECG 1;
BA_ "U_P702_MY2024_Tx" SG_ 2614099160 SymKeyFuncGWM_ECG 1;
BA_ "GenSigSendType" SG_ 2613272609 SymKeyPhysIPMAtoGWM_ECG 3;
BA_ "ECGUsedRxSignal" SG_ 2613272609 SymKeyPhysIPMAtoGWM_ECG 1;
BA_ "U_P708_MY2023_Rx" SG_ 2613272609 SymKeyPhysIPMAtoGWM_ECG 1;
BA_ "U_CDX74X_MY2024_Rx" SG_ 2613272609 SymKeyPhysIPMAtoGWM_ECG 1;
BA_ "U_V710_MY2023_Rx" SG_ 2613272609 SymKeyPhysIPMAtoGWM_ECG 1;
BA_ "U_P702_MY2024_Rx" SG_ 2613272609 SymKeyPhysIPMAtoGWM_ECG 1;
BA_ "U_P708_MY2023_Tx" SG_ 2613272609 SymKeyPhysIPMAtoGWM_ECG 1;
BA_ "U_V710_MY2023_Tx" SG_ 2613272609 SymKeyPhysIPMAtoGWM_ECG 1;
BA_ "U_P702_MY2024_Tx" SG_ 2613272609 SymKeyPhysIPMAtoGWM_ECG 1;
BA_ "GenSigSendType" SG_ 2613085400 SymKeyPhysGWM_ECGtoIPMA 3;
BA_ "U_P708_MY2023_Rx" SG_ 2613085400 SymKeyPhysGWM_ECGtoIPMA 1;
BA_ "U_V710_MY2023_Rx" SG_ 2613085400 SymKeyPhysGWM_ECGtoIPMA 1;
BA_ "U_P702_MY2024_Rx" SG_ 2613085400 SymKeyPhysGWM_ECGtoIPMA 1;
BA_ "ECGUsedTxSignal" SG_ 2613085400 SymKeyPhysGWM_ECGtoIPMA 1;
BA_ "U_P708_MY2023_Tx" SG_ 2613085400 SymKeyPhysGWM_ECGtoIPMA 1;
BA_ "U_CDX74X_MY2024_Tx" SG_ 2613085400 SymKeyPhysGWM_ECGtoIPMA 1;
BA_ "U_V710_MY2023_Tx" SG_ 2613085400 SymKeyPhysGWM_ECGtoIPMA 1;
BA_ "U_P702_MY2024_Tx" SG_ 2613085400 SymKeyPhysGWM_ECGtoIPMA 1;
BA_ "GenSigSendType" SG_ 2613272624 SymKeyPhysPSCMtoGWM_ECG 3;
BA_ "ECGUsedRxSignal" SG_ 2613272624 SymKeyPhysPSCMtoGWM_ECG 1;
BA_ "U_P708_MY2023_Rx" SG_ 2613272624 SymKeyPhysPSCMtoGWM_ECG 1;
BA_ "U_CDX74X_MY2024_Rx" SG_ 2613272624 SymKeyPhysPSCMtoGWM_ECG 1;
BA_ "U_V710_MY2023_Rx" SG_ 2613272624 SymKeyPhysPSCMtoGWM_ECG 1;
BA_ "U_P702_MY2024_Rx" SG_ 2613272624 SymKeyPhysPSCMtoGWM_ECG 1;
BA_ "U_V713N_MY2022_Tx" SG_ 2613272624 SymKeyPhysPSCMtoGWM_ECG 1;
BA_ "U_P708_MY2023_Tx" SG_ 2613272624 SymKeyPhysPSCMtoGWM_ECG 1;
BA_ "U_CDX74X_MY2024_Tx" SG_ 2613272624 SymKeyPhysPSCMtoGWM_ECG 1;
BA_ "U_V710_MY2023_Tx" SG_ 2613272624 SymKeyPhysPSCMtoGWM_ECG 1;
BA_ "U_P702_MY2024_Tx" SG_ 2613272624 SymKeyPhysPSCMtoGWM_ECG 1;
BA_ "GenSigSendType" SG_ 2613100760 SymKeyPhysGWM_ECGtoPSCM 3;
BA_ "U_P708_MY2023_Rx" SG_ 2613100760 SymKeyPhysGWM_ECGtoPSCM 1;
BA_ "U_CDX74X_MY2024_Rx" SG_ 2613100760 SymKeyPhysGWM_ECGtoPSCM 1;
BA_ "U_V710_MY2023_Rx" SG_ 2613100760 SymKeyPhysGWM_ECGtoPSCM 1;
BA_ "U_P702_MY2024_Rx" SG_ 2613100760 SymKeyPhysGWM_ECGtoPSCM 1;
BA_ "ECGUsedTxSignal" SG_ 2613100760 SymKeyPhysGWM_ECGtoPSCM 1;
BA_ "U_P708_MY2023_Tx" SG_ 2613100760 SymKeyPhysGWM_ECGtoPSCM 1;
BA_ "U_CDX74X_MY2024_Tx" SG_ 2613100760 SymKeyPhysGWM_ECGtoPSCM 1;
BA_ "U_V710_MY2023_Tx" SG_ 2613100760 SymKeyPhysGWM_ECGtoPSCM 1;
BA_ "U_P702_MY2024_Tx" SG_ 2613100760 SymKeyPhysGWM_ECGtoPSCM 1;
BA_ "MetaData" SG_ 145 VehYawWActl_D_Qf 1;
BA_ "GenSigStartValue" SG_ 145 VehYawWActl_D_Qf 1;
BA_ "U_P708_MY2023_Rx" SG_ 145 VehYawWActl_D_Qf 1;
BA_ "U_CDX74X_MY2024_Rx" SG_ 145 VehYawWActl_D_Qf 1;
BA_ "U_V710_MY2023_Rx" SG_ 145 VehYawWActl_D_Qf 1;
BA_ "U_P702_MY2024_Rx" SG_ 145 VehYawWActl_D_Qf 1;
BA_ "MetaData" SG_ 145 VehRolWActl_D_Qf 1;
BA_ "GenSigStartValue" SG_ 145 VehRolWActl_D_Qf 1;
BA_ "U_P708_MY2023_Rx" SG_ 145 VehRolWActl_D_Qf 1;
BA_ "U_V710_MY2023_Rx" SG_ 145 VehRolWActl_D_Qf 1;
BA_ "U_P702_MY2024_Rx" SG_ 145 VehRolWActl_D_Qf 1;
BA_ "MetaData" SG_ 145 VehRollYawW_No_Cs 1;
BA_ "U_P708_MY2023_Rx" SG_ 145 VehRollYawW_No_Cs 1;
BA_ "U_V710_MY2023_Rx" SG_ 145 VehRollYawW_No_Cs 1;
BA_ "U_P702_MY2024_Rx" SG_ 145 VehRollYawW_No_Cs 1;
BA_ "MetaData" SG_ 145 VehRollYaw_No_Cnt 1;
BA_ "U_P708_MY2023_Rx" SG_ 145 VehRollYaw_No_Cnt 1;
BA_ "U_V710_MY2023_Rx" SG_ 145 VehRollYaw_No_Cnt 1;
BA_ "U_P702_MY2024_Rx" SG_ 145 VehRollYaw_No_Cnt 1;
BA_ "GenSigStartValue" SG_ 145 VehYaw_W_Actl 65534;
BA_ "U_P708_MY2023_Rx" SG_ 145 VehYaw_W_Actl 1;
BA_ "U_CDX74X_MY2024_Rx" SG_ 145 VehYaw_W_Actl 1;
BA_ "U_V710_MY2023_Rx" SG_ 145 VehYaw_W_Actl 1;
BA_ "U_P702_MY2024_Rx" SG_ 145 VehYaw_W_Actl 1;
BA_ "U_V713N_MY2022_Rx" SG_ 145 VehYaw_W_Actl 1;
BA_ "GenSigStartValue" SG_ 145 VehRol_W_Actl 65534;
BA_ "U_P708_MY2023_Rx" SG_ 145 VehRol_W_Actl 1;
BA_ "U_V710_MY2023_Rx" SG_ 145 VehRol_W_Actl 1;
BA_ "U_P702_MY2024_Rx" SG_ 145 VehRol_W_Actl 1;
BA_ "GenSigSendType" SG_ 2612224099 PARSEDPushSODRtoGWM_ECG 3;
BA_ "ECGUsedRxSignal" SG_ 2612224099 PARSEDPushSODRtoGWM_ECG 1;
BA_ "U_P708_MY2023_Rx" SG_ 2612224099 PARSEDPushSODRtoGWM_ECG 1;
BA_ "U_P702_MY2024_Rx" SG_ 2612224099 PARSEDPushSODRtoGWM_ECG 1;
BA_ "U_P708_MY2023_Tx" SG_ 2612224099 PARSEDPushSODRtoGWM_ECG 1;
BA_ "U_V710_MY2023_Tx" SG_ 2612224099 PARSEDPushSODRtoGWM_ECG 1;
BA_ "U_P702_MY2024_Tx" SG_ 2612224099 PARSEDPushSODRtoGWM_ECG 1;
BA_ "GenSigSendType" SG_ 2612224098 PARSEDPushSODLtoGWM_ECG 3;
BA_ "ECGUsedRxSignal" SG_ 2612224098 PARSEDPushSODLtoGWM_ECG 1;
BA_ "U_P708_MY2023_Rx" SG_ 2612224098 PARSEDPushSODLtoGWM_ECG 1;
BA_ "U_P702_MY2024_Rx" SG_ 2612224098 PARSEDPushSODLtoGWM_ECG 1;
BA_ "U_P708_MY2023_Tx" SG_ 2612224098 PARSEDPushSODLtoGWM_ECG 1;
BA_ "U_V710_MY2023_Tx" SG_ 2612224098 PARSEDPushSODLtoGWM_ECG 1;
BA_ "U_P702_MY2024_Tx" SG_ 2612224098 PARSEDPushSODLtoGWM_ECG 1;
BA_ "GenSigSendType" SG_ 2612224070 PARSEDPushSODCMDtoECG 3;
BA_ "ECGUsedRxSignal" SG_ 2612224070 PARSEDPushSODCMDtoECG 1;
BA_ "U_P708_MY2023_Rx" SG_ 2612224070 PARSEDPushSODCMDtoECG 1;
BA_ "U_V710_MY2023_Rx" SG_ 2612224070 PARSEDPushSODCMDtoECG 1;
BA_ "U_P702_MY2024_Rx" SG_ 2612224070 PARSEDPushSODCMDtoECG 1;
BA_ "U_P708_MY2023_Tx" SG_ 2612224070 PARSEDPushSODCMDtoECG 1;
BA_ "U_P702_MY2024_Tx" SG_ 2612224070 PARSEDPushSODCMDtoECG 1;
BA_ "U_V713N_MY2022_Rx" SG_ 535 WhlRr_W_Meas 1;
BA_ "U_P708_MY2023_Rx" SG_ 535 WhlRr_W_Meas 1;
BA_ "U_CDX74X_MY2024_Rx" SG_ 535 WhlRr_W_Meas 1;
BA_ "U_V710_MY2023_Rx" SG_ 535 WhlRr_W_Meas 1;
BA_ "U_P702_MY2024_Rx" SG_ 535 WhlRr_W_Meas 1;
BA_ "U_V713N_MY2022_Rx" SG_ 535 WhlRl_W_Meas 1;
BA_ "U_P708_MY2023_Rx" SG_ 535 WhlRl_W_Meas 1;
BA_ "U_CDX74X_MY2024_Rx" SG_ 535 WhlRl_W_Meas 1;
BA_ "U_V710_MY2023_Rx" SG_ 535 WhlRl_W_Meas 1;
BA_ "U_P702_MY2024_Rx" SG_ 535 WhlRl_W_Meas 1;
BA_ "U_V713N_MY2022_Rx" SG_ 535 WhlFr_W_Meas 1;
BA_ "U_P708_MY2023_Rx" SG_ 535 WhlFr_W_Meas 1;
BA_ "U_CDX74X_MY2024_Rx" SG_ 535 WhlFr_W_Meas 1;
BA_ "U_V710_MY2023_Rx" SG_ 535 WhlFr_W_Meas 1;
BA_ "U_P702_MY2024_Rx" SG_ 535 WhlFr_W_Meas 1;
BA_ "U_V713N_MY2022_Rx" SG_ 535 WhlFl_W_Meas 1;
BA_ "U_P708_MY2023_Rx" SG_ 535 WhlFl_W_Meas 1;
BA_ "U_CDX74X_MY2024_Rx" SG_ 535 WhlFl_W_Meas 1;
BA_ "U_V710_MY2023_Rx" SG_ 535 WhlFl_W_Meas 1;
BA_ "U_P702_MY2024_Rx" SG_ 535 WhlFl_W_Meas 1;
BA_ "GenSigSendType" SG_ 2612224069 PARSEDPushSODCMCtoECG 3;
BA_ "ECGUsedRxSignal" SG_ 2612224069 PARSEDPushSODCMCtoECG 1;
BA_ "U_P708_MY2023_Rx" SG_ 2612224069 PARSEDPushSODCMCtoECG 1;
BA_ "U_V710_MY2023_Rx" SG_ 2612224069 PARSEDPushSODCMCtoECG 1;
BA_ "U_P702_MY2024_Rx" SG_ 2612224069 PARSEDPushSODCMCtoECG 1;
BA_ "U_P708_MY2023_Tx" SG_ 2612224069 PARSEDPushSODCMCtoECG 1;
BA_ "U_V710_MY2023_Tx" SG_ 2612224069 PARSEDPushSODCMCtoECG 1;
BA_ "U_P702_MY2024_Tx" SG_ 2612224069 PARSEDPushSODCMCtoECG 1;
BA_ "GenSigSendType" SG_ 2612224048 PARSEDPushPSCMtoGWM_ECG 3;
BA_ "ECGUsedRxSignal" SG_ 2612224048 PARSEDPushPSCMtoGWM_ECG 1;
BA_ "U_P708_MY2023_Rx" SG_ 2612224048 PARSEDPushPSCMtoGWM_ECG 1;
BA_ "U_CDX74X_MY2024_Rx" SG_ 2612224048 PARSEDPushPSCMtoGWM_ECG 1;
BA_ "U_V710_MY2023_Rx" SG_ 2612224048 PARSEDPushPSCMtoGWM_ECG 1;
BA_ "U_P702_MY2024_Rx" SG_ 2612224048 PARSEDPushPSCMtoGWM_ECG 1;
BA_ "U_V713N_MY2022_Tx" SG_ 2612224048 PARSEDPushPSCMtoGWM_ECG 1;
BA_ "U_P708_MY2023_Tx" SG_ 2612224048 PARSEDPushPSCMtoGWM_ECG 1;
BA_ "U_CDX74X_MY2024_Tx" SG_ 2612224048 PARSEDPushPSCMtoGWM_ECG 1;
BA_ "U_V710_MY2023_Tx" SG_ 2612224048 PARSEDPushPSCMtoGWM_ECG 1;
BA_ "U_P702_MY2024_Tx" SG_ 2612224048 PARSEDPushPSCMtoGWM_ECG 1;
BA_ "GenSigSendType" SG_ 2612224033 PARSEDPushIPMAtoGWM_ECG 3;
BA_ "ECGUsedRxSignal" SG_ 2612224033 PARSEDPushIPMAtoGWM_ECG 1;
BA_ "U_P708_MY2023_Rx" SG_ 2612224033 PARSEDPushIPMAtoGWM_ECG 1;
BA_ "U_CDX74X_MY2024_Rx" SG_ 2612224033 PARSEDPushIPMAtoGWM_ECG 1;
BA_ "U_V710_MY2023_Rx" SG_ 2612224033 PARSEDPushIPMAtoGWM_ECG 1;
BA_ "U_P702_MY2024_Rx" SG_ 2612224033 PARSEDPushIPMAtoGWM_ECG 1;
BA_ "U_P708_MY2023_Tx" SG_ 2612224033 PARSEDPushIPMAtoGWM_ECG 1;
BA_ "U_V710_MY2023_Tx" SG_ 2612224033 PARSEDPushIPMAtoGWM_ECG 1;
BA_ "U_P702_MY2024_Tx" SG_ 2612224033 PARSEDPushIPMAtoGWM_ECG 1;
BA_ "GenSigSendType" SG_ 2612224113 PARSEDPushHCMtoGWM_ECG 3;
BA_ "ECGUsedRxSignal" SG_ 2612224113 PARSEDPushHCMtoGWM_ECG 1;
BA_ "U_P708_MY2023_Rx" SG_ 2612224113 PARSEDPushHCMtoGWM_ECG 1;
BA_ "U_CDX74X_MY2024_Rx" SG_ 2612224113 PARSEDPushHCMtoGWM_ECG 1;
BA_ "U_V710_MY2023_Rx" SG_ 2612224113 PARSEDPushHCMtoGWM_ECG 1;
BA_ "U_P702_MY2024_Rx" SG_ 2612224113 PARSEDPushHCMtoGWM_ECG 1;
BA_ "U_P708_MY2023_Tx" SG_ 2612224113 PARSEDPushHCMtoGWM_ECG 1;
BA_ "U_CDX74X_MY2024_Tx" SG_ 2612224113 PARSEDPushHCMtoGWM_ECG 1;
BA_ "U_V710_MY2023_Tx" SG_ 2612224113 PARSEDPushHCMtoGWM_ECG 1;
BA_ "U_P702_MY2024_Tx" SG_ 2612224113 PARSEDPushHCMtoGWM_ECG 1;
BA_ "GenSigSendType" SG_ 2612104408 PARSEDPushFcGWM_ECGtoSODR 3;
BA_ "U_P708_MY2023_Rx" SG_ 2612104408 PARSEDPushFcGWM_ECGtoSODR 1;
BA_ "U_V710_MY2023_Rx" SG_ 2612104408 PARSEDPushFcGWM_ECGtoSODR 1;
BA_ "U_P702_MY2024_Rx" SG_ 2612104408 PARSEDPushFcGWM_ECGtoSODR 1;
BA_ "ECGUsedTxSignal" SG_ 2612104408 PARSEDPushFcGWM_ECGtoSODR 1;
BA_ "U_P708_MY2023_Tx" SG_ 2612104408 PARSEDPushFcGWM_ECGtoSODR 1;
BA_ "U_P702_MY2024_Tx" SG_ 2612104408 PARSEDPushFcGWM_ECGtoSODR 1;
BA_ "GenSigSendType" SG_ 2612103384 PARSEDPushFcGWM_ECGtoSODL 3;
BA_ "U_P708_MY2023_Rx" SG_ 2612103384 PARSEDPushFcGWM_ECGtoSODL 1;
BA_ "U_V710_MY2023_Rx" SG_ 2612103384 PARSEDPushFcGWM_ECGtoSODL 1;
BA_ "U_P702_MY2024_Rx" SG_ 2612103384 PARSEDPushFcGWM_ECGtoSODL 1;
BA_ "ECGUsedTxSignal" SG_ 2612103384 PARSEDPushFcGWM_ECGtoSODL 1;
BA_ "U_P708_MY2023_Tx" SG_ 2612103384 PARSEDPushFcGWM_ECGtoSODL 1;
BA_ "U_P702_MY2024_Tx" SG_ 2612103384 PARSEDPushFcGWM_ECGtoSODL 1;
BA_ "GenSigSendType" SG_ 2612074712 PARSEDPushFcECGtoSODCMD 3;
BA_ "U_P708_MY2023_Rx" SG_ 2612074712 PARSEDPushFcECGtoSODCMD 1;
BA_ "U_V710_MY2023_Rx" SG_ 2612074712 PARSEDPushFcECGtoSODCMD 1;
BA_ "U_P702_MY2024_Rx" SG_ 2612074712 PARSEDPushFcECGtoSODCMD 1;
BA_ "ECGUsedTxSignal" SG_ 2612074712 PARSEDPushFcECGtoSODCMD 1;
BA_ "U_P708_MY2023_Tx" SG_ 2612074712 PARSEDPushFcECGtoSODCMD 1;
BA_ "U_V710_MY2023_Tx" SG_ 2612074712 PARSEDPushFcECGtoSODCMD 1;
BA_ "U_P702_MY2024_Tx" SG_ 2612074712 PARSEDPushFcECGtoSODCMD 1;
BA_ "GenSigSendType" SG_ 2612118744 PARSEDPushFcGWM_ECGtoHCM 3;
BA_ "U_P708_MY2023_Rx" SG_ 2612118744 PARSEDPushFcGWM_ECGtoHCM 1;
BA_ "U_CDX74X_MY2024_Rx" SG_ 2612118744 PARSEDPushFcGWM_ECGtoHCM 1;
BA_ "U_V710_MY2023_Rx" SG_ 2612118744 PARSEDPushFcGWM_ECGtoHCM 1;
BA_ "U_P702_MY2024_Rx" SG_ 2612118744 PARSEDPushFcGWM_ECGtoHCM 1;
BA_ "ECGUsedTxSignal" SG_ 2612118744 PARSEDPushFcGWM_ECGtoHCM 1;
BA_ "U_P708_MY2023_Tx" SG_ 2612118744 PARSEDPushFcGWM_ECGtoHCM 1;
BA_ "U_CDX74X_MY2024_Tx" SG_ 2612118744 PARSEDPushFcGWM_ECGtoHCM 1;
BA_ "U_V710_MY2023_Tx" SG_ 2612118744 PARSEDPushFcGWM_ECGtoHCM 1;
BA_ "U_P702_MY2024_Tx" SG_ 2612118744 PARSEDPushFcGWM_ECGtoHCM 1;
BA_ "GenSigSendType" SG_ 2610982104 PARSEDPhysGWM_ECGtoGSM 3;
BA_ "ECGUsedTxSignal" SG_ 2610982104 PARSEDPhysGWM_ECGtoGSM 1;
BA_ "U_P708_MY2023_Tx" SG_ 2610982104 PARSEDPhysGWM_ECGtoGSM 1;
BA_ "U_P702_MY2024_Tx" SG_ 2610982104 PARSEDPhysGWM_ECGtoGSM 1;
BA_ "GenSigSendType" SG_ 2612052184 PARSEDPushFcGWM_ECGtoPSCM 3;
BA_ "U_V713N_MY2022_Rx" SG_ 2612052184 PARSEDPushFcGWM_ECGtoPSCM 1;
BA_ "U_P708_MY2023_Rx" SG_ 2612052184 PARSEDPushFcGWM_ECGtoPSCM 1;
BA_ "U_CDX74X_MY2024_Rx" SG_ 2612052184 PARSEDPushFcGWM_ECGtoPSCM 1;
BA_ "U_V710_MY2023_Rx" SG_ 2612052184 PARSEDPushFcGWM_ECGtoPSCM 1;
BA_ "U_P702_MY2024_Rx" SG_ 2612052184 PARSEDPushFcGWM_ECGtoPSCM 1;
BA_ "ECGUsedTxSignal" SG_ 2612052184 PARSEDPushFcGWM_ECGtoPSCM 1;
BA_ "U_P708_MY2023_Tx" SG_ 2612052184 PARSEDPushFcGWM_ECGtoPSCM 1;
BA_ "U_CDX74X_MY2024_Tx" SG_ 2612052184 PARSEDPushFcGWM_ECGtoPSCM 1;
BA_ "U_V710_MY2023_Tx" SG_ 2612052184 PARSEDPushFcGWM_ECGtoPSCM 1;
BA_ "U_P702_MY2024_Tx" SG_ 2612052184 PARSEDPushFcGWM_ECGtoPSCM 1;
BA_ "GenSigSendType" SG_ 2612036824 PARSEDPushFcGWM_ECGtoIPMA 3;
BA_ "U_P708_MY2023_Rx" SG_ 2612036824 PARSEDPushFcGWM_ECGtoIPMA 1;
BA_ "U_V710_MY2023_Rx" SG_ 2612036824 PARSEDPushFcGWM_ECGtoIPMA 1;
BA_ "U_P702_MY2024_Rx" SG_ 2612036824 PARSEDPushFcGWM_ECGtoIPMA 1;
BA_ "ECGUsedTxSignal" SG_ 2612036824 PARSEDPushFcGWM_ECGtoIPMA 1;
BA_ "U_P708_MY2023_Tx" SG_ 2612036824 PARSEDPushFcGWM_ECGtoIPMA 1;
BA_ "U_CDX74X_MY2024_Tx" SG_ 2612036824 PARSEDPushFcGWM_ECGtoIPMA 1;
BA_ "U_V710_MY2023_Tx" SG_ 2612036824 PARSEDPushFcGWM_ECGtoIPMA 1;
BA_ "U_P702_MY2024_Tx" SG_ 2612036824 PARSEDPushFcGWM_ECGtoIPMA 1;
BA_ "GenSigStartValue" SG_ 1123 GpsUtcMnth_No_Actl 1;
BA_ "GenSigStartValue" SG_ 1123 GpsUtcDay_No_Actl 1;
BA_ "GenSigSendType" SG_ 2612030680 PARSEDPushFcGWM_ECGtoGSM 3;
BA_ "ECGUsedTxSignal" SG_ 2612030680 PARSEDPushFcGWM_ECGtoGSM 1;
BA_ "U_P708_MY2023_Tx" SG_ 2612030680 PARSEDPushFcGWM_ECGtoGSM 1;
BA_ "U_P702_MY2024_Tx" SG_ 2612030680 PARSEDPushFcGWM_ECGtoGSM 1;
BA_ "GenSigStartValue" SG_ 531 VehStop_D_Stat 2;
BA_ "U_P708_MY2023_Rx" SG_ 531 VehStop_D_Stat 1;
BA_ "U_V710_MY2023_Rx" SG_ 531 VehStop_D_Stat 1;
BA_ "U_P702_MY2024_Rx" SG_ 531 VehStop_D_Stat 1;
BA_ "U_P708_MY2023_Rx" SG_ 531 TracCtlPtActv_B_Actl 1;
BA_ "U_V710_MY2023_Rx" SG_ 531 TracCtlPtActv_B_Actl 1;
BA_ "U_P702_MY2024_Rx" SG_ 531 TracCtlPtActv_B_Actl 1;
BA_ "WakeupSignal" SG_ 531 PrkBrkYwLamp_D_Rq 1;
BA_ "WakeupSignal" SG_ 531 PrkBrkRedLamp_D_Rq 1;
BA_ "U_V713N_MY2022_Rx" SG_ 531 AbsActv_B_Actl 1;
BA_ "U_P708_MY2023_Rx" SG_ 531 AbsActv_B_Actl 1;
BA_ "U_CDX74X_MY2024_Rx" SG_ 531 AbsActv_B_Actl 1;
BA_ "U_V710_MY2023_Rx" SG_ 531 AbsActv_B_Actl 1;
BA_ "U_P702_MY2024_Rx" SG_ 531 AbsActv_B_Actl 1;
BA_ "U_V713N_MY2022_Rx" SG_ 531 StabCtlBrkActv_B_Actl 1;
BA_ "U_P708_MY2023_Rx" SG_ 531 StabCtlBrkActv_B_Actl 1;
BA_ "U_CDX74X_MY2024_Rx" SG_ 531 StabCtlBrkActv_B_Actl 1;
BA_ "U_V710_MY2023_Rx" SG_ 531 StabCtlBrkActv_B_Actl 1;
BA_ "U_P702_MY2024_Rx" SG_ 531 StabCtlBrkActv_B_Actl 1;
BA_ "U_P708_MY2023_Rx" SG_ 531 CmbbBrkPrchg_B_Actl 1;
BA_ "U_V710_MY2023_Rx" SG_ 531 CmbbBrkPrchg_B_Actl 1;
BA_ "U_P702_MY2024_Rx" SG_ 531 CmbbBrkPrchg_B_Actl 1;
BA_ "U_P708_MY2023_Rx" SG_ 531 CmbbBrkDecel_B_Actl 1;
BA_ "U_V710_MY2023_Rx" SG_ 531 CmbbBrkDecel_B_Actl 1;
BA_ "U_P702_MY2024_Rx" SG_ 531 CmbbBrkDecel_B_Actl 1;
BA_ "U_P708_MY2023_Rx" SG_ 531 CmbbBaSensInc_B_Actl 1;
BA_ "U_V710_MY2023_Rx" SG_ 531 CmbbBaSensInc_B_Actl 1;
BA_ "U_P702_MY2024_Rx" SG_ 531 CmbbBaSensInc_B_Actl 1;
BA_ "U_P708_MY2023_Rx" SG_ 531 AccBrkWarm_B_Actl 1;
BA_ "U_V710_MY2023_Rx" SG_ 531 AccBrkWarm_B_Actl 1;
BA_ "U_P702_MY2024_Rx" SG_ 531 AccBrkWarm_B_Actl 1;
BA_ "U_P708_MY2023_Rx" SG_ 531 AccBrkTotTqMn_B_Actl 1;
BA_ "U_V710_MY2023_Rx" SG_ 531 AccBrkTotTqMn_B_Actl 1;
BA_ "U_P702_MY2024_Rx" SG_ 531 AccBrkTotTqMn_B_Actl 1;
BA_ "U_P708_MY2023_Rx" SG_ 531 AccBrkPrchgActv_B_Actl 1;
BA_ "U_V710_MY2023_Rx" SG_ 531 AccBrkPrchgActv_B_Actl 1;
BA_ "U_P702_MY2024_Rx" SG_ 531 AccBrkPrchgActv_B_Actl 1;
BA_ "U_P708_MY2023_Rx" SG_ 531 AccBrkDis_B_Actl 1;
BA_ "U_V710_MY2023_Rx" SG_ 531 AccBrkDis_B_Actl 1;
BA_ "U_P702_MY2024_Rx" SG_ 531 AccBrkDis_B_Actl 1;
BA_ "U_P708_MY2023_Rx" SG_ 531 AccBrkDeny_B_Actl 1;
BA_ "U_V710_MY2023_Rx" SG_ 531 AccBrkDeny_B_Actl 1;
BA_ "U_P702_MY2024_Rx" SG_ 531 AccBrkDeny_B_Actl 1;
BA_ "U_P708_MY2023_Rx" SG_ 531 AccBrkActv_B_Actl 1;
BA_ "U_V710_MY2023_Rx" SG_ 531 AccBrkActv_B_Actl 1;
BA_ "U_P702_MY2024_Rx" SG_ 531 AccBrkActv_B_Actl 1;
BA_ "U_P708_MY2023_Rx" SG_ 531 CmbbBrkDis_B_Actl 1;
BA_ "U_CDX74X_MY2024_Rx" SG_ 531 CmbbBrkDis_B_Actl 1;
BA_ "U_V710_MY2023_Rx" SG_ 531 CmbbBrkDis_B_Actl 1;
BA_ "U_P702_MY2024_Rx" SG_ 531 CmbbBrkDis_B_Actl 1;
BA_ "U_P708_MY2023_Rx" SG_ 531 CmbbDeny_B_ActlBrk 1;
BA_ "U_CDX74X_MY2024_Rx" SG_ 531 CmbbDeny_B_ActlBrk 1;
BA_ "U_V710_MY2023_Rx" SG_ 531 CmbbDeny_B_ActlBrk 1;
BA_ "U_P702_MY2024_Rx" SG_ 531 CmbbDeny_B_ActlBrk 1;
BA_ "U_P708_MY2023_Rx" SG_ 531 VehLongOvrGnd_A_Est 1;
BA_ "U_V710_MY2023_Rx" SG_ 531 VehLongOvrGnd_A_Est 1;
BA_ "U_P702_MY2024_Rx" SG_ 531 VehLongOvrGnd_A_Est 1;
BA_ "U_P708_MY2023_Rx" SG_ 531 AccStopActv_B_ActlBrk 1;
BA_ "U_V710_MY2023_Rx" SG_ 531 AccStopActv_B_ActlBrk 1;
BA_ "U_P702_MY2024_Rx" SG_ 531 AccStopActv_B_ActlBrk 1;
BA_ "U_P708_MY2023_Rx" SG_ 531 AccDis_B_ActlEpb 1;
BA_ "U_V710_MY2023_Rx" SG_ 531 AccDis_B_ActlEpb 1;
BA_ "U_P702_MY2024_Rx" SG_ 531 AccDis_B_ActlEpb 1;
BA_ "WakeupSignal" SG_ 531 PrkBrkMsgTxt_D_Rq 1;
BA_ "GenSigStartValue" SG_ 531 PrkBrkStatus 7;
BA_ "U_P708_MY2023_Rx" SG_ 531 PrkBrkStatus 1;
BA_ "U_V710_MY2023_Rx" SG_ 531 PrkBrkStatus 1;
BA_ "U_P702_MY2024_Rx" SG_ 531 PrkBrkStatus 1;
BA_ "U_P708_MY2023_Rx" SG_ 517 FapLc_B_Err 1;
BA_ "U_V710_MY2023_Rx" SG_ 517 FapLc_B_Err 1;
BA_ "U_P702_MY2024_Rx" SG_ 517 FapLc_B_Err 1;
BA_ "MetaData" SG_ 516 ApedPosPcActl_No_Cs 1;
BA_ "GenSigStartValue" SG_ 516 EngAoutNActl_D_QF 1;
BA_ "MetaData" SG_ 516 EngAoutNActl_D_QF 1;
BA_ "MetaData" SG_ 516 ApedPosPcActl_No_Cnt 1;
BA_ "U_P708_MY2023_Rx" SG_ 516 ApedPos_Pc_ActlArb 1;
BA_ "U_P702_MY2024_Rx" SG_ 516 ApedPos_Pc_ActlArb 1;
BA_ "U_CDX74X_MY2024_Rx" SG_ 516 ApedPos_Pc_ActlArb 1;
BA_ "U_V710_MY2023_Rx" SG_ 516 ApedPos_Pc_ActlArb 1;
BA_ "MetaData" SG_ 516 ApedPosPcActl_D_Qf 1;
BA_ "GenSigStartValue" SG_ 516 ApedPosPcActl_D_Qf 1;
BA_ "U_P708_MY2023_Rx" SG_ 516 ApedPosPcActl_D_Qf 1;
BA_ "U_CDX74X_MY2024_Rx" SG_ 516 ApedPosPcActl_D_Qf 1;
BA_ "U_V710_MY2023_Rx" SG_ 516 ApedPosPcActl_D_Qf 1;
BA_ "U_P702_MY2024_Rx" SG_ 516 ApedPosPcActl_D_Qf 1;
BA_ "U_P708_MY2023_Rx" SG_ 516 EngAout_N_Actl 1;
BA_ "U_CDX74X_MY2024_Rx" SG_ 516 EngAout_N_Actl 1;
BA_ "U_V710_MY2023_Rx" SG_ 516 EngAout_N_Actl 1;
BA_ "U_P702_MY2024_Rx" SG_ 516 EngAout_N_Actl 1;
BA_ "U_V710_MY2023_Rx" SG_ 514 VehVActlEng_No_Cnt 1;
BA_ "U_CDX74X_MY2024_Rx" SG_ 514 VehVActlEng_No_Cnt 1;
BA_ "MetaData" SG_ 514 VehVActlEng_No_Cnt 1;
BA_ "U_V710_MY2023_Rx" SG_ 514 VehVActlEng_No_Cs 1;
BA_ "U_CDX74X_MY2024_Rx" SG_ 514 VehVActlEng_No_Cs 1;
BA_ "MetaData" SG_ 514 VehVActlEng_No_Cs 1;
BA_ "U_P708_MY2023_Rx" SG_ 514 VehVTrlrAid_B_Avail 1;
BA_ "U_V710_MY2023_Rx" SG_ 514 VehVTrlrAid_B_Avail 1;
BA_ "U_P708_MY2023_Rx" SG_ 514 Veh_V_RqCcSet 1;
BA_ "U_V710_MY2023_Rx" SG_ 514 Veh_V_RqCcSet 1;
BA_ "U_P702_MY2024_Rx" SG_ 514 Veh_V_RqCcSet 1;
BA_ "MetaData" SG_ 514 VehVActlEng_D_Qf 1;
BA_ "U_P708_MY2023_Rx" SG_ 514 VehVActlEng_D_Qf 1;
BA_ "U_CDX74X_MY2024_Rx" SG_ 514 VehVActlEng_D_Qf 1;
BA_ "U_V710_MY2023_Rx" SG_ 514 VehVActlEng_D_Qf 1;
BA_ "U_P702_MY2024_Rx" SG_ 514 VehVActlEng_D_Qf 1;
BA_ "U_P708_MY2023_Rx" SG_ 514 Veh_V_ActlEng 1;
BA_ "U_CDX74X_MY2024_Rx" SG_ 514 Veh_V_ActlEng 1;
BA_ "U_V710_MY2023_Rx" SG_ 514 Veh_V_ActlEng 1;
BA_ "U_P702_MY2024_Rx" SG_ 514 Veh_V_ActlEng 1;
BA_ "GenSigStartValue" SG_ 514 GearRvrse_D_Actl 7;
BA_ "U_P708_MY2023_Rx" SG_ 514 GearRvrse_D_Actl 1;
BA_ "U_CDX74X_MY2024_Rx" SG_ 514 GearRvrse_D_Actl 1;
BA_ "U_V710_MY2023_Rx" SG_ 514 GearRvrse_D_Actl 1;
BA_ "U_P702_MY2024_Rx" SG_ 514 GearRvrse_D_Actl 1;
BA_ "U_V713N_MY2022_Rx" SG_ 514 GearRvrse_D_Actl 1;
BA_ "U_P708_MY2023_Rx" SG_ 512 PtDrvMde_D_Stat 1;
BA_ "U_V710_MY2023_Rx" SG_ 512 PtDrvMde_D_Stat 1;
BA_ "U_P702_MY2024_Rx" SG_ 512 PtDrvMde_D_Stat 1;
BA_ "MetaData" SG_ 376 AirAmbTe_D_Qf 1;
BA_ "GenSigStartValue" SG_ 376 AirAmbTe_D_Qf 1;
BA_ "U_P708_MY2023_Rx" SG_ 376 AirAmbTe_D_Qf 1;
BA_ "U_V710_MY2023_Rx" SG_ 376 AirAmbTe_D_Qf 1;
BA_ "U_P702_MY2024_Rx" SG_ 376 AirAmbTe_D_Qf 1;
BA_ "U_P708_MY2023_Rx" SG_ 376 AirAmb_Te_ActlFilt 1;
BA_ "U_V710_MY2023_Rx" SG_ 376 AirAmb_Te_ActlFilt 1;
BA_ "U_P702_MY2024_Rx" SG_ 376 AirAmb_Te_ActlFilt 1;
BA_ "U_P708_MY2023_Rx" SG_ 376 AirAmb_Te_Actl 1;
BA_ "U_P702_MY2024_Rx" SG_ 376 AirAmb_Te_Actl 1;
BA_ "U_P708_MY2023_Tx" SG_ 1229 TrlrIspCnnct_D_Stat 1;
BA_ "U_P702_MY2024_Tx" SG_ 1229 TrlrIspCnnct_D_Stat 1;
BA_ "U_P708_MY2023_Tx" SG_ 1229 TrlrCamraView_D_Rq 1;
BA_ "U_P702_MY2024_Tx" SG_ 1229 TrlrCamraView_D_Rq 1;
BA_ "GenSigSendType" SG_ 1229 DrOpenPrvntRight_B_Rq 3;
BA_ "U_P708_MY2023_Tx" SG_ 1229 DrOpenPrvntRight_B_Rq 1;
BA_ "U_P702_MY2024_Tx" SG_ 1229 DrOpenPrvntRight_B_Rq 1;
BA_ "GenSigSendType" SG_ 1229 DrOpenPrvntLeft_B_Rq 3;
BA_ "U_P708_MY2023_Tx" SG_ 1229 DrOpenPrvntLeft_B_Rq 1;
BA_ "U_P702_MY2024_Tx" SG_ 1229 DrOpenPrvntLeft_B_Rq 1;
BA_ "GenSigSendType" SG_ 1229 ExitNotClrRight_B_Stat 3;
BA_ "U_P708_MY2023_Tx" SG_ 1229 ExitNotClrRight_B_Stat 1;
BA_ "U_V710_MY2023_Tx" SG_ 1229 ExitNotClrRight_B_Stat 1;
BA_ "U_P702_MY2024_Tx" SG_ 1229 ExitNotClrRight_B_Stat 1;
BA_ "GenSigSendType" SG_ 1229 ExitNotClrLeft_B_Stat 3;
BA_ "U_P708_MY2023_Tx" SG_ 1229 ExitNotClrLeft_B_Stat 1;
BA_ "U_V710_MY2023_Tx" SG_ 1229 ExitNotClrLeft_B_Stat 1;
BA_ "U_P702_MY2024_Tx" SG_ 1229 ExitNotClrLeft_B_Stat 1;
BA_REL_ "SC_Verification" BU_SG_REL_ GWM SG_ 394 FcwMemStat_B_Actl 1;
BA_REL_ "SC_Verification" BU_SG_REL_ GWM SG_ 394 FcwMemSens_D_Actl 1;
BA_REL_ "SC_Verification" BU_SG_REL_ GWM SG_ 394 FcwAudioWarn_B_Rq 1;
BA_REL_ "SC_Verification" BU_SG_REL_ GWM SG_ 391 CmbbBrkPrchg_D_Rq 1;
BA_REL_ "SC_Verification" BU_SG_REL_ PSCM SG_ 1034 VehicleGGCCData 1;
BA_REL_ "SC_Verification" BU_SG_REL_ IPMA_ADAS SG_ 1034 VehicleGGCCData 1;
BA_REL_ "SC_Verification" BU_SG_REL_ IPMA_ADAS SG_ 534 WhlDirRr_D_Actl 1;
BA_REL_ "SC_Verification" BU_SG_REL_ IPMA_ADAS SG_ 534 WhlDirRl_D_Actl 1;
BA_REL_ "SC_Verification" BU_SG_REL_ IPMA_ADAS SG_ 534 WhlDirFr_D_Actl 1;
BA_REL_ "SC_Verification" BU_SG_REL_ IPMA_ADAS SG_ 534 WhlDirFl_D_Actl 1;
BA_REL_ "SC_Verification" BU_SG_REL_ IPMA_ADAS SG_ 125 BrkTot_Tq_RqArb 1;
BA_REL_ "SC_Verification" BU_SG_REL_ IPMA_ADAS SG_ 119 VehOverGnd_V_Est 1;
BA_REL_ "SC_Verification" BU_SG_REL_ IPMA_ADAS SG_ 119 VehYawComp_W_Actl 1;
BA_REL_ "SC_Verification" BU_SG_REL_ DDM SG_ 154 TronTripCnt_No_Actl 1;
BA_REL_ "SC_Verification" BU_SG_REL_ PDM SG_ 154 TronTripCnt_No_Actl 1;
BA_REL_ "SC_Verification" BU_SG_REL_ HCM SG_ 154 TronTripCnt_No_Actl 1;
BA_REL_ "SC_Verification" BU_SG_REL_ IPMA_ADAS SG_ 154 TronTripCnt_No_Actl 1;
BA_REL_ "SC_Verification" BU_SG_REL_ PSCM SG_ 154 TronTripCnt_No_Actl 1;
BA_REL_ "SC_Verification" BU_SG_REL_ DDM SG_ 154 TronResetCnt_No_Actl 1;
BA_REL_ "SC_Verification" BU_SG_REL_ PDM SG_ 154 TronResetCnt_No_Actl 1;
BA_REL_ "SC_Verification" BU_SG_REL_ HCM SG_ 154 TronResetCnt_No_Actl 1;
BA_REL_ "SC_Verification" BU_SG_REL_ IPMA_ADAS SG_ 154 TronResetCnt_No_Actl 1;
BA_REL_ "SC_Verification" BU_SG_REL_ PSCM SG_ 154 TronResetCnt_No_Actl 1;
BA_REL_ "SC_Verification" BU_SG_REL_ IPMA_ADAS SG_ 535 WhlRr_W_Meas 1;
BA_REL_ "SC_Verification" BU_SG_REL_ PSCM SG_ 535 WhlRr_W_Meas 1;
BA_REL_ "SC_Verification" BU_SG_REL_ IPMA_ADAS SG_ 535 WhlRl_W_Meas 1;
BA_REL_ "SC_Verification" BU_SG_REL_ PSCM SG_ 535 WhlRl_W_Meas 1;
BA_REL_ "SC_Verification" BU_SG_REL_ IPMA_ADAS SG_ 535 WhlFr_W_Meas 1;
BA_REL_ "SC_Verification" BU_SG_REL_ PSCM SG_ 535 WhlFr_W_Meas 1;
BA_REL_ "SC_Verification" BU_SG_REL_ IPMA_ADAS SG_ 535 WhlFl_W_Meas 1;
BA_REL_ "SC_Verification" BU_SG_REL_ PSCM SG_ 535 WhlFl_W_Meas 1;
BA_REL_ "SC_Verification" BU_SG_REL_ IPMA_ADAS SG_ 531 VehStop_D_Stat 1;
BA_REL_ "SC_Verification" BU_SG_REL_ IPMA_ADAS SG_ 531 TracCtlPtActv_B_Actl 1;
BA_REL_ "SC_Verification" BU_SG_REL_ IPMA_ADAS SG_ 531 AbsActv_B_Actl 1;
BA_REL_ "SC_Verification" BU_SG_REL_ IPMA_ADAS SG_ 531 StabCtlBrkActv_B_Actl 1;
BA_REL_ "SC_Verification" BU_SG_REL_ IPMA_ADAS SG_ 531 CmbbBrkPrchg_B_Actl 1;
BA_REL_ "SC_Verification" BU_SG_REL_ IPMA_ADAS SG_ 531 CmbbBrkDecel_B_Actl 1;
BA_REL_ "SC_Verification" BU_SG_REL_ IPMA_ADAS SG_ 531 CmbbBaSensInc_B_Actl 1;
BA_REL_ "SC_Verification" BU_SG_REL_ IPMA_ADAS SG_ 531 AccBrkWarm_B_Actl 1;
BA_REL_ "SC_Verification" BU_SG_REL_ IPMA_ADAS SG_ 531 AccBrkDis_B_Actl 1;
BA_REL_ "SC_Verification" BU_SG_REL_ IPMA_ADAS SG_ 531 AccBrkDeny_B_Actl 1;
BA_REL_ "SC_Verification" BU_SG_REL_ IPMA_ADAS SG_ 531 AccBrkActv_B_Actl 1;
BA_REL_ "SC_Verification" BU_SG_REL_ IPMA_ADAS SG_ 531 CmbbBrkDis_B_Actl 1;
BA_REL_ "SC_Verification" BU_SG_REL_ IPMA_ADAS SG_ 531 CmbbDeny_B_ActlBrk 1;
BA_REL_ "SC_Verification" BU_SG_REL_ IPMA_ADAS SG_ 531 VehLongOvrGnd_A_Est 1;
BA_REL_ "SC_Verification" BU_SG_REL_ IPMA_ADAS SG_ 531 AccStopActv_B_ActlBrk 1;
BA_REL_ "SC_Verification" BU_SG_REL_ IPMA_ADAS SG_ 531 PrkBrkStatus 1;
BA_REL_ "SC_Verification" BU_SG_REL_ IPMA_ADAS SG_ 516 ApedPos_Pc_ActlArb 1;
BA_REL_ "SC_Verification" BU_SG_REL_ IPMA_ADAS SG_ 516 ApedPosPcActl_D_Qf 1;
BA_REL_ "SC_Verification" BU_SG_REL_ IPMA_ADAS SG_ 514 Veh_V_RqCcSet 1;
BA_REL_ "SC_Verification" BU_SG_REL_ HCM SG_ 514 VehVActlEng_D_Qf 1;
BA_REL_ "SC_Verification" BU_SG_REL_ IPMA_ADAS SG_ 514 VehVActlEng_D_Qf 1;
BA_REL_ "SC_Verification" BU_SG_REL_ HCM SG_ 514 Veh_V_ActlEng 1;
BA_REL_ "SC_Verification" BU_SG_REL_ IPMA_ADAS SG_ 514 Veh_V_ActlEng 1;
BA_REL_ "SC_Verification" BU_SG_REL_ IPMA_ADAS SG_ 514 GearRvrse_D_Actl 1;
VAL_ 394 AccTrgDist2_D_Dsply 15 "DIST_ACTIVE_13_Farthest" 14 "DIST_ACTIVE_12" 13 "DIST_ACTIVE_11" 12 "DIST_ACTIVE_10" 11 "DIST_ACTIVE_9" 10 "DIST_ACTIVE_8" 9 "DIST_ACTIVE_7" 8 "DIST_ACTIVE_6" 7 "DIST_ACTIVE_5" 6 "DIST_ACTIVE_4" 5 "DIST_ACTIVE_3" 4 "DIST_ACTIVE_2" 3 "DIST_ACTIVE_1_Closest" 2 "DIST_ACTIVE_No_Target" 1 "DIST_STANDBY" 0 "DIST_OFF" ;
VAL_ 394 AccStopRes_B_Dsply 1 "Yes" 0 "No" ;
VAL_ 394 TjaWarn_D_Rq 7 "HardTakeOverEyesOff" 6 "SoftTakeOverEyesOff" 5 "HaLaneDeptWarningLeft" 4 "HaLaneDeptWarningRight" 3 "HardTakeOverLevel2" 2 "HardTakeOverLevel1" 1 "TrafficJamAssistCancel" 0 "NoWarning" ;
VAL_ 394 Tja_D_Stat 7 "ExtendedActive" 6 "ActiveWarningRight" 5 "ActiveWarningLeft" 4 "ActiveInterventionRight" 3 "ActiveInterventionLeft" 2 "Active" 1 "Standby" 0 "Off" ;
VAL_ 394 TjaMsgTxt_D_Dsply 7 "Disclaimer" 6 "SmartOffering" 5 "HaSelected" 4 "HaUnavailable" 3 "TurnOnAdaptCruiseControl" 2 "TrafficJamAssistSelected" 1 "TrafficJamAssistUnavailabl" 0 "NoMessage" ;
VAL_ 394 IaccLamp_D_Rq 3 "NotUsed_2" 2 "NotUsed_1" 1 "DisplayIaccIcon" 0 "DoNotDisplayIaccIcon" ;
VAL_ 394 AccMsgTxt_D2_Rq 15 "Brakes_Warm" 14 "NCC_Enabled_Warning" 13 "IACC_TJA_Selected" 12 "ACC_TJA_Selected" 11 "IACC_Selected" 10 "Press_Brake_To_Hold" 9 "Only_Following_In_Low_Spd" 8 "TJA_Unavailable" 7 "Shift_Down" 6 "IACC_Unavailable" 5 "ACC_Selected" 4 "ACC_Overridden" 3 "Brake_Capacity_Warning" 2 "ACC_Cancelled" 1 "ACC_Unavailable" 0 "No_Text" ;
VAL_ 394 FcwDeny_B_Dsply 1 "Yes" 0 "No" ;
VAL_ 394 FcwMemStat_B_Actl 1 "On" 0 "Off" ;
VAL_ 394 AccTGap_B_Dsply 1 "Yes" 0 "No" ;
VAL_ 394 CadsAlignIncplt_B_Actl 1 "Yes" 0 "No" ;
VAL_ 394 AccFllwMde_B_Dsply 1 "Yes" 0 "No" ;
VAL_ 394 CadsRadrBlck_B_Actl 1 "Yes" 0 "No" ;
VAL_ 394 CmbbPostEvnt_B_Dsply 1 "Yes" 0 "No" ;
VAL_ 394 AccStopMde_B_Dsply 1 "Yes" 0 "No" ;
VAL_ 394 FcwMemSens_D_Actl 3 "FCW_Sensitivity_3" 2 "FCW_Sensitivity_2" 1 "FCW_Sensitivity_1" 0 "Not_Used" ;
VAL_ 394 FcwMsgTxt_D_Rq 7 "Undefined_3" 6 "Undefined_2" 5 "Low_Visibility" 4 "Unavailable_DueTo_LowSpeed" 3 "Available" 2 "Unavailable" 1 "Off" 0 "No_Text" ;
VAL_ 394 AccWarn_D_Dsply 3 "BrakeReleaseWarn_In_StopMd" 2 "Brake_Capacity_Warning" 1 "Cancel_Warning" 0 "No_Warning" ;
VAL_ 394 FcwVisblWarn_B_Rq 1 "On" 0 "Off" ;
VAL_ 394 FcwAudioWarn_B_Rq 1 "On" 0 "Off" ;
VAL_ 394 AccTGap_D_Dsply 7 "Undefined_2" 6 "Undefined_1" 5 "Time_Gap_5" 4 "Time_Gap_4" 3 "Time_Gap_3" 2 "Time_Gap_2" 1 "Time_Gap_1" 0 "Not_Used" ;
VAL_ 394 AccMemEnbl_B_RqDrv 1 "Adaptive_Cruise" 0 "Normal_Cruise" ;
VAL_ 394 AccStopStat_D_Dsply 3 "PressResume" 2 "Stopped" 1 "ResumeReady" 0 "NoDisplay" ;
VAL_ 391 HudBlk3_B_Rq 1 "Yes" 0 "No" ;
VAL_ 391 HudBlk2_B_Rq 1 "Yes" 0 "No" ;
VAL_ 391 HudBlk1_B_Rq 1 "Yes" 0 "No" ;
VAL_ 391 HudFlashRate_D_Actl 3 "Unused" 2 "Flash_4Hz_50Prct_DutyCycle" 1 "On" 0 "Off" ;
VAL_ 391 CmbbBrkPrchg_D_Rq 3 "Undefined" 2 "Level_2_PreCharge_Request" 1 "Level_1_PreCharge_Request" 0 "No_PreCharge_Request" ;
VAL_ 391 CmbbBrkDecel_B_Rq 1 "Yes" 0 "No" ;
VAL_ 391 CmbbBaSens_D_Rq 3 "Level_3" 2 "Level_2" 1 "Level_1" 0 "Normal" ;
VAL_ 390 AccBrkPrkEl_B_Rq 1 "Yes" 0 "No" ;
VAL_ 390 Cmbb_B_Enbl 1 "Yes" 0 "No" ;
VAL_ 390 CmbbOvrrd_B_RqDrv 1 "Yes" 0 "No" ;
VAL_ 390 CmbbDeny_B_Actl 1 "Yes" 0 "No" ;
VAL_ 390 CmbbEngTqMn_B_Rq 1 "Yes" 0 "No" ;
VAL_ 390 AccDeny_B_Rq 1 "Yes" 0 "No" ;
VAL_ 390 AccResumEnbl_B_Rq 1 "Yes" 0 "No" ;
VAL_ 390 AccCancl_B_Rq 1 "Yes" 0 "No" ;
VAL_ 390 AccBrkPrchg_B_Rq 1 "Yes" 0 "No" ;
VAL_ 390 AccBrkDecel_B_Rq 1 "Active" 0 "Inactive" ;
VAL_ 390 AccStopStat_B_Rq 1 "Yes" 0 "No" ;
VAL_ 390 AccAutoResum_D_Rq 3 "NotUsed" 2 "Active" 1 "Pending" 0 "Off" ;
VAL_ 390 AccBrkPulse_B_Rq 1 "True" 0 "False" ;
VAL_ 130 TrlrHitchLamp_D_Rqst 1 "On" 0 "Off" ;
VAL_ 130 VehVTrlrAid_B_Rq 1 "Request" 0 "NoRequest" ;
VAL_ 130 SteEffort_D_Stat 7 "NotUsed_3" 6 "NotUsed_2" 5 "NotUsed_1" 4 "SpecialMode_2" 3 "SpecialMode_1" 2 "Comfort" 1 "Sport" 0 "Normal" ;
VAL_ 130 SteMdule_D_Stat 7 "NotUsed" 6 "EPAS_Failure3" 5 "EPAS_Failure2" 4 "System_Failure" 3 "EPAS_Shutdown" 2 "Normal_Op_Full_Assist" 1 "Normal_Op_Limited_Assist" 0 "EPAS_Initialization" ;
VAL_ 130 SteMdule_U_Meas 255 "Invalid" ;
VAL_ 130 SteMdule_I_Est 4095 "Invalid" ;
VAL_ 130 EPAS_Failure 3 "SERVICE_POWER_STEERING_NOW" 2 "SERVICE_POWER_STEERING" 1 "POWER_STRG_ASSIST_FAULT" 0 "EPAS_OK_NO_MESSAGE" ;
VAL_ 130 SteeringColumnTorque 255 "Invalid" 254 "Unknown" ;
VAL_ 130 SAPPAngleControlStat6 1 "RequestedAngleNotReached" 0 "RequestedAngleCanBeReached" ;
VAL_ 130 SAPPAngleControlStat5 1 "StrgColTorqueExceed_EAROn" 0 "ExternalSigContentOKforEAC" ;
VAL_ 130 SAPPAngleControlStat4 1 "SpeedLimitExceededEAROn" 0 "ExternalSigContentOKforEAC" ;
VAL_ 130 SAPPAngleControlStat3 1 "EARactiveNoReverseEngage" 0 "ExternalSigContentOKforEAC" ;
VAL_ 130 SAPPAngleControlStat2 1 "Rel_ExtSteeringAngleReqx" 0 "NoRel_ExtSteeringAngleReqx" ;
VAL_ 130 SAPPAngleControlStat1 3 "Fault" 2 "Active" 1 "Open" 0 "Closed" ;
VAL_ 894 RmtCtlTrgt_D_Rq 3 "NotUsed" 2 "Null" 1 "RemoteParkAssist" 0 "ManeuverId" ;
VAL_ 894 RmtCtlRngSet_D_Stat 3 "NotUsed" 2 "RangeSetB" 1 "RangeSetA" 0 "None" ;
VAL_ 894 RmtCtlKeySrch_D_Stat 3 "NotUsed" 2 "Valid" 1 "Invalid" 0 "Null" ;
VAL_ 894 RmtCtlBody_D_Stat 15 "NotUsed_6" 14 "NotUsed_5" 13 "NotUsed_4" 12 "NotUsed_3" 11 "NotUsed_2" 10 "NotUsed_1" 9 "Shutdown" 8 "ManeuverFinished" 7 "ReadyForResume" 6 "Pause" 5 "Maneuvering" 4 "ReadyForManeuvering" 3 "Activation" 2 "Initialize" 1 "Preparation" 0 "Disabled" ;
VAL_ 894 RmtCtl_D_RqBody 7 "NotUsed_2" 6 "NotUsed_1" 5 "Error" 4 "Abort" 3 "PauseKeypad" 2 "PauseHazard" 1 "PauseDoorHandle" 0 "Null" ;
VAL_ 611 AwdSys_D_Stat 3 "Faulty" 2 "NotUsed" 1 "_4x4_L_H_Active" 0 "_4x4_L_H_Inactive" ;
VAL_ 611 SelDrvMdeAwd_D_Stat 0 "NotAvailable" 1 "Available" 2 "TemporarilyNotAvailable" 3 "Faulty" ;
VAL_ 611 AwdStat_D_RqDsply 31 "Rear_Diff_Lock_Not_Avail" 30 "_4wd_Lock_Required" 29 "Cfg_Perf_Redc_See_Manual" 28 "To_Engage_4x4_Release_Aped" 27 "To_Engage_4x4_Slow_To_3MPH" 26 "Shift_To_Neutral" 25 "Lkr_Mode_Unavail_TMS" 24 " _4x4_Mode_Unavail_TMS" 23 "Out_of_4Low_Crawl" 22 "AWD_PTU_Oil_Changed" 21 "Change_AWD_PTU_Oil" 20 "Neutral_Tow_Disabled" 19 "Neutral_Tow_Enabled" 18 "AWD_OFF" 17 "_4x4_Off_Road_Speed" 16 "_4x4_Extreme_Off_Road_Mode" 15 "_4x4_Exiting_Off_Road" 14 "_4x4_Off_Road_Mode" 10 "_4x4_Locked_Temporarily" 9 "Shift_In_Progress" 13 "Blocked_Shift_Assist" 12 "_4x4_Auto_Restored" 11 "_4x4_Disabled_Temporarily" 7 "Out_of_4Low__Neutral" 6 "Out_of_4Low__Brake" 5 "Out_of_4Low__Speed" 4 "Into_4Low__Clutch" 3 "Into_4Low__Neutral" 2 "Into_4Low__Brake" 1 "Into_4Low__Speed" 0 "Normal__No_Message" 8 "Out_of_4Low__Clutch" ;
VAL_ 611 AwdLck_D_Stat 9 "Undefined" 8 "Under_External_Torque_Ctrl" 7 "Torque_Limited_by_Cmd" 6 "Fully_Locked_by_Cmd" 5 "Disabled" 4 "Warning" 3 "Fault" 2 "Inactive" 1 "Completely_Opened_by_Cmd" 0 "OK" ;
VAL_ 611 AwdSrvcRqd_B_Rq 1 "On" 0 "Off" ;
VAL_ 611 NtrlTowAvail_B_Stat 1 "Available" 0 "NotAvailable" ;
VAL_ 611 AwdLck_Tq_Rq 4095 "Fault" 4094 "Unknown" ;
VAL_ 611 AwdLoLamp_D_RqDsply 3 "Not_Used" 2 "Flash" 1 "On" 0 "Off" ;
VAL_ 611 AwdHiLamp_D_RqDsply 3 "Not_Used" 2 "Flash" 1 "On" 0 "Off" ;
VAL_ 611 AwdAutoLamp_D_RqDsply 3 "Not_Used" 2 "Flash" 1 "On" 0 "Off" ;
VAL_ 611 Awd2wdLamp_D_RqDsply 3 "Not_Used" 2 "Flash" 1 "On" 0 "Off" ;
VAL_ 611 AwdRnge_D_Actl 7 "Unknown" 6 "High_Range_2wd" 5 "High_Range_Auto" 4 "High_Range_Locked" 3 "Neutral" 2 "Low_Range_2wd" 1 "Low_Range_Auto" 0 "Low_Range_Locked" ;
VAL_ 534 WhlDirRr_D_Actl 3 "Faulty" 2 "NoDataExists" 1 "Backward" 0 "Forward" ;
VAL_ 534 WhlDirRl_D_Actl 3 "Faulty" 2 "NoDataExists" 1 "Backward" 0 "Forward" ;
VAL_ 534 WhlDirFr_D_Actl 3 "Faulty" 2 "NoDataExists" 1 "Backward" 0 "Forward" ;
VAL_ 534 WhlDirFl_D_Actl 3 "Faulty" 2 "NoDataExists" 1 "Backward" 0 "Forward" ;
VAL_ 533 ExtLghtRvrseOn_B_Rq 1 "On" 0 "Off" ;
VAL_ 533 ClrExitAsstEnbl_D_RqMnu 3 "NotUsed" 0 "Inactive" 2 "Enable" 1 "Disable" ;
VAL_ 533 TrlrAidMde_D_Rq 3 "Mode_3" 2 "Mode_2" 1 "Mode_1" 0 "NoRequest" ;
VAL_ 533 TCU_Init_Actvtn_St 3 "NotUsed" 2 "InitialActivateDeny" 1 "InitialActivateAccept" 0 "Invalid" ;
VAL_ 533 TCU_Final_Actvtn_St 3 "NotUsed" 2 "FinalActivateDeny" 1 "FinalActivateAccept" 0 "Invalid" ;
VAL_ 533 OtaTrg_D_Stat 3 "NotUsed_1" 2 "Accepted" 1 "NotAccepted" 0 "Null" ;
VAL_ 533 OnbChrgGoTTouch_D_Rq 3 "NotUsed" 2 "On" 1 "Off" 0 "Null" ;
VAL_ 533 OnbChrgGoTPrcond_D_Rq 3 "High" 2 "Medium" 1 "Low" 0 "Off" ;
VAL_ 533 OnbChrgGoTOn_D_Rq 3 "NotUsed" 2 "On" 1 "Off" 0 "Null" ;
VAL_ 533 OnbChrgGoTMnte_D_Rq 15 "NotUsed_4" 14 "NotUsed_3" 13 "NotUsed_2" 12 "NotUsed_1" 11 "Minute_55" 10 "Minute_50" 9 "Minute_45" 8 "Minute_40" 7 "Minute_35" 6 "Minute_30" 5 "Minute_25" 4 "Minute_20" 3 "Minute_15" 2 "Minute_10" 1 "Minute_5" 0 "Minute_0" ;
VAL_ 533 OnbChrgGoTHr_T_Rq 31 "Faulty" 30 "NoDataExists" ;
VAL_ 533 OnbChrgGoTExtHtr_D_Rq 3 "NotUsed" 2 "On" 1 "Off" 0 "Null" ;
VAL_ 533 OnbChrgGoTDelete_B_Rq 1 "Request" 0 "NoRequest" ;
VAL_ 533 OnbChrgClearAll_B_Rq 1 "Request" 0 "NoRequest" ;
VAL_ 533 PaakMyKey_D_Rq 3 "NotUsed" 2 "ConfirmNewPaakMyKey" 1 "RequestNewPaakMyKey" 0 "None" ;
VAL_ 533 DcacPw_D_Rq 3 "High" 2 "Low" 1 "Off" 0 "Null" ;
VAL_ 533 DcacPwReset_B_Rq 1 "Reset" 0 "Null" ;
VAL_ 533 AutoEpbZoomView_B_Stat 1 "Active" 0 "Inactive" ;
VAL_ 533 AutoEpbButtn_B_Stat 1 "Pressed" 0 "Not_Pressed" ;
VAL_ 533 TrlrAlarmButtn_B_Stat 1 "On" 0 "Off" ;
VAL_ 533 LghtAmbDrvMde_D_Rq 3 "NotUsed" 2 "Automatic" 1 "Manual" 0 "Null" ;
VAL_ 533 DcacPwLoButtn_B_Stat 1 "Pressed" 0 "Not_Pressed" ;
VAL_ 533 DcacPwOffButtn_B_Stat 1 "Pressed" 0 "Not_Pressed" ;
VAL_ 533 DcacPwHiButtn_B_Stat 1 "Pressed" 0 "Not_Pressed" ;
VAL_ 533 DcacPwResetButtn_B_Stat 1 "Pressed" 0 "Not_Pressed" ;
VAL_ 533 DcacPwButtn_B_Falt 1 "Faulted" 0 "NotFaulted" ;
VAL_ 533 DcacMdeButtn_B_Stat 1 "Pressed" 0 "Not_Pressed" ;
VAL_ 533 DcacGfciTestBttn_B_Stat 1 "Pressed" 0 "Not_Pressed" ;
VAL_ 533 OnbChrgGoTUpdate_B_Rq 1 "Request" 0 "NoRequest" ;
VAL_ 533 DcacPwButtn_B_Stat 1 "Pressed" 0 "Not_Pressed" ;
VAL_ 533 TrlrHitch_D_RqMnu 15 "NotUsed_10" 14 "NotUsed_9" 13 "NotUsed_8" 12 "NotUsed_7" 11 "NotUsed_6" 10 "NotUsed_5" 9 "NotUsed_4" 8 "NotUsed_3" 7 "NotUsed_2" 6 "NotUsed_1" 5 "GoToTraileringDomain" 4 "Confirm" 3 "TurnOnTba" 2 "TurnOnAutohitch" 1 "CancelAutohitch" 0 "NoRequest" ;
VAL_ 92 GearSelLck_D_Rq 3 "PreventionBlocker" 2 "Unlock" 1 "Lock" 0 "Null" ;
VAL_ 92 TrnValidGear_D_Cnfm 3 "Accept" 2 "Reject" 1 "Internal_Request" 0 "No_Command" ;
VAL_ 92 TrnGearMsgTxt2_D_Rq 31 "Message31" 30 "Message30" 29 "Message29" 28 "Message28" 27 "Message27" 26 "Message26" 25 "Message25" 24 "Message24" 23 "Message23" 22 "Message22" 21 "Message21" 20 "Message20" 19 "Message19" 18 "Message18" 17 "Message17" 16 "Message16" 15 "Message15" 14 "Message14" 13 "Message13" 12 "Message12" 11 "Message11" 10 "Message10" 9 "Message9" 8 "Message8" 7 "Message7" 6 "Message6" 5 "Message5" 4 "Message4" 3 "Message3" 2 "Message2" 1 "Message1" 0 "NoMessage" ;
VAL_ 92 TrnGearNtmAllow_B_Stat 1 "Yes" 0 "No" ;
VAL_ 92 TrnDtpCmd_D_Actl 7 "NotUsed4" 6 "NotUsed3" 5 "NotUsed2" 4 "Relatch" 3 "Deploy" 2 "Self_Test" 1 "No_Command" 0 "NotUsed1" ;
VAL_ 92 TrnNtrlTowCmd_D_Actl 3 "NotUsed" 2 "Neutral_Tow_Entry" 1 "Car_Wash_Mode" 0 "Normal_Mode" ;
VAL_ 92 TrnGearCmd_Pc_ActlPt 1023 "Fault" ;
VAL_ 92 TrnGear_D_RqPt 7 "Fault" 6 "NotUsed" 5 "Manual" 4 "Drive" 3 "Neutral" 2 "Reverse" 1 "Park" 0 "No_Gear" ;
VAL_ 92 TrnCmdState_B_Actl 1 "Yes" 0 "No" ;
VAL_ 92 PrkBrkActv_D_RqTrnGear 3 "NotUsed2" 2 "RequestParkBrakeEngage" 1 "NoRequest" 0 "NotUsed1" ;
VAL_ 92 TrnGearMsgTxt_D_Rq 15 "Message_15" 14 "Message_14" 13 "Message_13" 12 "Message_12" 11 "Message_11" 10 "Message_10" 9 "Message_9" 8 "Message_8" 7 "Message_7" 6 "Message_6" 5 "Message_5" 4 "Message_4" 3 "Message_3" 2 "Message_2" 1 "Message_1" 0 "NoMessage" ;
VAL_ 570 SuspRearRight_L_Actl 511 "Faulty" ;
VAL_ 570 SuspFrntRight_L_Actl 511 "Faulty" ;
VAL_ 570 SuspRear_L_Prev 511 "Fault" ;
VAL_ 570 SuspRear_L_Actl 511 "Fault" ;
VAL_ 570 SuspFrnt_L_Prev 511 "Fault" ;
VAL_ 570 SuspFrnt_L_Actl 511 "Fault" ;
VAL_ 131 HeadLghtHiCtrl_D_RqAhb 7 "NotUsed2" 6 "NotUsed1" 5 "Auto_HiBeam" 4 "Auto_LoBeam" 3 "Flash" 2 "Man_HiBeam" 1 "Man_LoBeam" 0 "Null" ;
VAL_ 131 AhbStat_B_Dsply 1 "On" 0 "Off" ;
VAL_ 131 WiprFrontSwtch_D_Stat 15 "NotUsed6" 14 "NotUsed5" 13 "NotUsed4" 12 "NotUsed3" 11 "NotUsed2" 10 "NotUsed1" 9 "PositionNotDetermined" 8 "High" 7 "Low" 6 "Position6" 5 "Position5" 4 "Position4" 3 "Position3" 2 "Position2" 1 "Position1" 0 "Off" ;
VAL_ 131 HeadLghtHiOn_B_StatAhb 1 "On" 0 "Off" ;
VAL_ 131 HeadLghtHiFlash_D_Actl 3 "NotUsed" 2 "High" 1 "Flash_to_Pass" 0 "Null" ;
VAL_ 131 TjaButtnOnOffPress 1 "Pressed" 0 "Not_Pressed" ;
VAL_ 131 AccButtnGapTogglePress 1 "Pressed" 0 "Not_Pressed" ;
VAL_ 131 WiprFront_D_Stat 15 "NO_DATA_EXISTS" 14 "STALLED" 13 "RESERVED" 12 "AUTO_ADJUST" 11 "COURTESYWIPE" 10 "AUTO_HIGH" 9 "AUTO_LOW" 8 "WASH" 7 "MIST_FLICK" 6 "MAN_HIGH" 5 "MAN_LOW" 4 "MAN_INT_ON" 3 "MAN_INT_OFF" 2 "OFF_MOVING" 1 "AUTO_OFF" 0 "OFF" ;
VAL_ 131 TurnLghtSwtch_D_Stat 3 "Unused_Treat_As_Off" 2 "Right" 1 "Left" 0 "Off" ;
VAL_ 131 LghtAmb_D_Sns 7 "No_Data_Exists" 6 "Unused2" 5 "Unused1" 4 "Tunnel_Off" 3 "Tunnel_On" 2 "Twilight" 1 "Light" 0 "Dark" ;
VAL_ 131 AccButtnGapIncPress 1 "Button_Pressed" 0 "Button_Not_Pressed" ;
VAL_ 131 AccButtnGapDecPress 1 "Button_Pressed" 0 "Button_Not_Pressed" ;
VAL_ 131 AslButtnOnOffPress 1 "Button_Pressed" 0 "Button_Not_Pressed" ;
VAL_ 131 AslButtnOnOffCnclPress 1 "Button_Pressed" 0 "Button_Not_Pressed" ;
VAL_ 131 CcButtnOnPress 1 "Button_Pressed" 0 "Button_Not_Pressed" ;
VAL_ 131 CcButtnOnOffPress 1 "Button_Pressed" 0 "Button_Not_Pressed" ;
VAL_ 131 CcButtnOnOffCnclPress 1 "Button_Pressed" 0 "Button_Not_Pressed" ;
VAL_ 131 CcButtnOffPress 1 "Button_Pressed" 0 "Button_Not_Pressed" ;
VAL_ 131 CcAsllButtnResPress 1 "Button_Pressed" 0 "Button_Not_Pressed" ;
VAL_ 131 CcAslButtnSetPress 1 "Button_Pressed" 0 "Button_Not_Pressed" ;
VAL_ 131 CcAslButtnSetIncPress 1 "Button_Pressed" 0 "Button_Not_Pressed" ;
VAL_ 131 CcAslButtnSetDecPress 1 "Button_Pressed" 0 "Button_Not_Pressed" ;
VAL_ 131 CcAslButtnResIncPress 1 "Button_Pressed" 0 "Button_Not_Pressed" ;
VAL_ 131 CcAslButtnResDecPress 1 "Button_Pressed" 0 "Button_Not_Pressed" ;
VAL_ 131 CcAslButtnOnPress 1 "Button_Pressed" 0 "Button_Not_Pressed" ;
VAL_ 131 CcAslButtnOnOffCncl 1 "Button_Pressed" 0 "Button_Not_Pressed" ;
VAL_ 131 CcAslButtnOffCnclPress 1 "Button_Pressed" 0 "Button_Not_Pressed" ;
VAL_ 131 CcAslButtnIndxIncPress 1 "Button_Pressed" 0 "Button_Not_Pressed" ;
VAL_ 131 CcAslButtnIndxDecPress 1 "Button_Pressed" 0 "Button_Not_Pressed" ;
VAL_ 131 CcAslButtnDeny_B_Actl 1 "Yes" 0 "No" ;
VAL_ 131 CcAslButtnCnclResPress 1 "Button_Pressed" 0 "Button_Not_Pressed" ;
VAL_ 131 CcAslButtnCnclPress 1 "Button_Pressed" 0 "Button_Not_Pressed" ;
VAL_ 131 LaSwtchPos_D_Stat 3 "Fault" 2 "Unused" 1 "Pressed" 0 "Open" ;
VAL_ 125 VehRolComp_W_Actl 4094 "NoDataExists" 4095 "Fault" ;
VAL_ 125 VehVertComp_A_Actl 1022 "NoDataExists" 1023 "Fault" ;
VAL_ 125 BrkTot_Tq_RqArb 8191 "Fault" 8190 "Unknown" ;
VAL_ 125 BrkTot_Tq_Actl 8191 "Fault" 8190 "Unknown" ;
VAL_ 125 HsaStat_D_Actl 7 "Faulty" 6 "FaultyWithDriverIndication" 5 "SlowRelease" 4 "FastRelease" 3 "ActiveBrakePedalReleased" 2 "ActiveBrakePedalPressed" 1 "FindingGradient" 0 "Inactive" ;
VAL_ 119 VehTrvlDir_D_Stat 7 "Faulty" 6 "NoDataExists" 5 "NotUsed2" 4 "NotUsed1" 3 "Reverse" 2 "LikelyReverse" 1 "Forward" 0 "LikelyForward" ;
VAL_ 119 VehOverGnd_V_Est 65535 "Invalid" 65534 "Unknown" ;
VAL_ 119 VehLongComp_A_Actl 1023 "Fault" 1022 "NoDataExists" ;
VAL_ 119 VehLatComp_A_Actl 1023 "Fault" 1022 "NoDataExists" ;
VAL_ 119 VehYawComp_W_Actl 4095 "Fault" 4094 "NoDataExists" ;
VAL_ 118 BrkCtrFnd_B_Stat 1 "Yes" 0 "No" ;
VAL_ 118 BrkTerrMdeChng_D_Rdy 7 "Fault" 6 "Undefined_2" 5 "Undefined_1" 4 "ModeUnavailDrInputRqd" 3 "SpOpModes_NotSupported" 2 "ModeUnavailDynamicCond" 1 "Module_In_Initialization" 0 "Mode_Change_Available" ;
VAL_ 118 BrkTerrMde_D_Actl 7 "Fail_Safe_Default" 6 "Dynamic_Mode" 5 "Rock_Crawl_Mode" 4 "Mud_Ruts_Mode" 3 "Sand_Mode" 2 "Undefined" 1 "Low_Mu_Mode" 0 "Special_Operating_Mode_Off" ;
VAL_ 118 EmgcyBrkLamp_D_Rq 3 "NotUsed" 2 "Active_at_standstill" 1 "Active_at_speed" 0 "Inactive" ;
VAL_ 118 StopLamp_B_RqBrk 1 "Active" 0 "Inactive" ;
VAL_ 118 SteWhlCompAnEst_D_Qf 3 "OK" 2 "Not_Within_Specifications" 1 "No_Data_Exists" 0 "Faulty" ;
VAL_ 1071 EngMnfld3_P_Actl 255 "Faulty" 254 "NoDataExists" ;
VAL_ 1071 CluPdlPosPcMeas_D_Qf 3 "OK" 2 "Not_Within_Specifications" 1 "No_Data_Exists" 0 "Faulty" ;
VAL_ 942 ApaOffOptnSel_B_Avail 1 "Available" 0 "NotAvailable" ;
VAL_ 942 ApaSlotOption_B_Avail 1 "Available" 0 "NotAvailable" ;
VAL_ 942 ApaSlotAlrtSet_B_Stat 1 "Enable" 0 "Disable" ;
VAL_ 942 ApaSlotAlrt_B_Rq 1 "True" 0 "False" ;
VAL_ 942 ApaRmtFeatSel_B_Avail 1 "Available" 0 "NotAvailable" ;
VAL_ 942 ApaParkOutSel_B_Avail 1 "Available" 0 "NotAvailable" ;
VAL_ 942 ApaSys_D2_Stat 15 "NotUsed_5" 14 "NotUsed_4" 13 "NotUsed_3" 12 "NotUsed_2" 11 "NotUsed_1" 10 "NoSideSelectable" 9 "RightSideSelectable" 8 "LeftSideSelectable" 7 "BothSidesSelectable" 6 "Faulty" 5 "Finished" 4 "Cancelled" 3 "NotAvailable" 2 "Overspeed" 1 "Pause" 0 "NormalOperation" ;
VAL_ 942 ApaSlotTrgt_D_Stat 15 "NotUsed_7" 14 "NotUsed_6" 13 "NotUsed_5" 12 "NotUsed_4" 11 "NotUsed_3" 10 "NotUsed_2" 9 "NotUsed_1" 8 "Front" 7 "Rear" 6 "Right3" 5 "Right2" 4 "Right1" 3 "Left3" 2 "Left2" 1 "Left1" 0 "None" ;
VAL_ 942 ApaParkInSel_B_Avail 1 "Available" 0 "NotAvailable" ;
VAL_ 942 ApaMsgTxt_D2_Stat 15 "ReducedFunction" 14 "TrailerFeatureNotAvailable" 13 "AcceleratorPedalInactive" 12 "SensorsBlocked" 11 "TrailerAttached" 10 "TcsDeactivated" 9 "WheelSlip" 8 "HighInclination" 7 "DoorOpen" 6 "SteeringInteraction" 5 "WrongDirection" 4 "SpeedLimitExceeded" 3 "BrakeEvent" 2 "ObstacleInPath" 1 "WaitForSteering" 0 "None" ;
VAL_ 942 ApaDynmcSlot_B_Stat 1 "On" 0 "Off" ;
VAL_ 942 ApaDisplayMode_D_Stat 3 "NotUsed" 2 "FullScreen" 1 "Menu" 0 "Off" ;
VAL_ 942 ApaControlMode_D_Stat 1 "Active" 0 "Inactive" ;
VAL_ 942 PrkBrkElRleas_B_RqApa 1 "Yes" 0 "No" ;
VAL_ 942 PrkAidAcsyRear_D_Stat 3 "NotUsed" 2 "On" 1 "Off" 0 "Null" ;
VAL_ 942 PrkAidAcsyFront_D_Stat 3 "NotUsed" 2 "On" 1 "Off" 0 "Null" ;
VAL_ 942 PrkAidDrvDir_D_Stat 7 "NotUsed_2" 6 "NotUsed_1" 5 "BackwardNegative" 4 "ForwardNegative" 3 "BackwardPositive" 2 "ForwardPositive" 1 "NoMotion" 0 "DirectionNotKnown" ;
VAL_ 942 ApaDrvRq2MsgTxt_D_Rq 15 "NotUsed_7" 14 "NotUsed_6" 13 "NotUsed_5" 12 "NotUsed_4" 11 "NotUsed_3" 10 "NotUsed_2" 9 "NotUsed_1" 8 "CloseDoor" 7 "TakeControl" 6 "ReleaseEpb" 5 "ReleaseSteering" 4 "ReleaseBrake" 3 "DriveBackward" 2 "DriveForward" 1 "Stop" 0 "NoRequest" ;
VAL_ 942 ApaDrvRq1MsgTxt_D_Rq 7 "NotUsed" 6 "ExitVehicle" 5 "PressApaButton" 4 "ShiftToP" 3 "ShiftToN" 2 "ShiftToD" 1 "ShiftToR" 0 "NoRequest" ;
VAL_ 939 DrTgateMde_D_Stat 3 "NotUsed_1" 2 "Up" 1 "Down" 0 "NotAvailable" ;
VAL_ 939 SidePrkSnsR4_D_Stat 15 "NotUsed" 14 "NotFullyScannedYet" 13 "NoObjectInSector" 12 "Zone12" 11 "Zone11" 10 "Zone10" 9 "Zone9" 8 "Zone8" 7 "Zone7" 6 "Zone6" 5 "Zone5" 4 "Zone4" 3 "Zone3" 2 "Zone2" 1 "Zone1" 0 "Off" ;
VAL_ 939 SidePrkSnsR3_D_Stat 15 "NotUsed" 14 "NotFullyScannedYet" 13 "NoObjectInSector" 12 "Zone12" 11 "Zone11" 10 "Zone10" 9 "Zone9" 8 "Zone8" 7 "Zone7" 6 "Zone6" 5 "Zone5" 4 "Zone4" 3 "Zone3" 2 "Zone2" 1 "Zone1" 0 "Off" ;
VAL_ 939 SidePrkSnsL4_D_Stat 15 "NotUsed" 14 "NotFullyScannedYet" 13 "NoObjectInSector" 12 "Zone12" 11 "Zone11" 10 "Zone10" 9 "Zone9" 8 "Zone8" 7 "Zone7" 6 "Zone6" 5 "Zone5" 4 "Zone4" 3 "Zone3" 2 "Zone2" 1 "Zone1" 0 "Off" ;
VAL_ 939 SidePrkSnsL3_D_Stat 15 "NotUsed" 14 "NotFullyScannedYet" 13 "NoObjectInSector" 12 "Zone12" 11 "Zone11" 10 "Zone10" 9 "Zone9" 8 "Zone8" 7 "Zone7" 6 "Zone6" 5 "Zone5" 4 "Zone4" 3 "Zone3" 2 "Zone2" 1 "Zone1" 0 "Off" ;
VAL_ 939 PrkAidChime_D_Stat 3 "Fault" 2 "No_Data_Exists" 1 "On" 0 "Off" ;
VAL_ 939 PrkAidSnsRlCntr_D_Stat 15 "Zone_15" 14 "Zone_14" 13 "Zone_13" 12 "Zone_12" 11 "Zone_11" 10 "Zone_10" 9 "Zone_9" 8 "Zone_8" 7 "Zone_7" 6 "Zone_6" 5 "Zone_5" 4 "Zone_4" 3 "Zone_3" 2 "Zone_2" 1 "Zone_1" 0 "Off" ;
VAL_ 939 PrkAidSnsRrCrnr_D_Stat 15 "Zone_15" 14 "Zone_14" 13 "Zone_13" 12 "Zone_12" 11 "Zone_11" 10 "Zone_10" 9 "Zone_9" 8 "Zone_8" 7 "Zone_7" 6 "Zone_6" 5 "Zone_5" 4 "Zone_4" 3 "Zone_3" 2 "Zone_2" 1 "Zone_1" 0 "Off" ;
VAL_ 939 PrkAidSnsRrCntr_D_Stat 15 "Zone_15" 14 "Zone_14" 13 "Zone_13" 12 "Zone_12" 11 "Zone_11" 10 "Zone_10" 9 "Zone_9" 8 "Zone_8" 7 "Zone_7" 6 "Zone_6" 5 "Zone_5" 4 "Zone_4" 3 "Zone_3" 2 "Zone_2" 1 "Zone_1" 0 "Off" ;
VAL_ 939 PrkAidSnsRlCrnr_D_Stat 15 "Zone_15" 14 "Zone_14" 13 "Zone_13" 12 "Zone_12" 11 "Zone_11" 10 "Zone_10" 9 "Zone_9" 8 "Zone_8" 7 "Zone_7" 6 "Zone_6" 5 "Zone_5" 4 "Zone_4" 3 "Zone_3" 2 "Zone_2" 1 "Zone_1" 0 "Off" ;
VAL_ 939 PrkAidRear_D_Stat 3 "Faulted" 2 "Unused" 1 "Enabled" 0 "Disabled" ;
VAL_ 939 PrkAidFront_D_Stat 3 "Faulted" 2 "Unused" 1 "Enabled" 0 "Disabled" ;
VAL_ 939 PrkAid_D_Falt 7 "NotUsed2" 6 "NotUsed1" 5 "Failure_Front_PSM_Sensors" 4 "No_Data_Exists" 3 "Failure_Rear_Sensors" 2 "Speaker_Fault" 1 "ECU_Fault" 0 "No_Fault" ;
VAL_ 939 ApaLongCtrlEnbl_D_Rq 1 "Enable" 0 "Disable" ;
VAL_ 939 PrkAidLamp_D_Rq 3 "Not_Used" 2 "Flash" 1 "On" 0 "Off" ;
VAL_ 939 ApaBrk_D_Rq 3 "NotUsed" 2 "LowDecel" 1 "HighDecel" 0 "NoRequest" ;
VAL_ 939 ResPrkAidSnsRrSide_D_Stat 15 "Zone_15" 14 "Zone_14" 13 "Zone_13" 12 "Zone_12" 11 "Zone_11" 10 "Zone_10" 9 "Zone_9" 8 "Zone_8" 7 "Zone_7" 6 "Zone_6" 5 "Zone_5" 4 "Zone_4" 3 "Zone_3" 2 "Zone_2" 1 "Zone_1" 0 "Off" ;
VAL_ 939 ResPrkAidSnsRlSide_D_Stat 15 "Zone_15" 14 "Zone_14" 13 "Zone_13" 12 "Zone_12" 11 "Zone_11" 10 "Zone_10" 9 "Zone_9" 8 "Zone_8" 7 "Zone_7" 6 "Zone_6" 5 "Zone_5" 4 "Zone_4" 3 "Zone_3" 2 "Zone_2" 1 "Zone_1" 0 "Off" ;
VAL_ 938 SidePrkSnsR2_D_Stat 15 "NotUsed" 14 "NotFullyScannedYet" 13 "NoObjectInSector" 12 "Zone12" 11 "Zone11" 10 "Zone10" 9 "Zone9" 8 "Zone8" 7 "Zone7" 6 "Zone6" 5 "Zone5" 4 "Zone4" 3 "Zone3" 2 "Zone2" 1 "Zone1" 0 "Off" ;
VAL_ 938 SidePrkSnsR1_D_Stat 15 "NotUsed" 14 "NotFullyScannedYet" 13 "NoObjectInSector" 12 "Zone12" 11 "Zone11" 10 "Zone10" 9 "Zone9" 8 "Zone8" 7 "Zone7" 6 "Zone6" 5 "Zone5" 4 "Zone4" 3 "Zone3" 2 "Zone2" 1 "Zone1" 0 "Off" ;
VAL_ 938 SidePrkSnsL2_D_Stat 15 "NotUsed" 14 "NotFullyScannedYet" 13 "NoObjectInSector" 12 "Zone12" 11 "Zone11" 10 "Zone10" 9 "Zone9" 8 "Zone8" 7 "Zone7" 6 "Zone6" 5 "Zone5" 4 "Zone4" 3 "Zone3" 2 "Zone2" 1 "Zone1" 0 "Off" ;
VAL_ 938 ApaMde_D_Stat 7 "NotUsed" 6 "RePA" 5 "ParkIn" 4 "POA" 3 "PPA" 2 "SAPP" 1 "Off" 0 "Null" ;
VAL_ 938 ApaActvSd_D_Actl 3 "Dirver_Side" 2 "Passenger_Side" 1 "No_Side" 0 "Null" ;
VAL_ 938 PrkAidSwtch_B_Stat 1 "Pressed" 0 "Not_Pressed" ;
VAL_ 938 ApaMde_D_Avail 15 "NotUsed7" 14 "NotUsed6" 13 "NotUsed5" 12 "NotUsed4" 11 "NotUsed3" 10 "NotUsed2" 9 "NotUsed1" 8 "PPA_POA" 7 "SAPP_POA" 6 "POA" 5 "PPA" 4 "SAPP" 3 "SAPP_PPA_POA" 2 "SAPP_PPA" 1 "None" 0 "Null" ;
VAL_ 938 PrkAidSnsFrCrnr_D_Stat 15 "Zone_15" 14 "Zone_14" 13 "Zone_13" 12 "Zone_12" 11 "Zone_11" 10 "Zone_10" 9 "Zone_9" 8 "Zone_8" 7 "Zone_7" 6 "Zone_6" 5 "Zone_5" 4 "Zone_4" 3 "Zone_3" 2 "Zone_2" 1 "Zone_1" 0 "Off" ;
VAL_ 938 PrkAidSnsFrCntr_D_Stat 15 "Zone_15" 14 "Zone_14" 13 "Zone_13" 12 "Zone_12" 11 "Zone_11" 10 "Zone_10" 9 "Zone_9" 8 "Zone_8" 7 "Zone_7" 6 "Zone_6" 5 "Zone_5" 4 "Zone_4" 3 "Zone_3" 2 "Zone_2" 1 "Zone_1" 0 "Off" ;
VAL_ 938 PrkAidSnsFlCrnr_D_Stat 15 "Zone_15" 14 "Zone_14" 13 "Zone_13" 12 "Zone_12" 11 "Zone_11" 10 "Zone_10" 9 "Zone_9" 8 "Zone_8" 7 "Zone_7" 6 "Zone_6" 5 "Zone_5" 4 "Zone_4" 3 "Zone_3" 2 "Zone_2" 1 "Zone_1" 0 "Off" ;
VAL_ 938 PrkAidSnsFlCntr_D_Stat 15 "Zone_15" 14 "Zone_14" 13 "Zone_13" 12 "Zone_12" 11 "Zone_11" 10 "Zone_10" 9 "Zone_9" 8 "Zone_8" 7 "Zone_7" 6 "Zone_6" 5 "Zone_5" 4 "Zone_4" 3 "Zone_3" 2 "Zone_2" 1 "Zone_1" 0 "Off" ;
VAL_ 938 PrkBrkEl_B_RqFap 1 "Yes" 0 "No" ;
VAL_ 938 RpaChime_D_Rq 15 "Zone15_Chime" 14 "Zone14_Chime" 13 "Zone13_Chime" 12 "Zone12_Chime" 11 "Zone11_Chime" 10 "Zone10_Chime" 9 "Zone9_Chime" 8 "Zone8_Chime" 7 "Zone7_Chime" 6 "Zone6_Chime" 5 "Zone5_Chime" 4 "Zone4_Chime" 3 "Zone3_Chime" 2 "Zone2_Chime" 1 "Zone1_Chime" 0 "No_Chime" ;
VAL_ 938 FpaChime_D_Rq 15 "Zone15_Chime" 14 "Zone14_Chime" 13 "Zone13_Chime" 12 "Zone12_Chime" 11 "Zone11_Chime" 10 "Zone10_Chime" 9 "Zone9_Chime" 8 "Zone8_Chime" 7 "Zone7_Chime" 6 "Zone6_Chime" 5 "Zone5_Chime" 4 "Zone4_Chime" 3 "Zone3_Chime" 2 "Zone2_Chime" 1 "Zone1_Chime" 0 "No_Chime" ;
VAL_ 938 PrkAidMsgTxt_D_Rq 15 "All_Sns_Blk" 14 "R_Sns_ON_F_Sns_Blk" 13 "R_Sns_Blk_F_Sns_ON" 12 "R_Sns_Inactive_Trlr_atch" 11 "Not_Avail_Trlr_attchd" 10 "Fail_Mode_no_Chime" 9 "Fail_Mode_with_Chime" 8 "R_Sns_Trlr_F_Sns_Blk" 7 "NotUsed3" 6 "Park_Sys_Alternate_Mode" 5 "R_Snsrs_On_F_Snsrs_On" 4 "NotUsed2" 3 "Reset_Message_Warn" 2 "R_Snsrs_Off_F_Snsrs_On" 1 "R_Snsrs_On_F_Snsrs_Off" 0 "All_Park_Sensors_Off" ;
VAL_ 938 SidePrkSnsL1_D_Stat 15 "NotUsed" 14 "NotFullyScannedYet" 13 "NoObjectInSector" 12 "Zone12" 11 "Zone11" 10 "Zone10" 9 "Zone9" 8 "Zone8" 7 "Zone7" 6 "Zone6" 5 "Zone5" 4 "Zone4" 3 "Zone3" 2 "Zone2" 1 "Zone1" 0 "Off" ;
VAL_ 938 PrkAidAudioMute_B_Rq 1 "Enable" 0 "Disable" ;
VAL_ 937 TrnRng_D_RqFap 7 "NotUsed3" 6 "NotUsed2" 5 "NotUsed1" 4 "Backwards" 3 "Forwards" 2 "NoMotion" 1 "Immobilize" 0 "NoRequest" ;
VAL_ 937 FapLcDistToObj_L_Actl 255 "Faulty" 254 "NoDataExists" ;
VAL_ 936 ApaSys_D_Stat 7 "Faulty" 6 "Finished" 5 "NotAccessible" 4 "ApaCancelled" 3 "Overspeed" 2 "On" 1 "Off" 0 "Null" ;
VAL_ 936 ApaSteWhl_D_RqDrv 3 "TakeControl" 2 "RemoveHands" 1 "NoRequest" 0 "Null" ;
VAL_ 936 ApaSteScanMde_D_Stat 0 "Null" 1 "NotScanning" 2 "Scanning" 3 "Steering" ;
VAL_ 936 ApaSelSapp_D_Stat 3 "NotConfigured" 2 "NotSelectable" 1 "Selectable" 0 "Null" ;
VAL_ 936 ApaSelPpa_D_Stat 3 "NotConfigured" 2 "NotSelectable" 1 "Selectable" 0 "Null" ;
VAL_ 936 ApaSelPoa_D_Stat 3 "NotConfigured" 2 "NotSelectable" 1 "Selectable" 0 "Null" ;
VAL_ 936 ApaScan_D_Stat 3 "ParkSlotReady" 2 "ParkSlotFound" 1 "NoParkSlot" 0 "Null" ;
VAL_ 936 ApaLongCtl_D_RqDrv 7 "NotUsed3" 6 "NotUsed2" 5 "ReleaseBrake" 4 "DriveBackward" 3 "DriveForward" 2 "Stop" 1 "NoRequest" 0 "Null" ;
VAL_ 936 ApaGearShif_D_RqDrv 7 "NotUSed2" 6 "NotUsed1" 5 "ShiftToP" 4 "ShiftToN" 3 "ShiftToD" 2 "ShiftToR" 1 "NoRequest" 0 "Null" ;
VAL_ 936 ApaActvSide2_D_Stat 3 "NoSide" 2 "Right" 1 "Left" 0 "Null" ;
VAL_ 936 ApaAcsy_D_RqDrv 7 "CloseDoor" 6 "SelectSideRight" 5 "SelectSideLeft" 4 "CheckForObject" 3 "PressApaButton" 2 "SelectSide" 1 "NoRequest" 0 "Null" ;
VAL_ 936 ApaTrgtDist_D_Stat 15 "Step15" 14 "Step14" 13 "Step13" 12 "Step12" 11 "Step11" 10 "Step10" 9 "Step9" 8 "Step8" 7 "Step7" 6 "Step6" 5 "Step5" 4 "Step4" 3 "Step3" 2 "Step2" 1 "Step1" 0 "Off" ;
VAL_ 936 ApaMsgTxt_D_Rq 15 "NotUsed_6" 14 "NotUsed_5" 13 "NotUsed_4" 12 "NotUsed_3" 11 "ReleaseEpb" 10 "TrailerFeatureNotAvailable" 9 "AccelPedalInactive" 8 "WrongDirection" 7 "SteeringInteraction" 6 "BrakingActive" 5 "HighInclination" 4 "SpeedLimitExceeded" 3 "TcsDisabled" 2 "WheelSlip" 1 "None" 0 "Null" ;
VAL_ 936 ApaChime_D_Rq 7 "NotUsed2" 6 "NotUsed1" 5 "Warning_Chime" 4 "Finish_Chime" 3 "Stop_Now_Chime" 2 "Spot_Ready_Chime" 1 "Spot_Found_Chime" 0 "No_Chime" ;
VAL_ 936 EPASExtAngleStatReq 1 "Request" 0 "NoRequest" ;
VAL_ 936 ExtSteeringAngleReq2 32767 "Invalid" 32766 "Unknown" ;
VAL_ 936 ApaButtnPrssd_B_Stat 1 "Pressed" 0 "Not_Pressed" ;
VAL_ 154 TronTripCnt_No_Actl 8388607 "Faulty" 8388606 "NoDataExists" ;
VAL_ 154 TronResetCnt_No_Actl 4194303 "Faulty" 4194302 "NoDataExists" ;
VAL_ 145 VehYawWActl_D_Qf 3 "OK" 2 "Not_Within_Specifications" 1 "No_Data_Exists" 0 "Faulty" ;
VAL_ 145 VehRolWActl_D_Qf 3 "OK" 2 "Not_Within_Specifications" 1 "No_Data_Exists" 0 "Faulty" ;
VAL_ 145 VehYaw_W_Actl 65535 "Faulty" 65534 "NoDataExists" ;
VAL_ 145 VehRol_W_Actl 65535 "Faulty" 65534 "NoDataExists" ;
VAL_ 535 WhlRr_W_Meas 32767 "Fault" 32766 "Unknown" ;
VAL_ 535 WhlRl_W_Meas 32767 "Fault" 32766 "Unknown" ;
VAL_ 535 WhlFr_W_Meas 32767 "Fault" 32766 "Unknown" ;
VAL_ 535 WhlFl_W_Meas 32767 "Fault" 32766 "Unknown" ;
VAL_ 1124 GPS_Vdop 31 "Invalid" 30 "Unknown" ;
VAL_ 1124 GPS_Speed 255 "Invalid" 254 "Unknown" ;
VAL_ 1124 GPS_Sat_num_in_view 31 "Invalid" 30 "Unknown" ;
VAL_ 1124 GPS_MSL_altitude 4095 "Fault" 4094 "Unknown" ;
VAL_ 1124 GPS_Heading 65535 "Fault" 65534 "Unknown" ;
VAL_ 1124 GPS_Hdop 31 "Invalid" 30 "Unknown" ;
VAL_ 1124 GPS_dimension 2 "_3D" 1 "_2D" 0 "No_Fix" ;
VAL_ 1123 GpsUtcYr_No_Actl 31 "Fault" ;
VAL_ 1123 GpsUtcMnth_No_Actl 15 "Fault" ;
VAL_ 1123 GPS_UTC_seconds 63 "Fault" 62 "Unknown" ;
VAL_ 1123 GPS_UTC_minutes 63 "Fault" 62 "Unknown" ;
VAL_ 1123 GPS_UTC_hours 31 "Invalid" 30 "Unknown" ;
VAL_ 1123 GPS_Compass_direction 7 "NorthWest" 6 "West" 5 "SouthWest" 4 "South" 3 "SouthEast" 2 "East" 1 "NorthEast" 0 "North" ;
VAL_ 1123 GPS_Actual_vs_Infer_pos 1 "Inferred_Position" 0 "Actual_Postition" ;
VAL_ 1123 Gps_B_Falt 1 "Yes" 0 "No" ;
VAL_ 1123 GPS_Pdop 31 "Invalid" 30 "Unknown" ;
VAL_ 531 VehStop_D_Stat 3 "Faulty" 2 "NoDataExists" 1 "Yes" 0 "No" ;
VAL_ 531 TracCtlPtActv_B_Actl 1 "Active" 0 "Inactive" ;
VAL_ 531 PrkBrkYwLamp_D_Rq 3 "Fast_Flash" 2 "Slow_Flash" 1 "On" 0 "Off" ;
VAL_ 531 PrkBrkRedLamp_D_Rq 3 "Fast_Flash" 2 "Slow_Flash" 1 "On" 0 "Off" ;
VAL_ 531 VehicleStationary 1 "Yes" 0 "No" ;
VAL_ 531 AbsActv_B_Actl 1 "Yes" 0 "No" ;
VAL_ 531 StabCtlBrkActv_B_Actl 1 "Yes" 0 "No" ;
VAL_ 531 CmbbBrkPrchg_B_Actl 1 "Yes" 0 "No" ;
VAL_ 531 CmbbBrkDecel_B_Actl 1 "Yes" 0 "No" ;
VAL_ 531 CmbbBaSensInc_B_Actl 1 "Yes" 0 "No" ;
VAL_ 531 AccBrkWarm_B_Actl 1 "Yes" 0 "No" ;
VAL_ 531 AccBrkTotTqMn_B_Actl 1 "Yes" 0 "No" ;
VAL_ 531 AccBrkPrchgActv_B_Actl 1 "Yes" 0 "No" ;
VAL_ 531 AccBrkDis_B_Actl 1 "Yes" 0 "No" ;
VAL_ 531 AccBrkDeny_B_Actl 1 "Yes" 0 "No" ;
VAL_ 531 AccBrkActv_B_Actl 1 "Yes" 0 "No" ;
VAL_ 531 PrplDrgCtlActv_B_Actl 1 "Active" 0 "Inactive" ;
VAL_ 531 CmbbBrkDis_B_Actl 1 "Yes" 0 "No" ;
VAL_ 531 CmbbDeny_B_ActlBrk 1 "Yes" 0 "No" ;
VAL_ 531 CcDis_B_Cmd 1 "Yes" 0 "No" ;
VAL_ 531 VehLongOvrGnd_A_Est 1023 "Fault" 1022 "Unknown" ;
VAL_ 531 AccStopActv_B_ActlBrk 1 "Yes" 0 "No" ;
VAL_ 531 AccDis_B_ActlEpb 1 "Yes" 0 "No" ;
VAL_ 531 PrkBrkMsgTxt_D_Rq 15 "Message15" 14 "Message14" 13 "Message13" 12 "Message12" 11 "Message11" 10 "Message10" 9 "Message9" 8 "Message8" 7 "Message7" 6 "Message6" 5 "Message5" 4 "Message4" 3 "Message3" 2 "Message2" 1 "Message1" 0 "No_Message" ;
VAL_ 531 PrkBrkStatus 7 "GeneralFault_MaintenceMode" 6 "ECD_by_Brake_ECU_Active" 5 "EPB_Limphome_Active" 4 "Rear_Caliper_Open" 3 "RWU_By_EPB_Active" 2 "Rear_Caliper_Transition" 1 "Rear_Caliper_Closed" 0 "Not_Supported" ;
VAL_ 517 FapLc_B_Err 1 "Yes" 0 "No" ;
VAL_ 516 EngAoutNActl_D_QF 3 "OK" 2 "Not_Within_Specifications" 1 "No_Data_Exists" 0 "Faulty" ;
VAL_ 516 ApedPos_PcRate_ActlArb 255 "Fault" 254 "Unknown" ;
VAL_ 516 ApedPosPcActl_D_Qf 3 "OK" 2 "Not_Within_Specifications" 1 "No_Data_Exists" 0 "Faulty" ;
VAL_ 514 StrtrMtrDlyStrt_B_Stat 1 "Yes" 0 "No" ;
VAL_ 514 StrtrMtrCtlMsgTxt_D2_Rq 3 "NoRequestPcmStartingMsgCtl" 2 "ShiftToNeutralToStart" 1 "ShiftToParkToStart" 0 "NoRequestBcmStartingMsgCtl" ;
VAL_ 514 StrtrMtrCtlMsgTxt_D_Rq 7 "Start_In_Gear_Allowed" 6 "Pending_Start_Cancelled" 5 "Start_Pending_Please_Wait" 4 "Cranking_Limit_Exceeded" 3 "Press_Brk_and_Shift_to_P_N" 2 "Press_Clutch_and_Brake" 1 "Press_Clutch_To_Start" 0 "No_Display" ;
VAL_ 514 VehVTrlrAid_B_Avail 1 "Yes" 0 "No" ;
VAL_ 514 VehVActlEng_D_Qf 3 "OK" 2 "Not_Within_Specifications" 1 "No_Data_Exists" 0 "Faulty" ;
VAL_ 514 GearRvrse_D_Actl 7 "Fault" 6 "NotUsed_3" 5 "NotUsed_2" 4 "NotUsed_1" 3 "Active_confirmed" 2 "Active_not_confirmed" 1 "Inactive_confirmed" 0 "Inactive_not_confirmed" ;
VAL_ 512 PtDrvMde_D_Stat 15 "Faulty" 14 "NotUsed11" 13 "NotUsed10" 12 "NotUsed9" 11 "NotUsed8" 10 "NotUsed7" 9 "NotUsed6" 8 "Track" 7 "Drag" 6 "Rock" 5 "Baja" 4 "Sand" 3 "TowHaulGradeAssist" 2 "SnowWet" 1 "Sport" 0 "Normal" ;
VAL_ 376 AirAmb_P_Actl 63 "Fault" 62 "NoDataExists" ;
VAL_ 376 AslChime_B_Rq 1 "Yes" 0 "No" ;
VAL_ 376 EcssLamp_D_RqDsply 3 "Not_Used" 2 "Flash" 1 "On" 0 "Off" ;
VAL_ 376 AslIconDsply_D_Rq 3 "On_Passive_Overridden" 2 "On_Active" 1 "On_Passive" 0 "Off" ;
VAL_ 376 DynoMde_B_Cmd 1 "DynomometerMode" 0 "NormalOperation" ;
VAL_ 376 GasPrtc_D_RqDsply 7 "NotUsed_5" 6 "NotUsed_4" 5 "NotUsed_3" 4 "NotUsed_2" 3 "NotUsed_1" 2 "GpfOverLimit" 1 "GpfAtLimit" 0 "NormalOperation" ;
VAL_ 376 AirAmbTe_D_Qf 3 "OK" 2 "Not_Within_Specifications" 1 "No_Data_Exists" 0 "Faulty" ;
VAL_ 1229 TrlrIspCnnct_D_Stat 3 "NotUsed_2" 2 "NotUsed_1" 1 "Connected" 0 "NotConnected" ;
VAL_ 1229 DrOpenPrvntRight_B_Rq 1 "True" 0 "False" ;
VAL_ 1229 DrOpenPrvntLeft_B_Rq 1 "True" 0 "False" ;
VAL_ 1229 ExitNotClrRight_B_Stat 1 "True" 0 "False" ;
VAL_ 1229 ExitNotClrLeft_B_Stat 1 "True" 0 "False" ;
